VERSION ""

NS_ :

BS_:

BU_: WRCS SRS LECM3 LECM1 ECUspare6 CMS CIOM CCM AlcoLock2

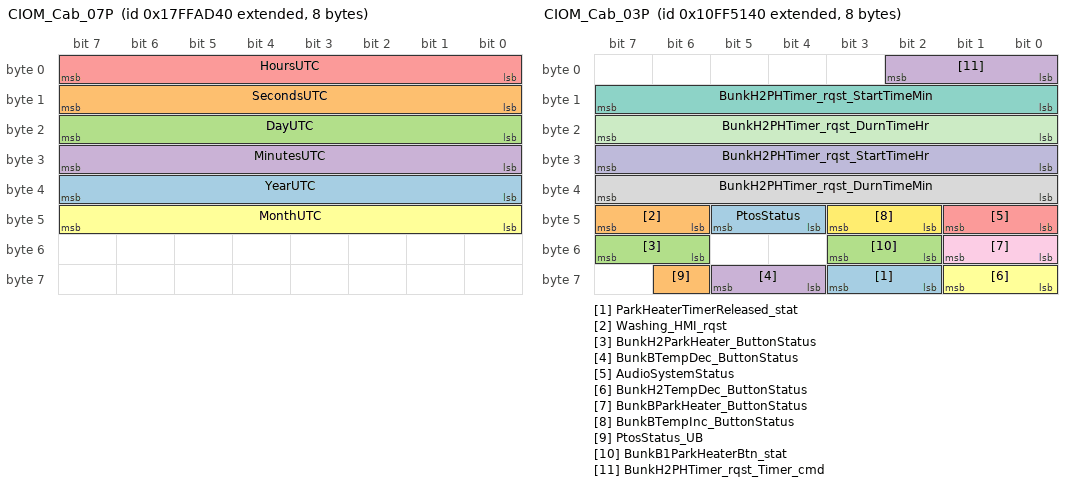
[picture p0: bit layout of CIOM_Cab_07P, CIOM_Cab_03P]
BO_ 2550115648 CIOM_Cab_07P: 8 CIOM
 SG_ YearUTC : 32|8@1+ (1,1985) [1985|2240] "Years"  LECM1,LECM3,WRCS,CMS,SRS,CCM,AlcoLock2
 SG_ SecondsUTC : 8|8@1+ (0.25,0) [0|63.75] "s"  LECM1,WRCS,CCM,LECM3,CMS,AlcoLock2,SRS
 SG_ DayUTC : 16|8@1+ (0.25,0) [0|63.75] "Days"  WRCS,CMS,LECM3,AlcoLock2,SRS,LECM1,CCM
 SG_ MinutesUTC : 24|8@1+ (1,0) [0|255] "min"  LECM1,LECM3,CCM,WRCS,SRS,CMS,AlcoLock2
 SG_ HoursUTC : 0|8@1+ (1,0) [0|255] "h"  CMS,LECM1,WRCS,LECM3,SRS,CCM,AlcoLock2
 SG_ MonthUTC : 40|8@1+ (1,0) [0|255] "Months"  WRCS,SRS,CCM,AlcoLock2,CMS,LECM3,LECM1

BO_ 2432669248 CIOM_Cab_06P: 8 CIOM
 SG_ AuxSwitchBbLoad2_Status : 22|2@1+ (1,0) [0|0] ""  WRCS
 SG_ DoorLock_stat : 24|4@1+ (1,0) [0|0] ""  LECM1,WRCS,CMS
 SG_ PSWindowPosition : 8|3@1+ (1,0) [0|0] ""  CCM
 SG_ AuxSwitchBbLoad1_Status : 14|2@1+ (1,0) [0|0] ""  WRCS
 SG_ ReducedLoadMode_stat : 0|2@1+ (1,0) [0|0] ""  CCM
 SG_ TrailersConnected : 58|3@1+ (1,0) [0|7] "Count"  WRCS,CMS
 SG_ DriverDoorAjar_stat : 4|3@1+ (1,0) [0|0] ""  CCM
 SG_ AuxSwitchBbLoad6_Status : 56|2@1+ (1,0) [0|0] ""  WRCS
 SG_ BunkBacklightCmd : 32|5@1+ (1,0) [0|0] ""  LECM1
 SG_ AuxSwitchBbLoad4_Status : 46|2@1+ (1,0) [0|0] ""  WRCS
 SG_ DSWindowPosition : 11|3@1+ (1,0) [0|0] ""  CCM
 SG_ SelectedLanguage_stat : 40|6@1+ (1,0) [0|0] ""  LECM1,WRCS
 SG_ PassengerDoorAjar_stat : 19|3@1+ (1,0) [0|0] ""  CCM
 SG_ BunkB1ParkHeaterTempSw_stat : 16|3@1+ (1,0) [0|0] ""  CCM
 SG_ AuxSwitchBbLoad5_Status : 54|2@1+ (1,0) [0|0] ""  WRCS
 SG_ AuxSwitchBbLoad3_Status : 37|2@1+ (1,0) [0|0] ""  WRCS
 SG_ BunkH2TempInc_ButtonStatus : 2|2@1+ (1,0) [0|0] ""  CCM
 SG_ AudioVolumeIndicationCmd : 48|6@1+ (1,0) [0|63] "Step"  LECM3,LECM1
 SG_ DayOfWeek_stat : 28|4@1+ (1,0) [0|0] ""  CCM,LECM1

BO_ 2432651584 CIOM_Cab_03P: 8 CIOM
 SG_ ParkHeaterTimerReleased_stat : 58|2@1+ (1,0) [0|0] ""  CCM
 SG_ Washing_HMI_rqst : 46|2@1+ (1,0) [0|0] ""  CCM
 SG_ BunkH2ParkHeater_ButtonStatus : 54|2@1+ (1,0) [0|0] ""  CCM
 SG_ BunkBTempDec_ButtonStatus : 60|2@1+ (1,0) [0|0] ""  CCM
 SG_ AudioSystemStatus : 40|2@1+ (1,0) [0|0] ""  LECM3,LECM1
 SG_ BunkH2TempDec_ButtonStatus : 56|2@1+ (1,0) [0|0] ""  CCM
 SG_ BunkH2PHTimer_rqst_StartTimeMin : 8|8@1+ (1,0) [0|255] "min"  CCM
 SG_ BunkH2PHTimer_rqst_DurnTimeMin : 32|8@1+ (1,0) [0|255] "min"  CCM
 SG_ BunkBParkHeater_ButtonStatus : 48|2@1+ (1,0) [0|0] ""  CCM
 SG_ BunkH2PHTimer_rqst_StartTimeHr : 24|8@1+ (1,0) [0|255] "h"  CCM
 SG_ BunkH2PHTimer_rqst_DurnTimeHr : 16|8@1+ (1,0) [0|255] "h"  CCM
 SG_ BunkBTempInc_ButtonStatus : 42|2@1+ (1,0) [0|0] ""  CCM
 SG_ PtosStatus : 44|2@1+ (1,0) [0|0] ""  CCM
 SG_ PtosStatus_UB : 62|1@1+ (1,0) [0|0] ""  CCM
 SG_ BunkB1ParkHeaterBtn_stat : 50|2@1+ (1,0) [0|0] ""  CCM
 SG_ BunkH2PHTimer_rqst_Timer_cmd : 0|3@1+ (1,0) [0|0] ""  CCM

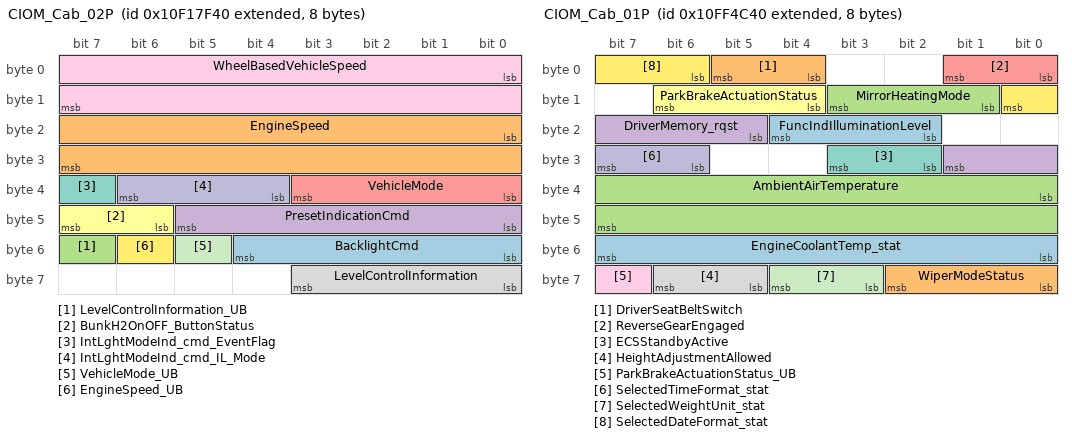
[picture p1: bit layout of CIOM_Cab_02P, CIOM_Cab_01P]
BO_ 2431745856 CIOM_Cab_02P: 8 CIOM
 SG_ BacklightCmd : 48|5@1+ (1,0) [0|0] ""  CMS,CCM
 SG_ EngineSpeed : 16|16@1+ (0.125,0) [0|8191.875] "rpm"  WRCS,CCM,SRS
 SG_ LevelControlInformation_UB : 55|1@1+ (1,0) [0|0] ""  WRCS
 SG_ PresetIndicationCmd : 40|6@1+ (1,0) [0|63] "Enumeration"  LECM1
 SG_ VehicleMode : 32|4@1+ (1,0) [0|0] ""  LECM3,WRCS,LECM1,CMS,CCM,SRS
 SG_ BunkH2OnOFF_ButtonStatus : 46|2@1+ (1,0) [0|0] ""  CCM
 SG_ IntLghtModeInd_cmd_EventFlag : 39|1@1+ (1,0) [0|0] ""  LECM1
 SG_ LevelControlInformation : 56|4@1+ (1,0) [0|0] ""  WRCS
 SG_ WheelBasedVehicleSpeed : 0|16@1+ (0.00390625,0) [0|255.99609375] "Km_per_h"  CMS,CCM,SRS,WRCS
 SG_ IntLghtModeInd_cmd_IL_Mode : 36|3@1+ (1,0) [0|0] ""  LECM1
 SG_ VehicleMode_UB : 53|1@1+ (1,0) [0|0] ""  CCM,LECM3,WRCS,SRS,LECM1,CMS
 SG_ EngineSpeed_UB : 54|1@1+ (1,0) [0|0] ""  CCM,SRS,WRCS

BO_ 2432650304 CIOM_Cab_01P: 8 CIOM
 SG_ EngineCoolantTemp_stat : 48|8@1+ (1,-40) [-40|215] "DegreeC"  CCM
 SG_ DriverSeatBeltSwitch : 4|2@1+ (1,0) [0|0] ""  SRS
 SG_ AmbientAirTemperature : 32|16@1+ (0.03125,-273) [-273|1774.96875] "DegreeC"  CMS,LECM1,LECM3,CCM,WRCS,SRS
 SG_ DriverMemory_rqst : 21|5@1+ (1,0) [0|0] ""  CMS,CCM
 SG_ ReverseGearEngaged : 0|2@1+ (1,0) [0|0] ""  CCM
 SG_ ParkBrakeActuationStatus : 12|3@1+ (1,0) [0|0] ""  CCM,CMS
 SG_ ECSStandbyActive : 26|2@1+ (1,0) [0|0] ""  WRCS
 SG_ HeightAdjustmentAllowed : 61|2@1+ (1,0) [0|0] ""  WRCS
 SG_ ParkBrakeActuationStatus_UB : 63|1@1+ (1,0) [0|0] ""  CMS,CCM
 SG_ SelectedTimeFormat_stat : 30|2@1+ (1,0) [0|0] ""  LECM1,LECM3
 SG_ SelectedWeightUnit_stat : 59|2@1+ (1,0) [0|0] ""  LECM3,WRCS
 SG_ SelectedDateFormat_stat : 6|3@1+ (1,0) [0|0] ""  LECM3
 SG_ FuncIndIlluminationLevel : 18|3@1+ (1,0) [0|0] ""  CCM
 SG_ WiperModeStatus : 56|3@1+ (1,0) [0|0] ""  CCM
 SG_ MirrorHeatingMode : 9|3@1+ (1,0) [0|0] ""  CCM

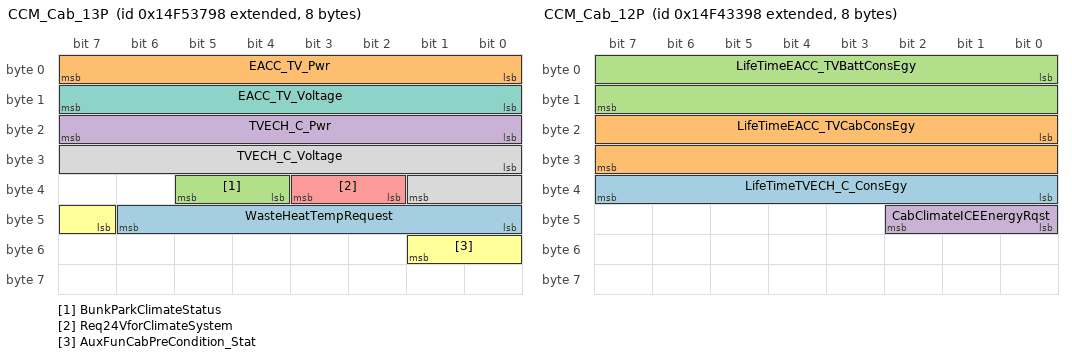
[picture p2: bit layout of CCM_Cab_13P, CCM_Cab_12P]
BO_ 2499098520 CCM_Cab_13P: 8 CCM
 SG_ WasteHeatTempRequest : 40|7@1+ (1,0) [0|127] "DegreeC"  CIOM
 SG_ EACC_TV_Pwr : 0|8@1+ (100,0) [0|25500] "W"  CIOM
 SG_ BunkParkClimateStatus : 36|2@1+ (1,0) [0|0] ""  CIOM
 SG_ TVECH_C_Pwr : 16|8@1+ (100,0) [0|25500] "W"  CIOM
 SG_ Req24VforClimateSystem : 34|2@1+ (1,0) [0|0] ""  CIOM
 SG_ AuxFunCabPreCondition_Stat : 47|3@1+ (1,0) [0|0] ""  CIOM
 SG_ EACC_TV_Voltage : 8|8@1+ (5,0) [0|1275] "V"  CIOM
 SG_ TVECH_C_Voltage : 24|10@1+ (1,0) [0|1023] "V"  CIOM

BO_ 2499031960 CCM_Cab_12P: 8 CCM
 SG_ LifeTimeTVECH_C_ConsEgy : 32|8@1+ (50,0) [0|12750] "Wh"  CIOM
 SG_ LifeTimeEACC_TVCabConsEgy : 16|16@1+ (2.5,0) [0|163837.5] "Wh"  CIOM
 SG_ LifeTimeEACC_TVBattConsEgy : 0|16@1+ (2.5,0) [0|163837.5] "Wh"  CIOM
 SG_ CabClimateICEEnergyRqst : 40|3@1+ (1,0) [0|0] ""  CIOM

BO_ 2566356888 CCM_Cab_11P: 8 CCM
 SG_ ACStatus : 36|2@1+ (1,0) [0|0] ""  CIOM
 SG_ ClimateAirDistStatus_Defrost : 11|4@1+ (1,0) [0|15] "NotApplicable"  CIOM
 SG_ HVACBlowerLevelStat_AutoStatus : 26|2@1+ (1,0) [0|0] ""  CIOM
 SG_ MaxDefrostStatus : 34|2@1+ (1,0) [0|0] ""  CIOM
 SG_ ClimateAirDistStatus_Floor : 7|4@1+ (1,0) [0|15] "NotApplicable"  CIOM
 SG_ BunkHVACBlwrLvlStat_AutoStatus : 5|2@1+ (1,0) [0|0] ""  CIOM
 SG_ ClimateAirDistStatus_AutoStatus : 19|2@1+ (1,0) [0|0] ""  CIOM
 SG_ ClimateAirDistStatus_Vent : 15|4@1+ (1,0) [0|15] "NotApplicable"  CIOM
 SG_ CabTempStatus : 56|7@1+ (0.5,0) [0|63.5] "DegreeC"  CIOM
 SG_ ParkingClimateAvailability : 43|3@1+ (1,0) [0|0] ""  CIOM
 SG_ HVACBlowerLevelStat_BlowerLevel : 21|5@1+ (1,0) [0|31] "NotApplicable"  CIOM
 SG_ BunkClimatePowerStatus : 38|2@1+ (1,0) [0|0] ""  CIOM
 SG_ BunkTempStatus : 49|7@1+ (0.5,0) [0|63.5] "DegreeC"  CIOM
 SG_ ClimateAutoStatus : 40|3@1+ (1,0) [0|0] ""  CIOM
 SG_ BunkClimateAutoStatus : 46|3@1+ (1,0) [0|0] ""  CIOM
 SG_ BunkHVACBlwrLvlStat_BlowerLevel : 0|5@1+ (1,0) [0|31] "NotApplicable"  CIOM
 SG_ ClimatePowerStatus : 32|2@1+ (1,0) [0|0] ""  CIOM
 SG_ AirRecirculationStatus : 28|2@1+ (1,0) [0|0] ""  CIOM
 SG_ BunkACStatus : 30|2@1+ (1,0) [0|0] ""  CIOM

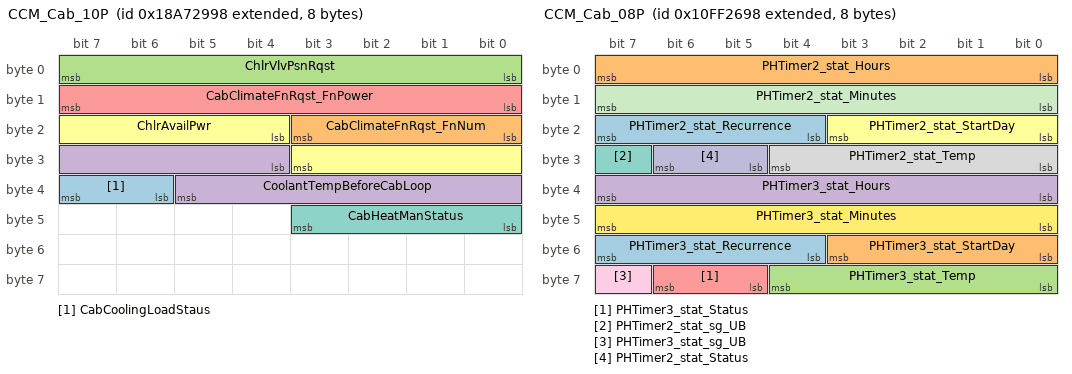
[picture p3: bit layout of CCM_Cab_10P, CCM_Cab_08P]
BO_ 2561091992 CCM_Cab_10P: 8 CCM
 SG_ CabCoolingLoadStaus : 38|2@1+ (1,0) [0|0] ""  CIOM
 SG_ CabClimateFnRqst_FnNum : 16|4@1+ (1,0) [0|15] "NotApplicable"  CIOM
 SG_ ChlrVlvPsnRqst : 0|8@1+ (1,0) [0|255] "Percent"  CIOM
 SG_ CoolantTempBeforeCabLoop : 28|10@1+ (0.1,-10) [-10|92.3] "DegreeC"  CIOM
 SG_ CabClimateFnRqst_FnPower : 8|8@1+ (1,0) [0|255] "Percent"  CIOM
 SG_ ChlrAvailPwr : 20|8@1+ (1,0) [0|255] "Percent"  CIOM
 SG_ CabHeatManStatus : 40|4@1+ (1,0) [0|15] "NotApplicable"  CIOM

BO_ 2432641688 CCM_Cab_09S: 8 CCM
 SG_ ParkClimTimerStat_Type : 10|3@1+ (1,0) [0|0] ""  CIOM
 SG_ ParkClimTimerStat_Rec : 19|1@1+ (1,0) [0|0] ""  CIOM
 SG_ ParkClimTimerStat_Tue : 15|1@1+ (1,0) [0|0] ""  CIOM
 SG_ ParkClimTimerStat_Thu : 16|1@1+ (1,0) [0|0] ""  CIOM
 SG_ ParkClimTimerStat_TimerNr : 39|8@1+ (1,0) [0|0] ""  CIOM
 SG_ ParkClimTimerStat_TotalNoTimers : 23|8@1+ (1,0) [0|0] ""  CIOM
 SG_ ParkClimTimerStat_Sat : 21|1@1+ (1,0) [0|0] ""  CIOM
 SG_ ParkClimTimerStat_Min : 55|8@1+ (1,0) [0|255] "min"  CIOM
 SG_ ParkClimTimerStat_Status : 13|2@1+ (1,0) [0|0] ""  CIOM
 SG_ ParkClimTimerStat_Wed : 22|1@1+ (1,0) [0|0] ""  CIOM
 SG_ ParkClimTimerStat_Sun : 20|1@1+ (1,0) [0|0] ""  CIOM
 SG_ ParkClimTimerStat_Hrs : 31|8@1+ (1,0) [0|255] "h"  CIOM
 SG_ ParkClimTimerStat_Temp : 47|8@1+ (0.5,0) [0|127.5] "DegreeC"  CIOM
 SG_ ParkClimTimerStat_Fri : 18|1@1+ (1,0) [0|0] ""  CIOM
 SG_ ParkClimTimerStat_Dur : 0|7@1+ (1,0) [0|127] "min"  CIOM
 SG_ ParkClimTimerStat_MinRes : 7|3@1+ (1,0) [0|0] ""  CIOM
 SG_ ParkClimTimerStat_Mon : 17|1@1+ (1,0) [0|0] ""  CIOM
 SG_ ParkClimTimerStat_sg_UB : 63|1@1+ (1,0) [0|0] ""  CIOM

BO_ 2432640664 CCM_Cab_08P: 8 CCM
 SG_ PHTimer2_stat_Recurrence : 20|4@1+ (1,0) [0|0] ""  LECM1
 SG_ PHTimer2_stat_Hours : 0|8@1+ (1,0) [0|255] "h"  LECM1
 SG_ PHTimer3_stat_Temp : 56|5@1+ (1,0) [0|0] ""  LECM1
 SG_ PHTimer3_stat_Hours : 32|8@1+ (1,0) [0|255] "h"  LECM1
 SG_ PHTimer3_stat_Status : 61|2@1+ (1,0) [0|0] ""  LECM1
 SG_ PHTimer2_stat_StartDay : 16|4@1+ (1,0) [0|0] ""  LECM1
 SG_ PHTimer2_stat_sg_UB : 31|1@1+ (1,0) [0|0] ""  LECM1
 SG_ PHTimer2_stat_Temp : 24|5@1+ (1,0) [0|0] ""  LECM1
 SG_ PHTimer3_stat_sg_UB : 63|1@1+ (1,0) [0|0] ""  LECM1
 SG_ PHTimer2_stat_Status : 29|2@1+ (1,0) [0|0] ""  LECM1
 SG_ PHTimer2_stat_Minutes : 8|8@1+ (1,0) [0|255] "min"  LECM1
 SG_ PHTimer3_stat_Minutes : 40|8@1+ (1,0) [0|255] "min"  LECM1
 SG_ PHTimer3_stat_Recurrence : 52|4@1+ (1,0) [0|0] ""  LECM1
 SG_ PHTimer3_stat_StartDay : 48|4@1+ (1,0) [0|0] ""  LECM1

BO_ 2432644760 CCM_Cab_07P: 8 CCM
 SG_ PHTimer1_stat_Minutes : 8|8@1+ (1,0) [0|255] "min"  LECM1,CIOM
 SG_ ExtraHeating_status : 42|2@1+ (1,0) [0|0] ""  CIOM
 SG_ AQSmode_Status : 56|2@1+ (1,0) [0|0] ""  CIOM
 SG_ ParkingClimate_IndicationCmd : 39|3@1+ (1,0) [0|0] ""  CIOM
 SG_ ACmode_Status : 53|3@1+ (1,0) [0|0] ""  CIOM
 SG_ PHTimer1_stat_sg_UB : 38|1@1+ (1,0) [0|0] ""  LECM1,CIOM
 SG_ ShortStopHeater_cmd : 44|2@1+ (1,0) [0|0] ""  CIOM
 SG_ PHTimer1_stat_Status : 31|2@1+ (1,0) [0|0] ""  LECM1,CIOM
 SG_ PHTimer1_stat_StartDay : 16|4@1+ (1,0) [0|0] ""  LECM1,CIOM
 SG_ PHTimer1_stat_Duration : 24|7@1+ (1,0) [0|127] "min"  LECM1,CIOM
 SG_ ReqVehTVSforClimateSystem : 48|2@1+ (1,0) [0|0] ""  CIOM
 SG_ AutoBlowerLevel_Status : 58|3@1+ (1,0) [0|0] ""  CIOM
 SG_ PHTimer1_stat_Temp : 33|5@1+ (1,0) [0|0] ""  LECM1,CIOM
 SG_ PHCleanStatFeedback : 46|2@1+ (1,0) [0|0] ""  CIOM
 SG_ PHTimer1_stat_Recurrence : 20|4@1+ (1,0) [0|0] ""  CIOM,LECM1
 SG_ PHTimer1_stat_Hours : 0|8@1+ (1,0) [0|255] "h"  LECM1,CIOM
 SG_ AutoDefogmode_Status : 61|3@1+ (1,0) [0|0] ""  CIOM

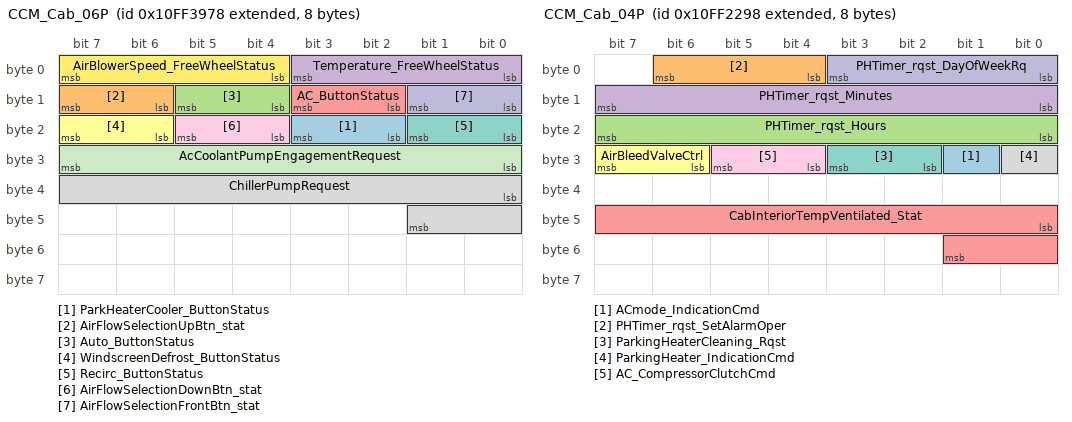
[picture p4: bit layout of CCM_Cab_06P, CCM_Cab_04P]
BO_ 2432645496 CCM_Cab_06P: 8 CCM
 SG_ ParkHeaterCooler_ButtonStatus : 18|2@1+ (1,0) [0|0] ""  CIOM
 SG_ AirFlowSelectionUpBtn_stat : 14|2@1+ (1,0) [0|0] ""  CIOM
 SG_ Auto_ButtonStatus : 12|2@1+ (1,0) [0|0] ""  CIOM
 SG_ Temperature_FreeWheelStatus : 0|4@1+ (1,0) [0|0] ""  CIOM
 SG_ AC_ButtonStatus : 10|2@1+ (1,0) [0|0] ""  CIOM
 SG_ WindscreenDefrost_ButtonStatus : 22|2@1+ (1,0) [0|0] ""  CIOM
 SG_ Recirc_ButtonStatus : 16|2@1+ (1,0) [0|0] ""  CIOM
 SG_ ChillerPumpRequest : 32|10@1+ (0.1,0) [0|102.3] "Percent"  CIOM
 SG_ AirFlowSelectionDownBtn_stat : 20|2@1+ (1,0) [0|0] ""  CIOM
 SG_ AirFlowSelectionFrontBtn_stat : 8|2@1+ (1,0) [0|0] ""  CIOM
 SG_ AcCoolantPumpEngagementRequest : 24|8@1+ (0.4,0) [0|102] "Percent"  CIOM
 SG_ AirBlowerSpeed_FreeWheelStatus : 4|4@1+ (1,0) [0|0] ""  CIOM

BO_ 2432639640 CCM_Cab_04P: 8 CCM
 SG_ ACmode_IndicationCmd : 25|1@1+ (1,0) [0|0] ""  CIOM
 SG_ PHTimer_rqst_SetAlarmOper : 4|3@1+ (1,0) [0|0] ""  CIOM
 SG_ PHTimer_rqst_Hours : 16|8@1+ (1,0) [0|255] "h"  CIOM
 SG_ PHTimer_rqst_Minutes : 8|8@1+ (1,0) [0|255] "min"  CIOM
 SG_ CabInteriorTempVentilated_Stat : 40|10@1+ (0.125,-40) [-40|87.875] "DegreeC"  CIOM
 SG_ AirBleedValveCtrl : 30|2@1+ (1,0) [0|0] ""  CIOM
 SG_ ParkingHeaterCleaning_Rqst : 26|2@1+ (1,0) [0|0] ""  CIOM
 SG_ ParkingHeater_IndicationCmd : 24|1@1+ (1,0) [0|0] ""  LECM1,CIOM
 SG_ AC_CompressorClutchCmd : 28|2@1+ (1,0) [0|0] ""  CIOM
 SG_ PHTimer_rqst_DayOfWeekRq : 0|4@1+ (1,0) [0|0] ""  CIOM

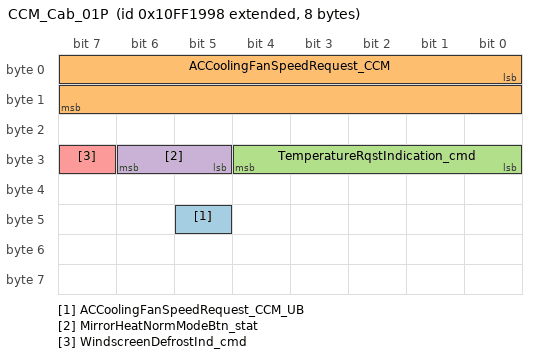
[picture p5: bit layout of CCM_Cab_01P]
BO_ 2432637336 CCM_Cab_01P: 8 CCM
 SG_ ACCoolingFanSpeedRequest_CCM_UB : 45|1@1+ (1,0) [0|0] ""  CIOM
 SG_ ACCoolingFanSpeedRequest_CCM : 0|16@1+ (1,0) [0|65535] "rpm"  CIOM
 SG_ TemperatureRqstIndication_cmd : 24|5@1+ (1,0) [0|0] ""  LECM1,CIOM
 SG_ MirrorHeatNormModeBtn_stat : 29|2@1+ (1,0) [0|0] ""  CIOM
 SG_ WindscreenDefrostInd_cmd : 31|1@1+ (1,0) [0|0] ""  CIOM

BO_ 2633994283 AnmMsg_WRCS_CabSubnet: 4 WRCS
 SG_ AnmSig_WRCS_CabSubnet : 0|32@1+ (1,0) [0|4294967295] ""  ECUspare6,LECM1,CMS,CCM,LECM3,SRS,CIOM

BO_ 2633994282 AnmMsg_SRS_CabSubnet: 4 SRS
 SG_ AnmSig_SRS_CabSubnet : 0|32@1+ (1,0) [0|4294967295] ""  CMS,CIOM,LECM1,WRCS,CCM,ECUspare6,LECM3

BO_ 2633994280 AnmMsg_LECM1_CabSubnet: 4 LECM3
 SG_ AnmSig_LECM1_CabSubnet : 0|32@1+ (1,0) [0|4294967295] ""  SRS,WRCS,CCM,CMS,ECUspare6,CIOM

BO_ 2633994320 AnmMsg_ECUspare6_CabSubnet: 4 ECUspare6
 SG_ AnmSig_ECUspare6_CabSubnet : 0|32@1+ (1,0) [0|4294967295] ""  SRS,LECM3,LECM1,CCM,WRCS,CIOM,CMS

BO_ 2633994326 AnmMsg_CMS_CabSubnet: 4 CMS
 SG_ AnmSig_CMS_CabSubnet : 0|32@1+ (1,0) [0|4294967295] ""  WRCS,LECM1,SRS,CCM,LECM3,ECUspare6,CIOM

BO_ 2633994278 AnmMsg_CIOM_CabSubnet: 4 CIOM
 SG_ AnmSig_CIOM_CabSubnet : 0|32@1+ (1,0) [0|4294967295] ""  CMS,ECUspare6,WRCS,LECM1,CCM,LECM3,SRS

BO_ 2633994277 AnmMsg_CCM_CabSubnet: 4 CCM
 SG_ AnmSig_CCM_CabSubnet : 0|32@1+ (1,0) [0|4294967295] ""  LECM1,CIOM,SRS,LECM3,ECUspare6,CMS,WRCS

BO_TX_BU_ 2633994280 : LECM1,LECM3;
CM_ SG_ 2550115648 YearUTC "254 Error ; 255 Not available";
CM_ SG_ 2550115648 SecondsUTC "254 Error ; 255 Not available";
CM_ SG_ 2550115648 DayUTC "254 Error ; 255 Not available";
CM_ SG_ 2550115648 MinutesUTC "254 Error ; 255 Not available";
CM_ SG_ 2550115648 HoursUTC "254 Error ; 255 Not available";
CM_ SG_ 2550115648 MonthUTC "254 Error ; 255 Not available";
CM_ SG_ 2432669248 TrailersConnected "6 Error ; 7 Not available";
CM_ SG_ 2432651584 BunkH2PHTimer_rqst_StartTimeMin "254 Error ; 255 Not available";
CM_ SG_ 2432651584 BunkH2PHTimer_rqst_DurnTimeMin "254 Error ; 255 Not available";
CM_ SG_ 2432651584 BunkH2PHTimer_rqst_StartTimeHr "254 Error ; 255 Not available";
CM_ SG_ 2432651584 BunkH2PHTimer_rqst_DurnTimeHr "254 Error ; 255 Not available";
CM_ SG_ 2431745856 EngineSpeed "65024 - 65279 Error ; 65280 - 65535 Not available";
CM_ SG_ 2431745856 PresetIndicationCmd "62 Error ; 63 Not Available";
CM_ SG_ 2431745856 WheelBasedVehicleSpeed "65024 - 65279 Error ; 65280 - 65535 Not available";
CM_ SG_ 2432650304 EngineCoolantTemp_stat "254 Error ; 255 Not available";
CM_ SG_ 2432650304 AmbientAirTemperature "65024 - 65279 Error ; 65280 - 65535 Not available";
CM_ SG_ 2432639640 PHTimer_rqst_Hours "254 Error ; 255 Not available";
CM_ SG_ 2432639640 PHTimer_rqst_Minutes "254 Error ; 255 Not available";
CM_ SG_ 2432639640 CabInteriorTempVentilated_Stat "1022 Error; 1023 Not Available";
BA_DEF_ BO_  "GenMsgStartDelayTime" INT 0 0;
BA_DEF_ BO_  "GenMsgDelayTime" INT 0 0;
BA_DEF_ BO_  "GenMsgCycleTime" INT 0 0;
BA_DEF_ BO_  "GenMsgSendType" ENUM  "Cyclic","NotUsed","NotUsed","NotUsed","NotUsed","NotUsed","NotUsed","IfActive","NoMsgSendType","NotUsed";
BA_DEF_ SG_  "GenSigStartValue" INT 0 0;
BA_DEF_ SG_  "GenSigCycleTimeActive" INT 0 0;
BA_DEF_ SG_  "GenSigCycleTime" INT 0 0;
BA_DEF_ SG_  "GenSigSendType" ENUM  "Cyclic","OnWrite","OnWriteWithRepetition","OnChange","OnChangeWithRepetition","IfActive","IfActiveWithRepetition","NoSigSendType","NotUsed","NotUsed","NotUsed","NotUsed","NotUsed";
BA_DEF_ BO_  "VFrameFormat" ENUM  "StandardCAN","ExtendedCAN","reserved","J1939PG","reserved","reserved","reserved","reserved","reserved","reserved","reserved","reserved","reserved","reserved","StandardCAN_FD","ExtendedCAN_FD";
BA_DEF_ SG_  "SigType" ENUM  "Default","Range","RangeSigned","ASCII","Discrete","Control","ReferencePGN","DTC","StringDelimiter","StringLength","StringLengthControl";
BA_DEF_ SG_  "SeToolVersion_SIGNAL" STRING ;
BA_DEF_ SG_  "SeToolUniqueID_SIGNAL" STRING ;
BA_DEF_ SG_  "SeToolOwnerSigGroup_SIGNAL" STRING ;
BA_DEF_ SG_  "SeToolOwnerSigGroupID_SIGNAL" STRING ;
BA_DEF_ SG_  "SeToolName_SIGNAL" STRING ;
BA_DEF_ SG_  "SeToolItemID_SIGNAL" STRING ;
BA_DEF_ SG_  "SeToolAncestorID_SIGNAL" STRING ;
BA_DEF_ SG_  "Platform_VMCU1_Sig" ENUM  "No","Yes";
BA_DEF_ BO_  "NmAsrMessage" ENUM  "No","Yes";
BA_DEF_ SG_  "NeedsUpdateBit" ENUM  "No","Yes";
BA_DEF_ SG_  "MmAnSignal" ENUM  "No","Yes";
BA_DEF_ SG_  "GenSigMaxLatency" INT 0 65535;
BA_DEF_ SG_  "GenSigILSupport" ENUM  "Yes","No";
BA_DEF_ BO_  "GenMsgILSupport" ENUM  "No","Yes";
BA_DEF_ SG_  "E2EProfile" STRING ;
BA_DEF_ SG_  "E2EDataLength" INT 0 65535;
BA_DEF_ SG_  "E2EDataId" INT 0 65535;
BA_DEF_ BO_  "DiagUUDTResponse" ENUM  "No","Yes";
BA_DEF_ BO_  "DiagState" ENUM  "No","Yes";
BA_DEF_ BO_  "DiagResponse" ENUM  "No","Yes";
BA_DEF_ BO_  "DiagRequest" ENUM  "No","Yes";
BA_DEF_ BO_  "DiagConnection" HEX 0 65535;
BA_DEF_ BO_  "CanTpSTmin" INT 0 255;
BA_DEF_ BO_  "CanTpFcFrameId" HEX 0 2147483647;
BA_DEF_ BO_  "CanTpBs" INT 0 255;
BA_DEF_REL_ BU_SG_REL_  "GenSigTimeoutTime" INT 0 65535;
BA_DEF_REL_ BU_SG_REL_  "GenSigFirstTimeoutTime" INT 0 65535;
BA_DEF_DEF_  "GenMsgStartDelayTime" 0;
BA_DEF_DEF_  "GenMsgDelayTime" 0;
BA_DEF_DEF_  "GenMsgCycleTime" 0;
BA_DEF_DEF_  "GenMsgSendType" "Cyclic";
BA_DEF_DEF_  "GenSigStartValue" 0;
BA_DEF_DEF_  "GenSigCycleTimeActive" 0;
BA_DEF_DEF_  "GenSigCycleTime" 0;
BA_DEF_DEF_  "GenSigSendType" "Cyclic";
BA_DEF_DEF_  "VFrameFormat" "ExtendedCAN";
BA_DEF_DEF_  "SigType" "Default";
BA_DEF_DEF_  "SeToolVersion_SIGNAL" "";
BA_DEF_DEF_  "SeToolUniqueID_SIGNAL" "";
BA_DEF_DEF_  "SeToolOwnerSigGroup_SIGNAL" "";
BA_DEF_DEF_  "SeToolOwnerSigGroupID_SIGNAL" "";
BA_DEF_DEF_  "SeToolName_SIGNAL" "";
BA_DEF_DEF_  "SeToolItemID_SIGNAL" "";
BA_DEF_DEF_  "SeToolAncestorID_SIGNAL" "";
BA_DEF_DEF_  "Platform_VMCU1_Sig" "No";
BA_DEF_DEF_  "NmAsrMessage" "No";
BA_DEF_DEF_  "NeedsUpdateBit" "No";
BA_DEF_DEF_  "MmAnSignal" "No";
BA_DEF_DEF_  "GenSigMaxLatency" 0;
BA_DEF_DEF_  "GenSigILSupport" "Yes";
BA_DEF_DEF_  "GenMsgILSupport" "Yes";
BA_DEF_DEF_  "E2EProfile" "none";
BA_DEF_DEF_  "E2EDataLength" 0;
BA_DEF_DEF_  "E2EDataId" 0;
BA_DEF_DEF_  "DiagUUDTResponse" "No";
BA_DEF_DEF_  "DiagState" "No";
BA_DEF_DEF_  "DiagResponse" "No";
BA_DEF_DEF_  "DiagRequest" "No";
BA_DEF_DEF_  "DiagConnection" 0;
BA_DEF_DEF_  "CanTpSTmin" 0;
BA_DEF_DEF_  "CanTpFcFrameId" 2147483647;
BA_DEF_DEF_  "CanTpBs" 255;
BA_DEF_DEF_REL_ "GenSigTimeoutTime" 0;
BA_DEF_DEF_REL_ "GenSigFirstTimeoutTime" 0;
BA_ "GenMsgCycleTime" BO_ 2550115648 250;
BA_ "GenMsgStartDelayTime" BO_ 2550115648 150;
BA_ "GenMsgCycleTime" BO_ 2432669248 20;
BA_ "GenMsgStartDelayTime" BO_ 2432669248 10;
BA_ "GenMsgCycleTime" BO_ 2432651584 20;
BA_ "GenMsgStartDelayTime" BO_ 2432651584 15;
BA_ "GenMsgCycleTime" BO_ 2431745856 10;
BA_ "GenMsgCycleTime" BO_ 2432650304 20;
BA_ "GenMsgCycleTime" BO_ 2499098520 100;
BA_ "GenMsgStartDelayTime" BO_ 2499098520 40;
BA_ "GenMsgCycleTime" BO_ 2499031960 100;
BA_ "GenMsgStartDelayTime" BO_ 2499031960 25;
BA_ "GenMsgCycleTime" BO_ 2566356888 500;
BA_ "GenMsgDelayTime" BO_ 2566356888 50;
BA_ "GenMsgStartDelayTime" BO_ 2566356888 15;
BA_ "GenMsgCycleTime" BO_ 2561091992 1000;
BA_ "GenMsgStartDelayTime" BO_ 2561091992 30;
BA_ "GenMsgSendType" BO_ 2432641688 8;
BA_ "GenMsgDelayTime" BO_ 2432641688 20;
BA_ "GenMsgCycleTime" BO_ 2432640664 50;
BA_ "GenMsgStartDelayTime" BO_ 2432640664 25;
BA_ "GenMsgCycleTime" BO_ 2432644760 50;
BA_ "GenMsgCycleTime" BO_ 2432645496 20;
BA_ "GenMsgStartDelayTime" BO_ 2432645496 10;
BA_ "GenMsgCycleTime" BO_ 2432639640 20;
BA_ "GenMsgCycleTime" BO_ 2432637336 20;
BA_ "GenMsgStartDelayTime" BO_ 2432637336 5;
BA_ "GenMsgCycleTime" BO_ 2633994283 100;
BA_ "GenMsgCycleTime" BO_ 2633994282 100;
BA_ "GenMsgCycleTime" BO_ 2633994280 100;
BA_ "GenMsgCycleTime" BO_ 2633994320 100;
BA_ "GenMsgCycleTime" BO_ 2633994326 100;
BA_ "GenMsgCycleTime" BO_ 2633994278 100;
BA_ "GenMsgStartDelayTime" BO_ 2633994278 10;
BA_ "GenMsgCycleTime" BO_ 2633994277 100;
BA_ "GenMsgStartDelayTime" BO_ 2633994277 10;
BA_ "GenSigCycleTime" SG_ 2550115648 YearUTC 100;
BA_ "GenSigCycleTimeActive" SG_ 2550115648 YearUTC 100;
BA_ "GenSigStartValue" SG_ 2550115648 YearUTC 255;
BA_ "SeToolAncestorID_SIGNAL" SG_ 2550115648 YearUTC "x0000001D0412FACB";
BA_ "SeToolItemID_SIGNAL" SG_ 2550115648 YearUTC "x0000001D041EBCEF";
BA_ "SeToolName_SIGNAL" SG_ 2550115648 YearUTC "YearUTC";
BA_ "SeToolVersion_SIGNAL" SG_ 2550115648 YearUTC "2";
BA_ "GenSigCycleTime" SG_ 2550115648 SecondsUTC 100;
BA_ "GenSigCycleTimeActive" SG_ 2550115648 SecondsUTC 100;
BA_ "GenSigStartValue" SG_ 2550115648 SecondsUTC 255;
BA_ "SeToolAncestorID_SIGNAL" SG_ 2550115648 SecondsUTC "x0000001D0412FABE";
BA_ "SeToolItemID_SIGNAL" SG_ 2550115648 SecondsUTC "x0000001D041EBD32";
BA_ "SeToolName_SIGNAL" SG_ 2550115648 SecondsUTC "SecondsUTC";
BA_ "SeToolVersion_SIGNAL" SG_ 2550115648 SecondsUTC "2";
BA_ "GenSigCycleTime" SG_ 2550115648 DayUTC 100;
BA_ "GenSigCycleTimeActive" SG_ 2550115648 DayUTC 100;
BA_ "GenSigStartValue" SG_ 2550115648 DayUTC 255;
BA_ "SeToolAncestorID_SIGNAL" SG_ 2550115648 DayUTC "x0000001D0412FAC4";
BA_ "SeToolItemID_SIGNAL" SG_ 2550115648 DayUTC "x0000001D041EBD81";
BA_ "SeToolName_SIGNAL" SG_ 2550115648 DayUTC "DayUTC";
BA_ "SeToolVersion_SIGNAL" SG_ 2550115648 DayUTC "2";
BA_ "GenSigCycleTime" SG_ 2550115648 MinutesUTC 100;
BA_ "GenSigCycleTimeActive" SG_ 2550115648 MinutesUTC 100;
BA_ "GenSigStartValue" SG_ 2550115648 MinutesUTC 255;
BA_ "SeToolAncestorID_SIGNAL" SG_ 2550115648 MinutesUTC "x0000001D0412FAC0";
BA_ "SeToolItemID_SIGNAL" SG_ 2550115648 MinutesUTC "x0000001D041EBD29";
BA_ "SeToolName_SIGNAL" SG_ 2550115648 MinutesUTC "MinutesUTC";
BA_ "SeToolVersion_SIGNAL" SG_ 2550115648 MinutesUTC "2";
BA_ "GenSigCycleTime" SG_ 2550115648 HoursUTC 100;
BA_ "GenSigCycleTimeActive" SG_ 2550115648 HoursUTC 100;
BA_ "GenSigStartValue" SG_ 2550115648 HoursUTC 255;
BA_ "SeToolAncestorID_SIGNAL" SG_ 2550115648 HoursUTC "x0000001D0412FAC2";
BA_ "SeToolItemID_SIGNAL" SG_ 2550115648 HoursUTC "x0000001D041EBD20";
BA_ "SeToolName_SIGNAL" SG_ 2550115648 HoursUTC "HoursUTC";
BA_ "SeToolVersion_SIGNAL" SG_ 2550115648 HoursUTC "2";
BA_ "GenSigCycleTime" SG_ 2550115648 MonthUTC 100;
BA_ "GenSigCycleTimeActive" SG_ 2550115648 MonthUTC 100;
BA_ "GenSigStartValue" SG_ 2550115648 MonthUTC 255;
BA_ "SeToolAncestorID_SIGNAL" SG_ 2550115648 MonthUTC "x0000001D0412FAC9";
BA_ "SeToolItemID_SIGNAL" SG_ 2550115648 MonthUTC "x0000001D041EBD16";
BA_ "SeToolName_SIGNAL" SG_ 2550115648 MonthUTC "MonthUTC";
BA_ "SeToolVersion_SIGNAL" SG_ 2550115648 MonthUTC "2";
BA_ "GenSigCycleTime" SG_ 2432669248 AuxSwitchBbLoad2_Status 100;
BA_ "GenSigCycleTimeActive" SG_ 2432669248 AuxSwitchBbLoad2_Status 100;
BA_ "GenSigStartValue" SG_ 2432669248 AuxSwitchBbLoad2_Status 3;
BA_ "GenSigCycleTime" SG_ 2432669248 DoorLock_stat 100;
BA_ "GenSigCycleTimeActive" SG_ 2432669248 DoorLock_stat 100;
BA_ "GenSigStartValue" SG_ 2432669248 DoorLock_stat 15;
BA_ "GenSigMaxLatency" SG_ 2432669248 DoorLock_stat 26;
BA_ "GenSigCycleTime" SG_ 2432669248 PSWindowPosition 100;
BA_ "GenSigCycleTimeActive" SG_ 2432669248 PSWindowPosition 100;
BA_ "GenSigStartValue" SG_ 2432669248 PSWindowPosition 7;
BA_ "GenSigMaxLatency" SG_ 2432669248 PSWindowPosition 26;
BA_ "GenSigCycleTime" SG_ 2432669248 AuxSwitchBbLoad1_Status 100;
BA_ "GenSigCycleTimeActive" SG_ 2432669248 AuxSwitchBbLoad1_Status 100;
BA_ "GenSigStartValue" SG_ 2432669248 AuxSwitchBbLoad1_Status 3;
BA_ "GenSigCycleTime" SG_ 2432669248 ReducedLoadMode_stat 100;
BA_ "GenSigCycleTimeActive" SG_ 2432669248 ReducedLoadMode_stat 100;
BA_ "GenSigStartValue" SG_ 2432669248 ReducedLoadMode_stat 3;
BA_ "GenSigCycleTime" SG_ 2432669248 TrailersConnected 100;
BA_ "GenSigCycleTimeActive" SG_ 2432669248 TrailersConnected 100;
BA_ "GenSigStartValue" SG_ 2432669248 TrailersConnected 7;
BA_ "GenSigCycleTime" SG_ 2432669248 DriverDoorAjar_stat 100;
BA_ "GenSigCycleTimeActive" SG_ 2432669248 DriverDoorAjar_stat 100;
BA_ "GenSigStartValue" SG_ 2432669248 DriverDoorAjar_stat 7;
BA_ "GenSigMaxLatency" SG_ 2432669248 DriverDoorAjar_stat 26;
BA_ "GenSigCycleTime" SG_ 2432669248 AuxSwitchBbLoad6_Status 100;
BA_ "GenSigCycleTimeActive" SG_ 2432669248 AuxSwitchBbLoad6_Status 100;
BA_ "GenSigStartValue" SG_ 2432669248 AuxSwitchBbLoad6_Status 3;
BA_ "GenSigCycleTime" SG_ 2432669248 BunkBacklightCmd 100;
BA_ "GenSigCycleTimeActive" SG_ 2432669248 BunkBacklightCmd 100;
BA_ "GenSigMaxLatency" SG_ 2432669248 BunkBacklightCmd 26;
BA_ "GenSigCycleTime" SG_ 2432669248 AuxSwitchBbLoad4_Status 100;
BA_ "GenSigCycleTimeActive" SG_ 2432669248 AuxSwitchBbLoad4_Status 100;
BA_ "GenSigStartValue" SG_ 2432669248 AuxSwitchBbLoad4_Status 3;
BA_ "GenSigCycleTime" SG_ 2432669248 DSWindowPosition 100;
BA_ "GenSigCycleTimeActive" SG_ 2432669248 DSWindowPosition 100;
BA_ "GenSigStartValue" SG_ 2432669248 DSWindowPosition 7;
BA_ "GenSigMaxLatency" SG_ 2432669248 DSWindowPosition 26;
BA_ "GenSigCycleTime" SG_ 2432669248 SelectedLanguage_stat 100;
BA_ "GenSigCycleTimeActive" SG_ 2432669248 SelectedLanguage_stat 100;
BA_ "GenSigStartValue" SG_ 2432669248 SelectedLanguage_stat 63;
BA_ "GenSigMaxLatency" SG_ 2432669248 SelectedLanguage_stat 26;
BA_ "GenSigCycleTime" SG_ 2432669248 PassengerDoorAjar_stat 100;
BA_ "GenSigCycleTimeActive" SG_ 2432669248 PassengerDoorAjar_stat 100;
BA_ "GenSigStartValue" SG_ 2432669248 PassengerDoorAjar_stat 7;
BA_ "GenSigMaxLatency" SG_ 2432669248 PassengerDoorAjar_stat 26;
BA_ "GenSigCycleTime" SG_ 2432669248 BunkB1ParkHeaterTempSw_stat 100;
BA_ "GenSigCycleTimeActive" SG_ 2432669248 BunkB1ParkHeaterTempSw_stat 100;
BA_ "GenSigStartValue" SG_ 2432669248 BunkB1ParkHeaterTempSw_stat 7;
BA_ "GenSigMaxLatency" SG_ 2432669248 BunkB1ParkHeaterTempSw_stat 26;
BA_ "GenSigCycleTime" SG_ 2432669248 AuxSwitchBbLoad5_Status 100;
BA_ "GenSigCycleTimeActive" SG_ 2432669248 AuxSwitchBbLoad5_Status 100;
BA_ "GenSigStartValue" SG_ 2432669248 AuxSwitchBbLoad5_Status 3;
BA_ "GenSigCycleTime" SG_ 2432669248 AuxSwitchBbLoad3_Status 100;
BA_ "GenSigCycleTimeActive" SG_ 2432669248 AuxSwitchBbLoad3_Status 100;
BA_ "GenSigStartValue" SG_ 2432669248 AuxSwitchBbLoad3_Status 3;
BA_ "GenSigCycleTime" SG_ 2432669248 BunkH2TempInc_ButtonStatus 100;
BA_ "GenSigCycleTimeActive" SG_ 2432669248 BunkH2TempInc_ButtonStatus 100;
BA_ "GenSigStartValue" SG_ 2432669248 BunkH2TempInc_ButtonStatus 3;
BA_ "GenSigMaxLatency" SG_ 2432669248 BunkH2TempInc_ButtonStatus 26;
BA_ "GenSigCycleTime" SG_ 2432669248 AudioVolumeIndicationCmd 100;
BA_ "GenSigCycleTimeActive" SG_ 2432669248 AudioVolumeIndicationCmd 100;
BA_ "GenSigCycleTime" SG_ 2432669248 DayOfWeek_stat 100;
BA_ "GenSigCycleTimeActive" SG_ 2432669248 DayOfWeek_stat 100;
BA_ "GenSigStartValue" SG_ 2432669248 DayOfWeek_stat 15;
BA_ "GenSigMaxLatency" SG_ 2432669248 DayOfWeek_stat 26;
BA_ "GenSigCycleTime" SG_ 2432651584 ParkHeaterTimerReleased_stat 100;
BA_ "GenSigCycleTimeActive" SG_ 2432651584 ParkHeaterTimerReleased_stat 100;
BA_ "GenSigStartValue" SG_ 2432651584 ParkHeaterTimerReleased_stat 3;
BA_ "GenSigMaxLatency" SG_ 2432651584 ParkHeaterTimerReleased_stat 26;
BA_ "GenSigCycleTime" SG_ 2432651584 Washing_HMI_rqst 100;
BA_ "GenSigCycleTimeActive" SG_ 2432651584 Washing_HMI_rqst 100;
BA_ "GenSigStartValue" SG_ 2432651584 Washing_HMI_rqst 3;
BA_ "GenSigCycleTime" SG_ 2432651584 BunkH2ParkHeater_ButtonStatus 100;
BA_ "GenSigCycleTimeActive" SG_ 2432651584 BunkH2ParkHeater_ButtonStatus 100;
BA_ "GenSigStartValue" SG_ 2432651584 BunkH2ParkHeater_ButtonStatus 3;
BA_ "GenSigMaxLatency" SG_ 2432651584 BunkH2ParkHeater_ButtonStatus 26;
BA_ "GenSigCycleTime" SG_ 2432651584 BunkBTempDec_ButtonStatus 100;
BA_ "GenSigCycleTimeActive" SG_ 2432651584 BunkBTempDec_ButtonStatus 100;
BA_ "GenSigStartValue" SG_ 2432651584 BunkBTempDec_ButtonStatus 3;
BA_ "GenSigMaxLatency" SG_ 2432651584 BunkBTempDec_ButtonStatus 26;
BA_ "GenSigCycleTime" SG_ 2432651584 AudioSystemStatus 100;
BA_ "GenSigCycleTimeActive" SG_ 2432651584 AudioSystemStatus 100;
BA_ "GenSigStartValue" SG_ 2432651584 AudioSystemStatus 3;
BA_ "GenSigCycleTime" SG_ 2432651584 BunkH2TempDec_ButtonStatus 100;
BA_ "GenSigCycleTimeActive" SG_ 2432651584 BunkH2TempDec_ButtonStatus 100;
BA_ "GenSigStartValue" SG_ 2432651584 BunkH2TempDec_ButtonStatus 3;
BA_ "GenSigMaxLatency" SG_ 2432651584 BunkH2TempDec_ButtonStatus 26;
BA_ "GenSigCycleTime" SG_ 2432651584 BunkH2PHTimer_rqst_StartTimeMin 100;
BA_ "GenSigCycleTimeActive" SG_ 2432651584 BunkH2PHTimer_rqst_StartTimeMin 100;
BA_ "GenSigStartValue" SG_ 2432651584 BunkH2PHTimer_rqst_StartTimeMin 255;
BA_ "GenSigMaxLatency" SG_ 2432651584 BunkH2PHTimer_rqst_StartTimeMin 26;
BA_ "GenSigCycleTime" SG_ 2432651584 BunkH2PHTimer_rqst_DurnTimeMin 100;
BA_ "GenSigCycleTimeActive" SG_ 2432651584 BunkH2PHTimer_rqst_DurnTimeMin 100;
BA_ "GenSigStartValue" SG_ 2432651584 BunkH2PHTimer_rqst_DurnTimeMin 255;
BA_ "GenSigMaxLatency" SG_ 2432651584 BunkH2PHTimer_rqst_DurnTimeMin 26;
BA_ "GenSigCycleTime" SG_ 2432651584 BunkBParkHeater_ButtonStatus 100;
BA_ "GenSigCycleTimeActive" SG_ 2432651584 BunkBParkHeater_ButtonStatus 100;
BA_ "GenSigStartValue" SG_ 2432651584 BunkBParkHeater_ButtonStatus 3;
BA_ "GenSigMaxLatency" SG_ 2432651584 BunkBParkHeater_ButtonStatus 26;
BA_ "GenSigCycleTime" SG_ 2432651584 BunkH2PHTimer_rqst_StartTimeHr 100;
BA_ "GenSigCycleTimeActive" SG_ 2432651584 BunkH2PHTimer_rqst_StartTimeHr 100;
BA_ "GenSigStartValue" SG_ 2432651584 BunkH2PHTimer_rqst_StartTimeHr 255;
BA_ "GenSigMaxLatency" SG_ 2432651584 BunkH2PHTimer_rqst_StartTimeHr 26;
BA_ "GenSigCycleTime" SG_ 2432651584 BunkH2PHTimer_rqst_DurnTimeHr 100;
BA_ "GenSigCycleTimeActive" SG_ 2432651584 BunkH2PHTimer_rqst_DurnTimeHr 100;
BA_ "GenSigStartValue" SG_ 2432651584 BunkH2PHTimer_rqst_DurnTimeHr 255;
BA_ "GenSigMaxLatency" SG_ 2432651584 BunkH2PHTimer_rqst_DurnTimeHr 26;
BA_ "GenSigCycleTime" SG_ 2432651584 BunkBTempInc_ButtonStatus 100;
BA_ "GenSigCycleTimeActive" SG_ 2432651584 BunkBTempInc_ButtonStatus 100;
BA_ "GenSigStartValue" SG_ 2432651584 BunkBTempInc_ButtonStatus 3;
BA_ "GenSigMaxLatency" SG_ 2432651584 BunkBTempInc_ButtonStatus 26;
BA_ "GenSigCycleTime" SG_ 2432651584 PtosStatus 100;
BA_ "GenSigCycleTimeActive" SG_ 2432651584 PtosStatus 100;
BA_ "GenSigStartValue" SG_ 2432651584 PtosStatus 3;
BA_ "GenSigMaxLatency" SG_ 2432651584 PtosStatus 26;
BA_ "NeedsUpdateBit" SG_ 2432651584 PtosStatus 1;
BA_ "SeToolAncestorID_SIGNAL" SG_ 2432651584 PtosStatus "x0000001D042CA490";
BA_ "SeToolItemID_SIGNAL" SG_ 2432651584 PtosStatus "x0000001D042CA490";
BA_ "SeToolName_SIGNAL" SG_ 2432651584 PtosStatus "PtosStatus";
BA_ "SeToolVersion_SIGNAL" SG_ 2432651584 PtosStatus "1";
BA_ "GenSigSendType" SG_ 2432651584 PtosStatus_UB 7;
BA_ "GenSigCycleTime" SG_ 2432651584 BunkB1ParkHeaterBtn_stat 100;
BA_ "GenSigCycleTimeActive" SG_ 2432651584 BunkB1ParkHeaterBtn_stat 100;
BA_ "GenSigStartValue" SG_ 2432651584 BunkB1ParkHeaterBtn_stat 3;
BA_ "GenSigMaxLatency" SG_ 2432651584 BunkB1ParkHeaterBtn_stat 26;
BA_ "GenSigCycleTime" SG_ 2432651584 BunkH2PHTimer_rqst_Timer_cmd 100;
BA_ "GenSigCycleTimeActive" SG_ 2432651584 BunkH2PHTimer_rqst_Timer_cmd 100;
BA_ "GenSigStartValue" SG_ 2432651584 BunkH2PHTimer_rqst_Timer_cmd 7;
BA_ "GenSigMaxLatency" SG_ 2432651584 BunkH2PHTimer_rqst_Timer_cmd 26;
BA_ "GenSigCycleTime" SG_ 2431745856 BacklightCmd 100;
BA_ "GenSigCycleTimeActive" SG_ 2431745856 BacklightCmd 100;
BA_ "GenSigMaxLatency" SG_ 2431745856 BacklightCmd 26;
BA_ "SeToolAncestorID_SIGNAL" SG_ 2431745856 BacklightCmd "x0000001D0439DDD1";
BA_ "SeToolItemID_SIGNAL" SG_ 2431745856 BacklightCmd "x0000001D043A84D3";
BA_ "SeToolName_SIGNAL" SG_ 2431745856 BacklightCmd "BacklightCmd";
BA_ "SeToolVersion_SIGNAL" SG_ 2431745856 BacklightCmd "2";
BA_ "GenSigCycleTime" SG_ 2431745856 EngineSpeed 100;
BA_ "GenSigCycleTimeActive" SG_ 2431745856 EngineSpeed 100;
BA_ "GenSigStartValue" SG_ 2431745856 EngineSpeed 65535;
BA_ "GenSigMaxLatency" SG_ 2431745856 EngineSpeed 26;
BA_ "NeedsUpdateBit" SG_ 2431745856 EngineSpeed 1;
BA_ "SeToolAncestorID_SIGNAL" SG_ 2431745856 EngineSpeed "x0000001D0410BACF";
BA_ "SeToolItemID_SIGNAL" SG_ 2431745856 EngineSpeed "x0000001D0410BACF";
BA_ "SeToolName_SIGNAL" SG_ 2431745856 EngineSpeed "EngineSpeed_status";
BA_ "SeToolVersion_SIGNAL" SG_ 2431745856 EngineSpeed "1";
BA_ "GenSigSendType" SG_ 2431745856 LevelControlInformation_UB 7;
BA_ "GenSigCycleTime" SG_ 2431745856 PresetIndicationCmd 100;
BA_ "GenSigCycleTimeActive" SG_ 2431745856 PresetIndicationCmd 100;
BA_ "GenSigStartValue" SG_ 2431745856 PresetIndicationCmd 63;
BA_ "GenSigCycleTime" SG_ 2431745856 VehicleMode 100;
BA_ "GenSigCycleTimeActive" SG_ 2431745856 VehicleMode 100;
BA_ "GenSigStartValue" SG_ 2431745856 VehicleMode 15;
BA_ "NeedsUpdateBit" SG_ 2431745856 VehicleMode 1;
BA_ "GenSigCycleTime" SG_ 2431745856 BunkH2OnOFF_ButtonStatus 100;
BA_ "GenSigCycleTimeActive" SG_ 2431745856 BunkH2OnOFF_ButtonStatus 100;
BA_ "GenSigStartValue" SG_ 2431745856 BunkH2OnOFF_ButtonStatus 3;
BA_ "GenSigCycleTime" SG_ 2431745856 IntLghtModeInd_cmd_EventFlag 100;
BA_ "GenSigCycleTimeActive" SG_ 2431745856 IntLghtModeInd_cmd_EventFlag 100;
BA_ "GenSigCycleTime" SG_ 2431745856 LevelControlInformation 100;
BA_ "GenSigCycleTimeActive" SG_ 2431745856 LevelControlInformation 100;
BA_ "GenSigStartValue" SG_ 2431745856 LevelControlInformation 15;
BA_ "NeedsUpdateBit" SG_ 2431745856 LevelControlInformation 1;
BA_ "SeToolAncestorID_SIGNAL" SG_ 2431745856 LevelControlInformation "x0000001D04290369";
BA_ "SeToolItemID_SIGNAL" SG_ 2431745856 LevelControlInformation "x0000001D04290369";
BA_ "SeToolName_SIGNAL" SG_ 2431745856 LevelControlInformation "LevelControlInformation";
BA_ "SeToolVersion_SIGNAL" SG_ 2431745856 LevelControlInformation "1";
BA_ "GenSigCycleTime" SG_ 2431745856 WheelBasedVehicleSpeed 100;
BA_ "GenSigCycleTimeActive" SG_ 2431745856 WheelBasedVehicleSpeed 100;
BA_ "GenSigStartValue" SG_ 2431745856 WheelBasedVehicleSpeed 65535;
BA_ "GenSigMaxLatency" SG_ 2431745856 WheelBasedVehicleSpeed 26;
BA_ "SeToolAncestorID_SIGNAL" SG_ 2431745856 WheelBasedVehicleSpeed "x0000001D040FEBD2";
BA_ "SeToolItemID_SIGNAL" SG_ 2431745856 WheelBasedVehicleSpeed "x0000001D040FEBD2";
BA_ "SeToolName_SIGNAL" SG_ 2431745856 WheelBasedVehicleSpeed "Wheel-BasedVehicleSpeed";
BA_ "SeToolVersion_SIGNAL" SG_ 2431745856 WheelBasedVehicleSpeed "1";
BA_ "GenSigCycleTime" SG_ 2431745856 IntLghtModeInd_cmd_IL_Mode 100;
BA_ "GenSigCycleTimeActive" SG_ 2431745856 IntLghtModeInd_cmd_IL_Mode 100;
BA_ "GenSigStartValue" SG_ 2431745856 IntLghtModeInd_cmd_IL_Mode 7;
BA_ "GenSigSendType" SG_ 2431745856 VehicleMode_UB 7;
BA_ "GenSigSendType" SG_ 2431745856 EngineSpeed_UB 7;
BA_ "GenSigCycleTime" SG_ 2432650304 EngineCoolantTemp_stat 100;
BA_ "GenSigCycleTimeActive" SG_ 2432650304 EngineCoolantTemp_stat 100;
BA_ "GenSigStartValue" SG_ 2432650304 EngineCoolantTemp_stat 255;
BA_ "GenSigMaxLatency" SG_ 2432650304 EngineCoolantTemp_stat 26;
BA_ "SeToolAncestorID_SIGNAL" SG_ 2432650304 EngineCoolantTemp_stat "x0000001D0410E5B1";
BA_ "SeToolItemID_SIGNAL" SG_ 2432650304 EngineCoolantTemp_stat "x0000001D0410E5B1";
BA_ "SeToolName_SIGNAL" SG_ 2432650304 EngineCoolantTemp_stat "EngineCoolantTemperature_status";
BA_ "SeToolVersion_SIGNAL" SG_ 2432650304 EngineCoolantTemp_stat "1";
BA_ "GenSigCycleTime" SG_ 2432650304 DriverSeatBeltSwitch 100;
BA_ "GenSigCycleTimeActive" SG_ 2432650304 DriverSeatBeltSwitch 100;
BA_ "GenSigStartValue" SG_ 2432650304 DriverSeatBeltSwitch 3;
BA_ "GenSigMaxLatency" SG_ 2432650304 DriverSeatBeltSwitch 26;
BA_ "SeToolAncestorID_SIGNAL" SG_ 2432650304 DriverSeatBeltSwitch "x0000001D0412FE94";
BA_ "SeToolItemID_SIGNAL" SG_ 2432650304 DriverSeatBeltSwitch "x0000001D0412FE94";
BA_ "SeToolName_SIGNAL" SG_ 2432650304 DriverSeatBeltSwitch "DriverSeatBeltSwitch";
BA_ "SeToolVersion_SIGNAL" SG_ 2432650304 DriverSeatBeltSwitch "1";
BA_ "GenSigCycleTime" SG_ 2432650304 AmbientAirTemperature 100;
BA_ "GenSigCycleTimeActive" SG_ 2432650304 AmbientAirTemperature 100;
BA_ "GenSigStartValue" SG_ 2432650304 AmbientAirTemperature 65535;
BA_ "GenSigMaxLatency" SG_ 2432650304 AmbientAirTemperature 26;
BA_ "SeToolAncestorID_SIGNAL" SG_ 2432650304 AmbientAirTemperature "x0000001D040FEBC8";
BA_ "SeToolItemID_SIGNAL" SG_ 2432650304 AmbientAirTemperature "x0000001D040FEBC8";
BA_ "SeToolName_SIGNAL" SG_ 2432650304 AmbientAirTemperature "AmbientAirTemperature";
BA_ "SeToolVersion_SIGNAL" SG_ 2432650304 AmbientAirTemperature "1";
BA_ "GenSigCycleTime" SG_ 2432650304 DriverMemory_rqst 100;
BA_ "GenSigCycleTimeActive" SG_ 2432650304 DriverMemory_rqst 100;
BA_ "GenSigStartValue" SG_ 2432650304 DriverMemory_rqst 31;
BA_ "GenSigCycleTime" SG_ 2432650304 ReverseGearEngaged 100;
BA_ "GenSigCycleTimeActive" SG_ 2432650304 ReverseGearEngaged 100;
BA_ "GenSigStartValue" SG_ 2432650304 ReverseGearEngaged 3;
BA_ "GenSigMaxLatency" SG_ 2432650304 ReverseGearEngaged 26;
BA_ "SeToolAncestorID_SIGNAL" SG_ 2432650304 ReverseGearEngaged "x0000001D0413A2F1";
BA_ "SeToolItemID_SIGNAL" SG_ 2432650304 ReverseGearEngaged "x0000001D0413A2F1";
BA_ "SeToolName_SIGNAL" SG_ 2432650304 ReverseGearEngaged "ReverseGearEngaged";
BA_ "SeToolVersion_SIGNAL" SG_ 2432650304 ReverseGearEngaged "1";
BA_ "GenSigCycleTime" SG_ 2432650304 ParkBrakeActuationStatus 100;
BA_ "GenSigCycleTimeActive" SG_ 2432650304 ParkBrakeActuationStatus 100;
BA_ "GenSigStartValue" SG_ 2432650304 ParkBrakeActuationStatus 7;
BA_ "NeedsUpdateBit" SG_ 2432650304 ParkBrakeActuationStatus 1;
BA_ "SeToolAncestorID_SIGNAL" SG_ 2432650304 ParkBrakeActuationStatus "x0000001D041497B7";
BA_ "SeToolItemID_SIGNAL" SG_ 2432650304 ParkBrakeActuationStatus "x0000001D0433084A";
BA_ "SeToolName_SIGNAL" SG_ 2432650304 ParkBrakeActuationStatus "ParkBrakeActuationStatus";
BA_ "SeToolVersion_SIGNAL" SG_ 2432650304 ParkBrakeActuationStatus "2";
BA_ "GenSigCycleTime" SG_ 2432650304 ECSStandbyActive 100;
BA_ "GenSigCycleTimeActive" SG_ 2432650304 ECSStandbyActive 100;
BA_ "GenSigStartValue" SG_ 2432650304 ECSStandbyActive 3;
BA_ "GenSigMaxLatency" SG_ 2432650304 ECSStandbyActive 15;
BA_ "GenSigCycleTime" SG_ 2432650304 HeightAdjustmentAllowed 100;
BA_ "GenSigCycleTimeActive" SG_ 2432650304 HeightAdjustmentAllowed 100;
BA_ "GenSigStartValue" SG_ 2432650304 HeightAdjustmentAllowed 3;
BA_ "GenSigSendType" SG_ 2432650304 ParkBrakeActuationStatus_UB 7;
BA_ "GenSigCycleTime" SG_ 2432650304 SelectedTimeFormat_stat 100;
BA_ "GenSigCycleTimeActive" SG_ 2432650304 SelectedTimeFormat_stat 100;
BA_ "GenSigStartValue" SG_ 2432650304 SelectedTimeFormat_stat 3;
BA_ "GenSigCycleTime" SG_ 2432650304 SelectedWeightUnit_stat 100;
BA_ "GenSigCycleTimeActive" SG_ 2432650304 SelectedWeightUnit_stat 100;
BA_ "GenSigStartValue" SG_ 2432650304 SelectedWeightUnit_stat 3;
BA_ "GenSigCycleTime" SG_ 2432650304 SelectedDateFormat_stat 100;
BA_ "GenSigCycleTimeActive" SG_ 2432650304 SelectedDateFormat_stat 100;
BA_ "GenSigStartValue" SG_ 2432650304 SelectedDateFormat_stat 7;
BA_ "GenSigCycleTime" SG_ 2432650304 FuncIndIlluminationLevel 100;
BA_ "GenSigCycleTimeActive" SG_ 2432650304 FuncIndIlluminationLevel 100;
BA_ "GenSigStartValue" SG_ 2432650304 FuncIndIlluminationLevel 1;
BA_ "GenSigMaxLatency" SG_ 2432650304 FuncIndIlluminationLevel 26;
BA_ "SeToolAncestorID_SIGNAL" SG_ 2432650304 FuncIndIlluminationLevel "x0000001D043A8396";
BA_ "SeToolItemID_SIGNAL" SG_ 2432650304 FuncIndIlluminationLevel "x0000001D043A8396";
BA_ "SeToolName_SIGNAL" SG_ 2432650304 FuncIndIlluminationLevel "FuncIndIlluminationLevel";
BA_ "SeToolVersion_SIGNAL" SG_ 2432650304 FuncIndIlluminationLevel "1";
BA_ "GenSigCycleTime" SG_ 2432650304 WiperModeStatus 100;
BA_ "GenSigCycleTimeActive" SG_ 2432650304 WiperModeStatus 100;
BA_ "GenSigStartValue" SG_ 2432650304 WiperModeStatus 7;
BA_ "GenSigMaxLatency" SG_ 2432650304 WiperModeStatus 26;
BA_ "SeToolAncestorID_SIGNAL" SG_ 2432650304 WiperModeStatus "x0000001D0410D271";
BA_ "SeToolItemID_SIGNAL" SG_ 2432650304 WiperModeStatus "x0000001D0410D271";
BA_ "SeToolName_SIGNAL" SG_ 2432650304 WiperModeStatus "WiperModeStatus";
BA_ "SeToolVersion_SIGNAL" SG_ 2432650304 WiperModeStatus "1";
BA_ "GenSigCycleTime" SG_ 2432650304 MirrorHeatingMode 100;
BA_ "GenSigCycleTimeActive" SG_ 2432650304 MirrorHeatingMode 100;
BA_ "GenSigStartValue" SG_ 2432650304 MirrorHeatingMode 7;
BA_ "GenSigMaxLatency" SG_ 2432650304 MirrorHeatingMode 26;
BA_ "SeToolAncestorID_SIGNAL" SG_ 2432650304 MirrorHeatingMode "x0000001D0412C1DB";
BA_ "SeToolItemID_SIGNAL" SG_ 2432650304 MirrorHeatingMode "x0000001D0412C1DB";
BA_ "SeToolName_SIGNAL" SG_ 2432650304 MirrorHeatingMode "MirrorHeatingMode";
BA_ "SeToolVersion_SIGNAL" SG_ 2432650304 MirrorHeatingMode "1";
BA_ "GenSigCycleTime" SG_ 2499098520 WasteHeatTempRequest 100;
BA_ "GenSigCycleTimeActive" SG_ 2499098520 WasteHeatTempRequest 100;
BA_ "GenSigStartValue" SG_ 2499098520 WasteHeatTempRequest 127;
BA_ "GenSigCycleTime" SG_ 2499098520 EACC_TV_Pwr 100;
BA_ "GenSigCycleTimeActive" SG_ 2499098520 EACC_TV_Pwr 100;
BA_ "GenSigStartValue" SG_ 2499098520 EACC_TV_Pwr 255;
BA_ "GenSigCycleTime" SG_ 2499098520 BunkParkClimateStatus 100;
BA_ "GenSigCycleTimeActive" SG_ 2499098520 BunkParkClimateStatus 100;
BA_ "GenSigStartValue" SG_ 2499098520 BunkParkClimateStatus 3;
BA_ "GenSigCycleTime" SG_ 2499098520 TVECH_C_Pwr 100;
BA_ "GenSigCycleTimeActive" SG_ 2499098520 TVECH_C_Pwr 100;
BA_ "GenSigStartValue" SG_ 2499098520 TVECH_C_Pwr 255;
BA_ "GenSigCycleTime" SG_ 2499098520 Req24VforClimateSystem 100;
BA_ "GenSigCycleTimeActive" SG_ 2499098520 Req24VforClimateSystem 100;
BA_ "GenSigStartValue" SG_ 2499098520 Req24VforClimateSystem 3;
BA_ "GenSigCycleTime" SG_ 2499098520 AuxFunCabPreCondition_Stat 100;
BA_ "GenSigCycleTimeActive" SG_ 2499098520 AuxFunCabPreCondition_Stat 100;
BA_ "GenSigStartValue" SG_ 2499098520 AuxFunCabPreCondition_Stat 7;
BA_ "GenSigCycleTime" SG_ 2499098520 EACC_TV_Voltage 100;
BA_ "GenSigCycleTimeActive" SG_ 2499098520 EACC_TV_Voltage 100;
BA_ "GenSigStartValue" SG_ 2499098520 EACC_TV_Voltage 255;
BA_ "GenSigCycleTime" SG_ 2499098520 TVECH_C_Voltage 100;
BA_ "GenSigCycleTimeActive" SG_ 2499098520 TVECH_C_Voltage 100;
BA_ "GenSigStartValue" SG_ 2499098520 TVECH_C_Voltage 1023;
BA_ "GenSigCycleTime" SG_ 2499031960 LifeTimeTVECH_C_ConsEgy 100;
BA_ "GenSigCycleTimeActive" SG_ 2499031960 LifeTimeTVECH_C_ConsEgy 100;
BA_ "GenSigStartValue" SG_ 2499031960 LifeTimeTVECH_C_ConsEgy 255;
BA_ "GenSigCycleTime" SG_ 2499031960 LifeTimeEACC_TVCabConsEgy 100;
BA_ "GenSigCycleTimeActive" SG_ 2499031960 LifeTimeEACC_TVCabConsEgy 100;
BA_ "GenSigStartValue" SG_ 2499031960 LifeTimeEACC_TVCabConsEgy 65535;
BA_ "GenSigCycleTime" SG_ 2499031960 LifeTimeEACC_TVBattConsEgy 100;
BA_ "GenSigCycleTimeActive" SG_ 2499031960 LifeTimeEACC_TVBattConsEgy 100;
BA_ "GenSigStartValue" SG_ 2499031960 LifeTimeEACC_TVBattConsEgy 65535;
BA_ "GenSigCycleTime" SG_ 2499031960 CabClimateICEEnergyRqst 100;
BA_ "GenSigCycleTimeActive" SG_ 2499031960 CabClimateICEEnergyRqst 100;
BA_ "GenSigStartValue" SG_ 2499031960 CabClimateICEEnergyRqst 7;
BA_ "GenSigSendType" SG_ 2566356888 ACStatus 3;
BA_ "GenSigStartValue" SG_ 2566356888 ACStatus 3;
BA_ "GenSigMaxLatency" SG_ 2566356888 ACStatus 500;
BA_ "GenSigSendType" SG_ 2566356888 ClimateAirDistStatus_Defrost 3;
BA_ "GenSigStartValue" SG_ 2566356888 ClimateAirDistStatus_Defrost 15;
BA_ "GenSigMaxLatency" SG_ 2566356888 ClimateAirDistStatus_Defrost 500;
BA_ "GenSigSendType" SG_ 2566356888 HVACBlowerLevelStat_AutoStatus 3;
BA_ "GenSigStartValue" SG_ 2566356888 HVACBlowerLevelStat_AutoStatus 3;
BA_ "GenSigMaxLatency" SG_ 2566356888 HVACBlowerLevelStat_AutoStatus 500;
BA_ "GenSigSendType" SG_ 2566356888 MaxDefrostStatus 3;
BA_ "GenSigStartValue" SG_ 2566356888 MaxDefrostStatus 3;
BA_ "GenSigMaxLatency" SG_ 2566356888 MaxDefrostStatus 500;
BA_ "GenSigSendType" SG_ 2566356888 ClimateAirDistStatus_Floor 3;
BA_ "GenSigStartValue" SG_ 2566356888 ClimateAirDistStatus_Floor 15;
BA_ "GenSigMaxLatency" SG_ 2566356888 ClimateAirDistStatus_Floor 500;
BA_ "GenSigSendType" SG_ 2566356888 BunkHVACBlwrLvlStat_AutoStatus 3;
BA_ "GenSigStartValue" SG_ 2566356888 BunkHVACBlwrLvlStat_AutoStatus 3;
BA_ "GenSigMaxLatency" SG_ 2566356888 BunkHVACBlwrLvlStat_AutoStatus 500;
BA_ "GenSigSendType" SG_ 2566356888 ClimateAirDistStatus_AutoStatus 3;
BA_ "GenSigStartValue" SG_ 2566356888 ClimateAirDistStatus_AutoStatus 3;
BA_ "GenSigMaxLatency" SG_ 2566356888 ClimateAirDistStatus_AutoStatus 500;
BA_ "GenSigSendType" SG_ 2566356888 ClimateAirDistStatus_Vent 3;
BA_ "GenSigStartValue" SG_ 2566356888 ClimateAirDistStatus_Vent 15;
BA_ "GenSigMaxLatency" SG_ 2566356888 ClimateAirDistStatus_Vent 500;
BA_ "GenSigSendType" SG_ 2566356888 CabTempStatus 3;
BA_ "GenSigStartValue" SG_ 2566356888 CabTempStatus 127;
BA_ "GenSigMaxLatency" SG_ 2566356888 CabTempStatus 500;
BA_ "GenSigSendType" SG_ 2566356888 ParkingClimateAvailability 3;
BA_ "GenSigStartValue" SG_ 2566356888 ParkingClimateAvailability 7;
BA_ "GenSigMaxLatency" SG_ 2566356888 ParkingClimateAvailability 500;
BA_ "GenSigSendType" SG_ 2566356888 HVACBlowerLevelStat_BlowerLevel 3;
BA_ "GenSigStartValue" SG_ 2566356888 HVACBlowerLevelStat_BlowerLevel 31;
BA_ "GenSigMaxLatency" SG_ 2566356888 HVACBlowerLevelStat_BlowerLevel 500;
BA_ "GenSigSendType" SG_ 2566356888 BunkClimatePowerStatus 3;
BA_ "GenSigStartValue" SG_ 2566356888 BunkClimatePowerStatus 3;
BA_ "GenSigMaxLatency" SG_ 2566356888 BunkClimatePowerStatus 500;
BA_ "GenSigSendType" SG_ 2566356888 BunkTempStatus 3;
BA_ "GenSigStartValue" SG_ 2566356888 BunkTempStatus 127;
BA_ "GenSigMaxLatency" SG_ 2566356888 BunkTempStatus 500;
BA_ "GenSigSendType" SG_ 2566356888 ClimateAutoStatus 3;
BA_ "GenSigStartValue" SG_ 2566356888 ClimateAutoStatus 7;
BA_ "GenSigMaxLatency" SG_ 2566356888 ClimateAutoStatus 500;
BA_ "GenSigSendType" SG_ 2566356888 BunkClimateAutoStatus 3;
BA_ "GenSigStartValue" SG_ 2566356888 BunkClimateAutoStatus 7;
BA_ "GenSigMaxLatency" SG_ 2566356888 BunkClimateAutoStatus 500;
BA_ "GenSigSendType" SG_ 2566356888 BunkHVACBlwrLvlStat_BlowerLevel 3;
BA_ "GenSigStartValue" SG_ 2566356888 BunkHVACBlwrLvlStat_BlowerLevel 31;
BA_ "GenSigMaxLatency" SG_ 2566356888 BunkHVACBlwrLvlStat_BlowerLevel 500;
BA_ "GenSigSendType" SG_ 2566356888 ClimatePowerStatus 3;
BA_ "GenSigStartValue" SG_ 2566356888 ClimatePowerStatus 3;
BA_ "GenSigMaxLatency" SG_ 2566356888 ClimatePowerStatus 500;
BA_ "GenSigSendType" SG_ 2566356888 AirRecirculationStatus 3;
BA_ "GenSigStartValue" SG_ 2566356888 AirRecirculationStatus 3;
BA_ "GenSigMaxLatency" SG_ 2566356888 AirRecirculationStatus 500;
BA_ "GenSigSendType" SG_ 2566356888 BunkACStatus 3;
BA_ "GenSigStartValue" SG_ 2566356888 BunkACStatus 3;
BA_ "GenSigMaxLatency" SG_ 2566356888 BunkACStatus 500;
BA_ "GenSigCycleTime" SG_ 2561091992 CabCoolingLoadStaus 100;
BA_ "GenSigCycleTimeActive" SG_ 2561091992 CabCoolingLoadStaus 100;
BA_ "GenSigStartValue" SG_ 2561091992 CabCoolingLoadStaus 3;
BA_ "GenSigCycleTime" SG_ 2561091992 CabClimateFnRqst_FnNum 100;
BA_ "GenSigCycleTimeActive" SG_ 2561091992 CabClimateFnRqst_FnNum 100;
BA_ "GenSigStartValue" SG_ 2561091992 CabClimateFnRqst_FnNum 15;
BA_ "GenSigCycleTime" SG_ 2561091992 ChlrVlvPsnRqst 100;
BA_ "GenSigCycleTimeActive" SG_ 2561091992 ChlrVlvPsnRqst 100;
BA_ "GenSigStartValue" SG_ 2561091992 ChlrVlvPsnRqst 255;
BA_ "GenSigCycleTime" SG_ 2561091992 CoolantTempBeforeCabLoop 100;
BA_ "GenSigCycleTimeActive" SG_ 2561091992 CoolantTempBeforeCabLoop 100;
BA_ "GenSigStartValue" SG_ 2561091992 CoolantTempBeforeCabLoop 1023;
BA_ "GenSigCycleTime" SG_ 2561091992 CabClimateFnRqst_FnPower 100;
BA_ "GenSigCycleTimeActive" SG_ 2561091992 CabClimateFnRqst_FnPower 100;
BA_ "GenSigStartValue" SG_ 2561091992 CabClimateFnRqst_FnPower 255;
BA_ "GenSigCycleTime" SG_ 2561091992 ChlrAvailPwr 100;
BA_ "GenSigCycleTimeActive" SG_ 2561091992 ChlrAvailPwr 100;
BA_ "GenSigStartValue" SG_ 2561091992 ChlrAvailPwr 255;
BA_ "GenSigSendType" SG_ 2561091992 CabHeatManStatus 3;
BA_ "GenSigStartValue" SG_ 2561091992 CabHeatManStatus 15;
BA_ "GenSigSendType" SG_ 2432641688 ParkClimTimerStat_Type 1;
BA_ "GenSigCycleTime" SG_ 2432641688 ParkClimTimerStat_Type 100;
BA_ "GenSigCycleTimeActive" SG_ 2432641688 ParkClimTimerStat_Type 100;
BA_ "GenSigStartValue" SG_ 2432641688 ParkClimTimerStat_Type 7;
BA_ "GenSigMaxLatency" SG_ 2432641688 ParkClimTimerStat_Type 20;
BA_ "NeedsUpdateBit" SG_ 2432641688 ParkClimTimerStat_Type 1;
BA_ "GenSigSendType" SG_ 2432641688 ParkClimTimerStat_Rec 1;
BA_ "GenSigCycleTime" SG_ 2432641688 ParkClimTimerStat_Rec 100;
BA_ "GenSigCycleTimeActive" SG_ 2432641688 ParkClimTimerStat_Rec 100;
BA_ "GenSigMaxLatency" SG_ 2432641688 ParkClimTimerStat_Rec 20;
BA_ "NeedsUpdateBit" SG_ 2432641688 ParkClimTimerStat_Rec 1;
BA_ "GenSigSendType" SG_ 2432641688 ParkClimTimerStat_Tue 1;
BA_ "GenSigCycleTime" SG_ 2432641688 ParkClimTimerStat_Tue 100;
BA_ "GenSigCycleTimeActive" SG_ 2432641688 ParkClimTimerStat_Tue 100;
BA_ "GenSigMaxLatency" SG_ 2432641688 ParkClimTimerStat_Tue 20;
BA_ "NeedsUpdateBit" SG_ 2432641688 ParkClimTimerStat_Tue 1;
BA_ "GenSigSendType" SG_ 2432641688 ParkClimTimerStat_Thu 1;
BA_ "GenSigCycleTime" SG_ 2432641688 ParkClimTimerStat_Thu 100;
BA_ "GenSigCycleTimeActive" SG_ 2432641688 ParkClimTimerStat_Thu 100;
BA_ "GenSigMaxLatency" SG_ 2432641688 ParkClimTimerStat_Thu 20;
BA_ "NeedsUpdateBit" SG_ 2432641688 ParkClimTimerStat_Thu 1;
BA_ "GenSigSendType" SG_ 2432641688 ParkClimTimerStat_TimerNr 1;
BA_ "GenSigCycleTime" SG_ 2432641688 ParkClimTimerStat_TimerNr 100;
BA_ "GenSigCycleTimeActive" SG_ 2432641688 ParkClimTimerStat_TimerNr 100;
BA_ "GenSigStartValue" SG_ 2432641688 ParkClimTimerStat_TimerNr 255;
BA_ "GenSigMaxLatency" SG_ 2432641688 ParkClimTimerStat_TimerNr 20;
BA_ "NeedsUpdateBit" SG_ 2432641688 ParkClimTimerStat_TimerNr 1;
BA_ "GenSigSendType" SG_ 2432641688 ParkClimTimerStat_TotalNoTimers 1;
BA_ "GenSigCycleTime" SG_ 2432641688 ParkClimTimerStat_TotalNoTimers 100;
BA_ "GenSigCycleTimeActive" SG_ 2432641688 ParkClimTimerStat_TotalNoTimers 100;
BA_ "GenSigStartValue" SG_ 2432641688 ParkClimTimerStat_TotalNoTimers 255;
BA_ "GenSigMaxLatency" SG_ 2432641688 ParkClimTimerStat_TotalNoTimers 20;
BA_ "NeedsUpdateBit" SG_ 2432641688 ParkClimTimerStat_TotalNoTimers 1;
BA_ "GenSigSendType" SG_ 2432641688 ParkClimTimerStat_Sat 1;
BA_ "GenSigCycleTime" SG_ 2432641688 ParkClimTimerStat_Sat 100;
BA_ "GenSigCycleTimeActive" SG_ 2432641688 ParkClimTimerStat_Sat 100;
BA_ "GenSigMaxLatency" SG_ 2432641688 ParkClimTimerStat_Sat 20;
BA_ "NeedsUpdateBit" SG_ 2432641688 ParkClimTimerStat_Sat 1;
BA_ "GenSigSendType" SG_ 2432641688 ParkClimTimerStat_Min 1;
BA_ "GenSigCycleTime" SG_ 2432641688 ParkClimTimerStat_Min 100;
BA_ "GenSigCycleTimeActive" SG_ 2432641688 ParkClimTimerStat_Min 100;
BA_ "GenSigStartValue" SG_ 2432641688 ParkClimTimerStat_Min 255;
BA_ "GenSigMaxLatency" SG_ 2432641688 ParkClimTimerStat_Min 20;
BA_ "NeedsUpdateBit" SG_ 2432641688 ParkClimTimerStat_Min 1;
BA_ "GenSigSendType" SG_ 2432641688 ParkClimTimerStat_Status 1;
BA_ "GenSigCycleTime" SG_ 2432641688 ParkClimTimerStat_Status 100;
BA_ "GenSigCycleTimeActive" SG_ 2432641688 ParkClimTimerStat_Status 100;
BA_ "GenSigStartValue" SG_ 2432641688 ParkClimTimerStat_Status 3;
BA_ "GenSigMaxLatency" SG_ 2432641688 ParkClimTimerStat_Status 20;
BA_ "NeedsUpdateBit" SG_ 2432641688 ParkClimTimerStat_Status 1;
BA_ "GenSigSendType" SG_ 2432641688 ParkClimTimerStat_Wed 1;
BA_ "GenSigCycleTime" SG_ 2432641688 ParkClimTimerStat_Wed 100;
BA_ "GenSigCycleTimeActive" SG_ 2432641688 ParkClimTimerStat_Wed 100;
BA_ "GenSigMaxLatency" SG_ 2432641688 ParkClimTimerStat_Wed 20;
BA_ "NeedsUpdateBit" SG_ 2432641688 ParkClimTimerStat_Wed 1;
BA_ "GenSigSendType" SG_ 2432641688 ParkClimTimerStat_Sun 1;
BA_ "GenSigCycleTime" SG_ 2432641688 ParkClimTimerStat_Sun 100;
BA_ "GenSigCycleTimeActive" SG_ 2432641688 ParkClimTimerStat_Sun 100;
BA_ "GenSigMaxLatency" SG_ 2432641688 ParkClimTimerStat_Sun 20;
BA_ "NeedsUpdateBit" SG_ 2432641688 ParkClimTimerStat_Sun 1;
BA_ "GenSigSendType" SG_ 2432641688 ParkClimTimerStat_Hrs 1;
BA_ "GenSigCycleTime" SG_ 2432641688 ParkClimTimerStat_Hrs 100;
BA_ "GenSigCycleTimeActive" SG_ 2432641688 ParkClimTimerStat_Hrs 100;
BA_ "GenSigStartValue" SG_ 2432641688 ParkClimTimerStat_Hrs 255;
BA_ "GenSigMaxLatency" SG_ 2432641688 ParkClimTimerStat_Hrs 20;
BA_ "NeedsUpdateBit" SG_ 2432641688 ParkClimTimerStat_Hrs 1;
BA_ "GenSigSendType" SG_ 2432641688 ParkClimTimerStat_Temp 1;
BA_ "GenSigCycleTime" SG_ 2432641688 ParkClimTimerStat_Temp 100;
BA_ "GenSigCycleTimeActive" SG_ 2432641688 ParkClimTimerStat_Temp 100;
BA_ "GenSigStartValue" SG_ 2432641688 ParkClimTimerStat_Temp 255;
BA_ "GenSigMaxLatency" SG_ 2432641688 ParkClimTimerStat_Temp 20;
BA_ "NeedsUpdateBit" SG_ 2432641688 ParkClimTimerStat_Temp 1;
BA_ "GenSigSendType" SG_ 2432641688 ParkClimTimerStat_Fri 1;
BA_ "GenSigCycleTime" SG_ 2432641688 ParkClimTimerStat_Fri 100;
BA_ "GenSigCycleTimeActive" SG_ 2432641688 ParkClimTimerStat_Fri 100;
BA_ "GenSigMaxLatency" SG_ 2432641688 ParkClimTimerStat_Fri 20;
BA_ "NeedsUpdateBit" SG_ 2432641688 ParkClimTimerStat_Fri 1;
BA_ "GenSigSendType" SG_ 2432641688 ParkClimTimerStat_Dur 1;
BA_ "GenSigCycleTime" SG_ 2432641688 ParkClimTimerStat_Dur 100;
BA_ "GenSigCycleTimeActive" SG_ 2432641688 ParkClimTimerStat_Dur 100;
BA_ "GenSigStartValue" SG_ 2432641688 ParkClimTimerStat_Dur 127;
BA_ "GenSigMaxLatency" SG_ 2432641688 ParkClimTimerStat_Dur 20;
BA_ "NeedsUpdateBit" SG_ 2432641688 ParkClimTimerStat_Dur 1;
BA_ "GenSigSendType" SG_ 2432641688 ParkClimTimerStat_MinRes 1;
BA_ "GenSigCycleTime" SG_ 2432641688 ParkClimTimerStat_MinRes 100;
BA_ "GenSigCycleTimeActive" SG_ 2432641688 ParkClimTimerStat_MinRes 100;
BA_ "GenSigStartValue" SG_ 2432641688 ParkClimTimerStat_MinRes 7;
BA_ "GenSigMaxLatency" SG_ 2432641688 ParkClimTimerStat_MinRes 20;
BA_ "NeedsUpdateBit" SG_ 2432641688 ParkClimTimerStat_MinRes 1;
BA_ "GenSigSendType" SG_ 2432641688 ParkClimTimerStat_Mon 1;
BA_ "GenSigCycleTime" SG_ 2432641688 ParkClimTimerStat_Mon 100;
BA_ "GenSigCycleTimeActive" SG_ 2432641688 ParkClimTimerStat_Mon 100;
BA_ "GenSigMaxLatency" SG_ 2432641688 ParkClimTimerStat_Mon 20;
BA_ "NeedsUpdateBit" SG_ 2432641688 ParkClimTimerStat_Mon 1;
BA_ "GenSigSendType" SG_ 2432641688 ParkClimTimerStat_sg_UB 7;
BA_ "GenSigCycleTime" SG_ 2432640664 PHTimer2_stat_Recurrence 100;
BA_ "GenSigCycleTimeActive" SG_ 2432640664 PHTimer2_stat_Recurrence 100;
BA_ "GenSigStartValue" SG_ 2432640664 PHTimer2_stat_Recurrence 15;
BA_ "NeedsUpdateBit" SG_ 2432640664 PHTimer2_stat_Recurrence 1;
BA_ "GenSigCycleTime" SG_ 2432640664 PHTimer2_stat_Hours 100;
BA_ "GenSigCycleTimeActive" SG_ 2432640664 PHTimer2_stat_Hours 100;
BA_ "GenSigStartValue" SG_ 2432640664 PHTimer2_stat_Hours 255;
BA_ "NeedsUpdateBit" SG_ 2432640664 PHTimer2_stat_Hours 1;
BA_ "GenSigCycleTime" SG_ 2432640664 PHTimer3_stat_Temp 100;
BA_ "GenSigCycleTimeActive" SG_ 2432640664 PHTimer3_stat_Temp 100;
BA_ "GenSigStartValue" SG_ 2432640664 PHTimer3_stat_Temp 31;
BA_ "NeedsUpdateBit" SG_ 2432640664 PHTimer3_stat_Temp 1;
BA_ "GenSigCycleTime" SG_ 2432640664 PHTimer3_stat_Hours 100;
BA_ "GenSigCycleTimeActive" SG_ 2432640664 PHTimer3_stat_Hours 100;
BA_ "GenSigStartValue" SG_ 2432640664 PHTimer3_stat_Hours 255;
BA_ "NeedsUpdateBit" SG_ 2432640664 PHTimer3_stat_Hours 1;
BA_ "GenSigCycleTime" SG_ 2432640664 PHTimer3_stat_Status 100;
BA_ "GenSigCycleTimeActive" SG_ 2432640664 PHTimer3_stat_Status 100;
BA_ "GenSigStartValue" SG_ 2432640664 PHTimer3_stat_Status 3;
BA_ "NeedsUpdateBit" SG_ 2432640664 PHTimer3_stat_Status 1;
BA_ "GenSigCycleTime" SG_ 2432640664 PHTimer2_stat_StartDay 100;
BA_ "GenSigCycleTimeActive" SG_ 2432640664 PHTimer2_stat_StartDay 100;
BA_ "GenSigStartValue" SG_ 2432640664 PHTimer2_stat_StartDay 15;
BA_ "NeedsUpdateBit" SG_ 2432640664 PHTimer2_stat_StartDay 1;
BA_ "GenSigSendType" SG_ 2432640664 PHTimer2_stat_sg_UB 7;
BA_ "GenSigCycleTime" SG_ 2432640664 PHTimer2_stat_Temp 100;
BA_ "GenSigCycleTimeActive" SG_ 2432640664 PHTimer2_stat_Temp 100;
BA_ "GenSigStartValue" SG_ 2432640664 PHTimer2_stat_Temp 31;
BA_ "NeedsUpdateBit" SG_ 2432640664 PHTimer2_stat_Temp 1;
BA_ "GenSigSendType" SG_ 2432640664 PHTimer3_stat_sg_UB 7;
BA_ "GenSigCycleTime" SG_ 2432640664 PHTimer2_stat_Status 100;
BA_ "GenSigCycleTimeActive" SG_ 2432640664 PHTimer2_stat_Status 100;
BA_ "GenSigStartValue" SG_ 2432640664 PHTimer2_stat_Status 3;
BA_ "NeedsUpdateBit" SG_ 2432640664 PHTimer2_stat_Status 1;
BA_ "GenSigCycleTime" SG_ 2432640664 PHTimer2_stat_Minutes 100;
BA_ "GenSigCycleTimeActive" SG_ 2432640664 PHTimer2_stat_Minutes 100;
BA_ "GenSigStartValue" SG_ 2432640664 PHTimer2_stat_Minutes 255;
BA_ "NeedsUpdateBit" SG_ 2432640664 PHTimer2_stat_Minutes 1;
BA_ "GenSigCycleTime" SG_ 2432640664 PHTimer3_stat_Minutes 100;
BA_ "GenSigCycleTimeActive" SG_ 2432640664 PHTimer3_stat_Minutes 100;
BA_ "GenSigStartValue" SG_ 2432640664 PHTimer3_stat_Minutes 255;
BA_ "NeedsUpdateBit" SG_ 2432640664 PHTimer3_stat_Minutes 1;
BA_ "GenSigCycleTime" SG_ 2432640664 PHTimer3_stat_Recurrence 100;
BA_ "GenSigCycleTimeActive" SG_ 2432640664 PHTimer3_stat_Recurrence 100;
BA_ "GenSigStartValue" SG_ 2432640664 PHTimer3_stat_Recurrence 15;
BA_ "NeedsUpdateBit" SG_ 2432640664 PHTimer3_stat_Recurrence 1;
BA_ "GenSigCycleTime" SG_ 2432640664 PHTimer3_stat_StartDay 100;
BA_ "GenSigCycleTimeActive" SG_ 2432640664 PHTimer3_stat_StartDay 100;
BA_ "GenSigStartValue" SG_ 2432640664 PHTimer3_stat_StartDay 15;
BA_ "NeedsUpdateBit" SG_ 2432640664 PHTimer3_stat_StartDay 1;
BA_ "GenSigCycleTime" SG_ 2432644760 PHTimer1_stat_Minutes 100;
BA_ "GenSigCycleTimeActive" SG_ 2432644760 PHTimer1_stat_Minutes 100;
BA_ "GenSigStartValue" SG_ 2432644760 PHTimer1_stat_Minutes 255;
BA_ "NeedsUpdateBit" SG_ 2432644760 PHTimer1_stat_Minutes 1;
BA_ "GenSigCycleTime" SG_ 2432644760 ExtraHeating_status 100;
BA_ "GenSigCycleTimeActive" SG_ 2432644760 ExtraHeating_status 100;
BA_ "GenSigStartValue" SG_ 2432644760 ExtraHeating_status 3;
BA_ "GenSigCycleTime" SG_ 2432644760 AQSmode_Status 100;
BA_ "GenSigCycleTimeActive" SG_ 2432644760 AQSmode_Status 100;
BA_ "GenSigStartValue" SG_ 2432644760 AQSmode_Status 3;
BA_ "GenSigCycleTime" SG_ 2432644760 ParkingClimate_IndicationCmd 100;
BA_ "GenSigCycleTimeActive" SG_ 2432644760 ParkingClimate_IndicationCmd 100;
BA_ "GenSigStartValue" SG_ 2432644760 ParkingClimate_IndicationCmd 7;
BA_ "GenSigCycleTime" SG_ 2432644760 ACmode_Status 100;
BA_ "GenSigCycleTimeActive" SG_ 2432644760 ACmode_Status 100;
BA_ "GenSigStartValue" SG_ 2432644760 ACmode_Status 7;
BA_ "GenSigSendType" SG_ 2432644760 PHTimer1_stat_sg_UB 7;
BA_ "GenSigCycleTime" SG_ 2432644760 ShortStopHeater_cmd 100;
BA_ "GenSigCycleTimeActive" SG_ 2432644760 ShortStopHeater_cmd 100;
BA_ "GenSigStartValue" SG_ 2432644760 ShortStopHeater_cmd 3;
BA_ "GenSigCycleTime" SG_ 2432644760 PHTimer1_stat_Status 100;
BA_ "GenSigCycleTimeActive" SG_ 2432644760 PHTimer1_stat_Status 100;
BA_ "GenSigStartValue" SG_ 2432644760 PHTimer1_stat_Status 3;
BA_ "NeedsUpdateBit" SG_ 2432644760 PHTimer1_stat_Status 1;
BA_ "GenSigCycleTime" SG_ 2432644760 PHTimer1_stat_StartDay 100;
BA_ "GenSigCycleTimeActive" SG_ 2432644760 PHTimer1_stat_StartDay 100;
BA_ "GenSigStartValue" SG_ 2432644760 PHTimer1_stat_StartDay 15;
BA_ "NeedsUpdateBit" SG_ 2432644760 PHTimer1_stat_StartDay 1;
BA_ "GenSigCycleTime" SG_ 2432644760 PHTimer1_stat_Duration 100;
BA_ "GenSigCycleTimeActive" SG_ 2432644760 PHTimer1_stat_Duration 100;
BA_ "GenSigStartValue" SG_ 2432644760 PHTimer1_stat_Duration 127;
BA_ "NeedsUpdateBit" SG_ 2432644760 PHTimer1_stat_Duration 1;
BA_ "GenSigCycleTime" SG_ 2432644760 ReqVehTVSforClimateSystem 100;
BA_ "GenSigCycleTimeActive" SG_ 2432644760 ReqVehTVSforClimateSystem 100;
BA_ "GenSigStartValue" SG_ 2432644760 ReqVehTVSforClimateSystem 3;
BA_ "GenSigCycleTime" SG_ 2432644760 AutoBlowerLevel_Status 100;
BA_ "GenSigCycleTimeActive" SG_ 2432644760 AutoBlowerLevel_Status 100;
BA_ "GenSigStartValue" SG_ 2432644760 AutoBlowerLevel_Status 7;
BA_ "GenSigCycleTime" SG_ 2432644760 PHTimer1_stat_Temp 100;
BA_ "GenSigCycleTimeActive" SG_ 2432644760 PHTimer1_stat_Temp 100;
BA_ "GenSigStartValue" SG_ 2432644760 PHTimer1_stat_Temp 31;
BA_ "NeedsUpdateBit" SG_ 2432644760 PHTimer1_stat_Temp 1;
BA_ "GenSigCycleTime" SG_ 2432644760 PHCleanStatFeedback 100;
BA_ "GenSigCycleTimeActive" SG_ 2432644760 PHCleanStatFeedback 100;
BA_ "GenSigStartValue" SG_ 2432644760 PHCleanStatFeedback 3;
BA_ "GenSigCycleTime" SG_ 2432644760 PHTimer1_stat_Recurrence 100;
BA_ "GenSigCycleTimeActive" SG_ 2432644760 PHTimer1_stat_Recurrence 100;
BA_ "GenSigStartValue" SG_ 2432644760 PHTimer1_stat_Recurrence 15;
BA_ "NeedsUpdateBit" SG_ 2432644760 PHTimer1_stat_Recurrence 1;
BA_ "GenSigCycleTime" SG_ 2432644760 PHTimer1_stat_Hours 100;
BA_ "GenSigCycleTimeActive" SG_ 2432644760 PHTimer1_stat_Hours 100;
BA_ "GenSigStartValue" SG_ 2432644760 PHTimer1_stat_Hours 255;
BA_ "NeedsUpdateBit" SG_ 2432644760 PHTimer1_stat_Hours 1;
BA_ "GenSigCycleTime" SG_ 2432644760 AutoDefogmode_Status 100;
BA_ "GenSigCycleTimeActive" SG_ 2432644760 AutoDefogmode_Status 100;
BA_ "GenSigStartValue" SG_ 2432644760 AutoDefogmode_Status 7;
BA_ "GenSigCycleTime" SG_ 2432645496 ParkHeaterCooler_ButtonStatus 100;
BA_ "GenSigCycleTimeActive" SG_ 2432645496 ParkHeaterCooler_ButtonStatus 100;
BA_ "GenSigStartValue" SG_ 2432645496 ParkHeaterCooler_ButtonStatus 3;
BA_ "GenSigCycleTime" SG_ 2432645496 AirFlowSelectionUpBtn_stat 100;
BA_ "GenSigCycleTimeActive" SG_ 2432645496 AirFlowSelectionUpBtn_stat 100;
BA_ "GenSigStartValue" SG_ 2432645496 AirFlowSelectionUpBtn_stat 3;
BA_ "SeToolAncestorID_SIGNAL" SG_ 2432645496 AirFlowSelectionUpBtn_stat "x0000001D0423D932";
BA_ "SeToolItemID_SIGNAL" SG_ 2432645496 AirFlowSelectionUpBtn_stat "x0000001D0429669B";
BA_ "SeToolName_SIGNAL" SG_ 2432645496 AirFlowSelectionUpBtn_stat "AirFlowSelectionUp_ButtonStatus";
BA_ "SeToolVersion_SIGNAL" SG_ 2432645496 AirFlowSelectionUpBtn_stat "4";
BA_ "GenSigCycleTime" SG_ 2432645496 Auto_ButtonStatus 100;
BA_ "GenSigCycleTimeActive" SG_ 2432645496 Auto_ButtonStatus 100;
BA_ "GenSigStartValue" SG_ 2432645496 Auto_ButtonStatus 3;
BA_ "SeToolAncestorID_SIGNAL" SG_ 2432645496 Auto_ButtonStatus "x0000001D0423D932";
BA_ "SeToolItemID_SIGNAL" SG_ 2432645496 Auto_ButtonStatus "x0000001D0429669B";
BA_ "SeToolName_SIGNAL" SG_ 2432645496 Auto_ButtonStatus "Auto_ButtonStatus";
BA_ "SeToolVersion_SIGNAL" SG_ 2432645496 Auto_ButtonStatus "4";
BA_ "GenSigCycleTime" SG_ 2432645496 Temperature_FreeWheelStatus 100;
BA_ "GenSigCycleTimeActive" SG_ 2432645496 Temperature_FreeWheelStatus 100;
BA_ "GenSigStartValue" SG_ 2432645496 Temperature_FreeWheelStatus 15;
BA_ "SeToolAncestorID_SIGNAL" SG_ 2432645496 Temperature_FreeWheelStatus "x0000001D0425F9AD";
BA_ "SeToolItemID_SIGNAL" SG_ 2432645496 Temperature_FreeWheelStatus "x0000001D043FC230";
BA_ "SeToolName_SIGNAL" SG_ 2432645496 Temperature_FreeWheelStatus "Temperature_FreeWheelStatus";
BA_ "SeToolVersion_SIGNAL" SG_ 2432645496 Temperature_FreeWheelStatus "3";
BA_ "GenSigCycleTime" SG_ 2432645496 AC_ButtonStatus 100;
BA_ "GenSigCycleTimeActive" SG_ 2432645496 AC_ButtonStatus 100;
BA_ "GenSigStartValue" SG_ 2432645496 AC_ButtonStatus 3;
BA_ "SeToolAncestorID_SIGNAL" SG_ 2432645496 AC_ButtonStatus "x0000001D0423D932";
BA_ "SeToolItemID_SIGNAL" SG_ 2432645496 AC_ButtonStatus "x0000001D0429669B";
BA_ "SeToolName_SIGNAL" SG_ 2432645496 AC_ButtonStatus "AC_ButtonStatus";
BA_ "SeToolVersion_SIGNAL" SG_ 2432645496 AC_ButtonStatus "4";
BA_ "GenSigCycleTime" SG_ 2432645496 WindscreenDefrost_ButtonStatus 100;
BA_ "GenSigCycleTimeActive" SG_ 2432645496 WindscreenDefrost_ButtonStatus 100;
BA_ "GenSigStartValue" SG_ 2432645496 WindscreenDefrost_ButtonStatus 3;
BA_ "SeToolAncestorID_SIGNAL" SG_ 2432645496 WindscreenDefrost_ButtonStatus "x0000001D0423D932";
BA_ "SeToolItemID_SIGNAL" SG_ 2432645496 WindscreenDefrost_ButtonStatus "x0000001D0429669B";
BA_ "SeToolName_SIGNAL" SG_ 2432645496 WindscreenDefrost_ButtonStatus "WindscreenDefroster_ButtonStatus";
BA_ "SeToolVersion_SIGNAL" SG_ 2432645496 WindscreenDefrost_ButtonStatus "4";
BA_ "GenSigCycleTime" SG_ 2432645496 Recirc_ButtonStatus 100;
BA_ "GenSigCycleTimeActive" SG_ 2432645496 Recirc_ButtonStatus 100;
BA_ "GenSigStartValue" SG_ 2432645496 Recirc_ButtonStatus 3;
BA_ "SeToolAncestorID_SIGNAL" SG_ 2432645496 Recirc_ButtonStatus "x0000001D0423D932";
BA_ "SeToolItemID_SIGNAL" SG_ 2432645496 Recirc_ButtonStatus "x0000001D0429669B";
BA_ "SeToolName_SIGNAL" SG_ 2432645496 Recirc_ButtonStatus "Recirc_ButtonStatus";
BA_ "SeToolVersion_SIGNAL" SG_ 2432645496 Recirc_ButtonStatus "4";
BA_ "GenSigCycleTime" SG_ 2432645496 ChillerPumpRequest 100;
BA_ "GenSigCycleTimeActive" SG_ 2432645496 ChillerPumpRequest 100;
BA_ "GenSigStartValue" SG_ 2432645496 ChillerPumpRequest 1023;
BA_ "GenSigCycleTime" SG_ 2432645496 AirFlowSelectionDownBtn_stat 100;
BA_ "GenSigCycleTimeActive" SG_ 2432645496 AirFlowSelectionDownBtn_stat 100;
BA_ "GenSigStartValue" SG_ 2432645496 AirFlowSelectionDownBtn_stat 3;
BA_ "SeToolAncestorID_SIGNAL" SG_ 2432645496 AirFlowSelectionDownBtn_stat "x0000001D0423D932";
BA_ "SeToolItemID_SIGNAL" SG_ 2432645496 AirFlowSelectionDownBtn_stat "x0000001D0429669B";
BA_ "SeToolName_SIGNAL" SG_ 2432645496 AirFlowSelectionDownBtn_stat "AirFlowSelectionDown_ButtonStatus";
BA_ "SeToolVersion_SIGNAL" SG_ 2432645496 AirFlowSelectionDownBtn_stat "4";
BA_ "GenSigCycleTime" SG_ 2432645496 AirFlowSelectionFrontBtn_stat 100;
BA_ "GenSigCycleTimeActive" SG_ 2432645496 AirFlowSelectionFrontBtn_stat 100;
BA_ "GenSigStartValue" SG_ 2432645496 AirFlowSelectionFrontBtn_stat 3;
BA_ "SeToolAncestorID_SIGNAL" SG_ 2432645496 AirFlowSelectionFrontBtn_stat "x0000001D0423D932";
BA_ "SeToolItemID_SIGNAL" SG_ 2432645496 AirFlowSelectionFrontBtn_stat "x0000001D0429669B";
BA_ "SeToolName_SIGNAL" SG_ 2432645496 AirFlowSelectionFrontBtn_stat "AirFlowSelectionFront_ButtonStatus";
BA_ "SeToolVersion_SIGNAL" SG_ 2432645496 AirFlowSelectionFrontBtn_stat "4";
BA_ "GenSigCycleTime" SG_ 2432645496 AcCoolantPumpEngagementRequest 100;
BA_ "GenSigCycleTimeActive" SG_ 2432645496 AcCoolantPumpEngagementRequest 100;
BA_ "GenSigStartValue" SG_ 2432645496 AcCoolantPumpEngagementRequest 255;
BA_ "GenSigCycleTime" SG_ 2432645496 AirBlowerSpeed_FreeWheelStatus 100;
BA_ "GenSigCycleTimeActive" SG_ 2432645496 AirBlowerSpeed_FreeWheelStatus 100;
BA_ "GenSigStartValue" SG_ 2432645496 AirBlowerSpeed_FreeWheelStatus 15;
BA_ "SeToolAncestorID_SIGNAL" SG_ 2432645496 AirBlowerSpeed_FreeWheelStatus "x0000001D0425F9AD";
BA_ "SeToolItemID_SIGNAL" SG_ 2432645496 AirBlowerSpeed_FreeWheelStatus "x0000001D043FC230";
BA_ "SeToolName_SIGNAL" SG_ 2432645496 AirBlowerSpeed_FreeWheelStatus "AirBlowerSpeed_FreeWheelStatus";
BA_ "SeToolVersion_SIGNAL" SG_ 2432645496 AirBlowerSpeed_FreeWheelStatus "3";
BA_ "GenSigCycleTime" SG_ 2432639640 ACmode_IndicationCmd 100;
BA_ "GenSigCycleTimeActive" SG_ 2432639640 ACmode_IndicationCmd 100;
BA_ "GenSigMaxLatency" SG_ 2432639640 ACmode_IndicationCmd 26;
BA_ "SeToolAncestorID_SIGNAL" SG_ 2432639640 ACmode_IndicationCmd "x0000001D04405ABB";
BA_ "SeToolItemID_SIGNAL" SG_ 2432639640 ACmode_IndicationCmd "x0000001D04405ABB";
BA_ "SeToolName_SIGNAL" SG_ 2432639640 ACmode_IndicationCmd "ACmode_IndicationCmd";
BA_ "SeToolVersion_SIGNAL" SG_ 2432639640 ACmode_IndicationCmd "1";
BA_ "GenSigCycleTime" SG_ 2432639640 PHTimer_rqst_SetAlarmOper 100;
BA_ "GenSigCycleTimeActive" SG_ 2432639640 PHTimer_rqst_SetAlarmOper 100;
BA_ "GenSigStartValue" SG_ 2432639640 PHTimer_rqst_SetAlarmOper 7;
BA_ "GenSigCycleTime" SG_ 2432639640 PHTimer_rqst_Hours 100;
BA_ "GenSigCycleTimeActive" SG_ 2432639640 PHTimer_rqst_Hours 100;
BA_ "GenSigStartValue" SG_ 2432639640 PHTimer_rqst_Hours 255;
BA_ "GenSigMaxLatency" SG_ 2432639640 PHTimer_rqst_Hours 26;
BA_ "GenSigCycleTime" SG_ 2432639640 PHTimer_rqst_Minutes 100;
BA_ "GenSigCycleTimeActive" SG_ 2432639640 PHTimer_rqst_Minutes 100;
BA_ "GenSigStartValue" SG_ 2432639640 PHTimer_rqst_Minutes 255;
BA_ "GenSigMaxLatency" SG_ 2432639640 PHTimer_rqst_Minutes 26;
BA_ "GenSigCycleTime" SG_ 2432639640 CabInteriorTempVentilated_Stat 100;
BA_ "GenSigCycleTimeActive" SG_ 2432639640 CabInteriorTempVentilated_Stat 100;
BA_ "GenSigStartValue" SG_ 2432639640 CabInteriorTempVentilated_Stat 1023;
BA_ "SeToolAncestorID_SIGNAL" SG_ 2432639640 CabInteriorTempVentilated_Stat "x0000001D043C9954";
BA_ "SeToolItemID_SIGNAL" SG_ 2432639640 CabInteriorTempVentilated_Stat "x0000001D043C9954";
BA_ "SeToolName_SIGNAL" SG_ 2432639640 CabInteriorTempVentilated_Stat "CabInteriorTempVentilated_Stat";
BA_ "SeToolVersion_SIGNAL" SG_ 2432639640 CabInteriorTempVentilated_Stat "1";
BA_ "GenSigCycleTime" SG_ 2432639640 AirBleedValveCtrl 100;
BA_ "GenSigCycleTimeActive" SG_ 2432639640 AirBleedValveCtrl 100;
BA_ "GenSigStartValue" SG_ 2432639640 AirBleedValveCtrl 3;
BA_ "GenSigCycleTime" SG_ 2432639640 ParkingHeaterCleaning_Rqst 100;
BA_ "GenSigCycleTimeActive" SG_ 2432639640 ParkingHeaterCleaning_Rqst 100;
BA_ "GenSigStartValue" SG_ 2432639640 ParkingHeaterCleaning_Rqst 3;
BA_ "GenSigMaxLatency" SG_ 2432639640 ParkingHeaterCleaning_Rqst 26;
BA_ "GenSigCycleTime" SG_ 2432639640 ParkingHeater_IndicationCmd 100;
BA_ "GenSigCycleTimeActive" SG_ 2432639640 ParkingHeater_IndicationCmd 100;
BA_ "GenSigMaxLatency" SG_ 2432639640 ParkingHeater_IndicationCmd 26;
BA_ "GenSigCycleTime" SG_ 2432639640 AC_CompressorClutchCmd 100;
BA_ "GenSigCycleTimeActive" SG_ 2432639640 AC_CompressorClutchCmd 100;
BA_ "GenSigStartValue" SG_ 2432639640 AC_CompressorClutchCmd 3;
BA_ "GenSigMaxLatency" SG_ 2432639640 AC_CompressorClutchCmd 26;
BA_ "GenSigCycleTime" SG_ 2432639640 PHTimer_rqst_DayOfWeekRq 100;
BA_ "GenSigCycleTimeActive" SG_ 2432639640 PHTimer_rqst_DayOfWeekRq 100;
BA_ "GenSigStartValue" SG_ 2432639640 PHTimer_rqst_DayOfWeekRq 15;
BA_ "GenSigMaxLatency" SG_ 2432639640 PHTimer_rqst_DayOfWeekRq 26;
BA_ "GenSigSendType" SG_ 2432637336 ACCoolingFanSpeedRequest_CCM_UB 7;
BA_ "GenSigCycleTime" SG_ 2432637336 ACCoolingFanSpeedRequest_CCM_UB 100;
BA_ "GenSigCycleTimeActive" SG_ 2432637336 ACCoolingFanSpeedRequest_CCM_UB 100;
BA_ "GenSigCycleTime" SG_ 2432637336 ACCoolingFanSpeedRequest_CCM 100;
BA_ "GenSigCycleTimeActive" SG_ 2432637336 ACCoolingFanSpeedRequest_CCM 100;
BA_ "GenSigStartValue" SG_ 2432637336 ACCoolingFanSpeedRequest_CCM 65535;
BA_ "NeedsUpdateBit" SG_ 2432637336 ACCoolingFanSpeedRequest_CCM 1;
BA_ "GenSigCycleTime" SG_ 2432637336 TemperatureRqstIndication_cmd 100;
BA_ "GenSigCycleTimeActive" SG_ 2432637336 TemperatureRqstIndication_cmd 100;
BA_ "GenSigStartValue" SG_ 2432637336 TemperatureRqstIndication_cmd 31;
BA_ "GenSigMaxLatency" SG_ 2432637336 TemperatureRqstIndication_cmd 26;
BA_ "SeToolAncestorID_SIGNAL" SG_ 2432637336 TemperatureRqstIndication_cmd "x0000001D04150607";
BA_ "SeToolItemID_SIGNAL" SG_ 2432637336 TemperatureRqstIndication_cmd "x0000001D043FAF4A";
BA_ "SeToolName_SIGNAL" SG_ 2432637336 TemperatureRqstIndication_cmd "TemperatureRqstIndication_cmd ";
BA_ "SeToolVersion_SIGNAL" SG_ 2432637336 TemperatureRqstIndication_cmd "4";
BA_ "GenSigCycleTime" SG_ 2432637336 MirrorHeatNormModeBtn_stat 100;
BA_ "GenSigCycleTimeActive" SG_ 2432637336 MirrorHeatNormModeBtn_stat 100;
BA_ "GenSigStartValue" SG_ 2432637336 MirrorHeatNormModeBtn_stat 3;
BA_ "SeToolAncestorID_SIGNAL" SG_ 2432637336 MirrorHeatNormModeBtn_stat "x0000001D0423D932";
BA_ "SeToolItemID_SIGNAL" SG_ 2432637336 MirrorHeatNormModeBtn_stat "x0000001D0429669B";
BA_ "SeToolName_SIGNAL" SG_ 2432637336 MirrorHeatNormModeBtn_stat "EM_MirrorHeatNormalMode_ButtonStatus";
BA_ "SeToolVersion_SIGNAL" SG_ 2432637336 MirrorHeatNormModeBtn_stat "4";
BA_ "GenSigCycleTime" SG_ 2432637336 WindscreenDefrostInd_cmd 100;
BA_ "GenSigCycleTimeActive" SG_ 2432637336 WindscreenDefrostInd_cmd 100;
BA_ "SeToolAncestorID_SIGNAL" SG_ 2432637336 WindscreenDefrostInd_cmd "x0000001D04405ABB";
BA_ "SeToolItemID_SIGNAL" SG_ 2432637336 WindscreenDefrostInd_cmd "x0000001D04405ABB";
BA_ "SeToolName_SIGNAL" SG_ 2432637336 WindscreenDefrostInd_cmd "WindscreenDefrost_IndicationCmd";
BA_ "SeToolVersion_SIGNAL" SG_ 2432637336 WindscreenDefrostInd_cmd "1";
BA_ "GenSigSendType" SG_ 2633994283 AnmSig_WRCS_CabSubnet 1;
BA_ "GenSigCycleTime" SG_ 2633994283 AnmSig_WRCS_CabSubnet 100;
BA_ "GenSigCycleTimeActive" SG_ 2633994283 AnmSig_WRCS_CabSubnet 100;
BA_ "MmAnSignal" SG_ 2633994283 AnmSig_WRCS_CabSubnet 1;
BA_ "GenSigSendType" SG_ 2633994282 AnmSig_SRS_CabSubnet 1;
BA_ "GenSigCycleTime" SG_ 2633994282 AnmSig_SRS_CabSubnet 100;
BA_ "GenSigCycleTimeActive" SG_ 2633994282 AnmSig_SRS_CabSubnet 100;
BA_ "MmAnSignal" SG_ 2633994282 AnmSig_SRS_CabSubnet 1;
BA_ "GenSigSendType" SG_ 2633994280 AnmSig_LECM1_CabSubnet 1;
BA_ "GenSigCycleTime" SG_ 2633994280 AnmSig_LECM1_CabSubnet 100;
BA_ "GenSigCycleTimeActive" SG_ 2633994280 AnmSig_LECM1_CabSubnet 100;
BA_ "MmAnSignal" SG_ 2633994280 AnmSig_LECM1_CabSubnet 1;
BA_ "GenSigSendType" SG_ 2633994320 AnmSig_ECUspare6_CabSubnet 1;
BA_ "GenSigCycleTime" SG_ 2633994320 AnmSig_ECUspare6_CabSubnet 100;
BA_ "GenSigCycleTimeActive" SG_ 2633994320 AnmSig_ECUspare6_CabSubnet 100;
BA_ "MmAnSignal" SG_ 2633994320 AnmSig_ECUspare6_CabSubnet 1;
BA_ "GenSigSendType" SG_ 2633994326 AnmSig_CMS_CabSubnet 1;
BA_ "GenSigCycleTime" SG_ 2633994326 AnmSig_CMS_CabSubnet 100;
BA_ "GenSigCycleTimeActive" SG_ 2633994326 AnmSig_CMS_CabSubnet 100;
BA_ "MmAnSignal" SG_ 2633994326 AnmSig_CMS_CabSubnet 1;
BA_ "GenSigSendType" SG_ 2633994278 AnmSig_CIOM_CabSubnet 1;
BA_ "GenSigCycleTime" SG_ 2633994278 AnmSig_CIOM_CabSubnet 100;
BA_ "GenSigCycleTimeActive" SG_ 2633994278 AnmSig_CIOM_CabSubnet 100;
BA_ "MmAnSignal" SG_ 2633994278 AnmSig_CIOM_CabSubnet 1;
BA_ "GenSigSendType" SG_ 2633994277 AnmSig_CCM_CabSubnet 1;
BA_ "GenSigCycleTime" SG_ 2633994277 AnmSig_CCM_CabSubnet 100;
BA_ "GenSigCycleTimeActive" SG_ 2633994277 AnmSig_CCM_CabSubnet 100;
BA_ "MmAnSignal" SG_ 2633994277 AnmSig_CCM_CabSubnet 1;
BA_REL_ "GenSigFirstTimeoutTime" BU_SG_REL_ LECM1 SG_ 2550115648 YearUTC 6000;
BA_REL_ "GenSigTimeoutTime" BU_SG_REL_ LECM1 SG_ 2550115648 YearUTC 1500;
BA_REL_ "GenSigFirstTimeoutTime" BU_SG_REL_ LECM3 SG_ 2550115648 YearUTC 6000;
BA_REL_ "GenSigTimeoutTime" BU_SG_REL_ LECM3 SG_ 2550115648 YearUTC 1500;
BA_REL_ "GenSigFirstTimeoutTime" BU_SG_REL_ WRCS SG_ 2550115648 YearUTC 6000;
BA_REL_ "GenSigTimeoutTime" BU_SG_REL_ WRCS SG_ 2550115648 YearUTC 1500;
BA_REL_ "GenSigFirstTimeoutTime" BU_SG_REL_ CMS SG_ 2550115648 YearUTC 6000;
BA_REL_ "GenSigTimeoutTime" BU_SG_REL_ CMS SG_ 2550115648 YearUTC 1500;
BA_REL_ "GenSigFirstTimeoutTime" BU_SG_REL_ SRS SG_ 2550115648 YearUTC 6000;
BA_REL_ "GenSigTimeoutTime" BU_SG_REL_ SRS SG_ 2550115648 YearUTC 1500;
BA_REL_ "GenSigFirstTimeoutTime" BU_SG_REL_ CCM SG_ 2550115648 YearUTC 6000;
BA_REL_ "GenSigTimeoutTime" BU_SG_REL_ CCM SG_ 2550115648 YearUTC 1500;
BA_REL_ "GenSigFirstTimeoutTime" BU_SG_REL_ AlcoLock2 SG_ 2550115648 YearUTC 6000;
BA_REL_ "GenSigTimeoutTime" BU_SG_REL_ AlcoLock2 SG_ 2550115648 YearUTC 1500;
BA_REL_ "GenSigFirstTimeoutTime" BU_SG_REL_ LECM1 SG_ 2550115648 SecondsUTC 6000;
BA_REL_ "GenSigTimeoutTime" BU_SG_REL_ LECM1 SG_ 2550115648 SecondsUTC 1500;
BA_REL_ "GenSigFirstTimeoutTime" BU_SG_REL_ WRCS SG_ 2550115648 SecondsUTC 6000;
BA_REL_ "GenSigTimeoutTime" BU_SG_REL_ WRCS SG_ 2550115648 SecondsUTC 1500;
BA_REL_ "GenSigFirstTimeoutTime" BU_SG_REL_ CCM SG_ 2550115648 SecondsUTC 6000;
BA_REL_ "GenSigTimeoutTime" BU_SG_REL_ CCM SG_ 2550115648 SecondsUTC 1500;
BA_REL_ "GenSigFirstTimeoutTime" BU_SG_REL_ LECM3 SG_ 2550115648 SecondsUTC 6000;
BA_REL_ "GenSigTimeoutTime" BU_SG_REL_ LECM3 SG_ 2550115648 SecondsUTC 1500;
BA_REL_ "GenSigFirstTimeoutTime" BU_SG_REL_ CMS SG_ 2550115648 SecondsUTC 6000;
BA_REL_ "GenSigTimeoutTime" BU_SG_REL_ CMS SG_ 2550115648 SecondsUTC 1500;
BA_REL_ "GenSigFirstTimeoutTime" BU_SG_REL_ AlcoLock2 SG_ 2550115648 SecondsUTC 6000;
BA_REL_ "GenSigTimeoutTime" BU_SG_REL_ AlcoLock2 SG_ 2550115648 SecondsUTC 1500;
BA_REL_ "GenSigFirstTimeoutTime" BU_SG_REL_ SRS SG_ 2550115648 SecondsUTC 6000;
BA_REL_ "GenSigTimeoutTime" BU_SG_REL_ SRS SG_ 2550115648 SecondsUTC 1500;
BA_REL_ "GenSigFirstTimeoutTime" BU_SG_REL_ WRCS SG_ 2550115648 DayUTC 6000;
BA_REL_ "GenSigTimeoutTime" BU_SG_REL_ WRCS SG_ 2550115648 DayUTC 1500;
BA_REL_ "GenSigFirstTimeoutTime" BU_SG_REL_ CMS SG_ 2550115648 DayUTC 6000;
BA_REL_ "GenSigTimeoutTime" BU_SG_REL_ CMS SG_ 2550115648 DayUTC 1500;
BA_REL_ "GenSigFirstTimeoutTime" BU_SG_REL_ LECM3 SG_ 2550115648 DayUTC 6000;
BA_REL_ "GenSigTimeoutTime" BU_SG_REL_ LECM3 SG_ 2550115648 DayUTC 1500;
BA_REL_ "GenSigFirstTimeoutTime" BU_SG_REL_ AlcoLock2 SG_ 2550115648 DayUTC 6000;
BA_REL_ "GenSigTimeoutTime" BU_SG_REL_ AlcoLock2 SG_ 2550115648 DayUTC 1500;
BA_REL_ "GenSigFirstTimeoutTime" BU_SG_REL_ SRS SG_ 2550115648 DayUTC 6000;
BA_REL_ "GenSigTimeoutTime" BU_SG_REL_ SRS SG_ 2550115648 DayUTC 1500;
BA_REL_ "GenSigFirstTimeoutTime" BU_SG_REL_ LECM1 SG_ 2550115648 DayUTC 6000;
BA_REL_ "GenSigTimeoutTime" BU_SG_REL_ LECM1 SG_ 2550115648 DayUTC 1500;
BA_REL_ "GenSigFirstTimeoutTime" BU_SG_REL_ CCM SG_ 2550115648 DayUTC 6000;
BA_REL_ "GenSigTimeoutTime" BU_SG_REL_ CCM SG_ 2550115648 DayUTC 1500;
BA_REL_ "GenSigFirstTimeoutTime" BU_SG_REL_ LECM1 SG_ 2550115648 MinutesUTC 6000;
BA_REL_ "GenSigTimeoutTime" BU_SG_REL_ LECM1 SG_ 2550115648 MinutesUTC 1500;
BA_REL_ "GenSigFirstTimeoutTime" BU_SG_REL_ LECM3 SG_ 2550115648 MinutesUTC 6000;
BA_REL_ "GenSigTimeoutTime" BU_SG_REL_ LECM3 SG_ 2550115648 MinutesUTC 1500;
BA_REL_ "GenSigFirstTimeoutTime" BU_SG_REL_ CCM SG_ 2550115648 MinutesUTC 6000;
BA_REL_ "GenSigTimeoutTime" BU_SG_REL_ CCM SG_ 2550115648 MinutesUTC 1500;
BA_REL_ "GenSigFirstTimeoutTime" BU_SG_REL_ WRCS SG_ 2550115648 MinutesUTC 6000;
BA_REL_ "GenSigTimeoutTime" BU_SG_REL_ WRCS SG_ 2550115648 MinutesUTC 1500;
BA_REL_ "GenSigFirstTimeoutTime" BU_SG_REL_ SRS SG_ 2550115648 MinutesUTC 6000;
BA_REL_ "GenSigTimeoutTime" BU_SG_REL_ SRS SG_ 2550115648 MinutesUTC 1500;
BA_REL_ "GenSigFirstTimeoutTime" BU_SG_REL_ CMS SG_ 2550115648 MinutesUTC 6000;
BA_REL_ "GenSigTimeoutTime" BU_SG_REL_ CMS SG_ 2550115648 MinutesUTC 1500;
BA_REL_ "GenSigFirstTimeoutTime" BU_SG_REL_ AlcoLock2 SG_ 2550115648 MinutesUTC 6000;
BA_REL_ "GenSigTimeoutTime" BU_SG_REL_ AlcoLock2 SG_ 2550115648 MinutesUTC 1500;
BA_REL_ "GenSigFirstTimeoutTime" BU_SG_REL_ CMS SG_ 2550115648 HoursUTC 6000;
BA_REL_ "GenSigTimeoutTime" BU_SG_REL_ CMS SG_ 2550115648 HoursUTC 1500;
BA_REL_ "GenSigFirstTimeoutTime" BU_SG_REL_ LECM1 SG_ 2550115648 HoursUTC 6000;
BA_REL_ "GenSigTimeoutTime" BU_SG_REL_ LECM1 SG_ 2550115648 HoursUTC 1500;
BA_REL_ "GenSigFirstTimeoutTime" BU_SG_REL_ WRCS SG_ 2550115648 HoursUTC 6000;
BA_REL_ "GenSigTimeoutTime" BU_SG_REL_ WRCS SG_ 2550115648 HoursUTC 1500;
BA_REL_ "GenSigFirstTimeoutTime" BU_SG_REL_ LECM3 SG_ 2550115648 HoursUTC 6000;
BA_REL_ "GenSigTimeoutTime" BU_SG_REL_ LECM3 SG_ 2550115648 HoursUTC 1500;
BA_REL_ "GenSigFirstTimeoutTime" BU_SG_REL_ SRS SG_ 2550115648 HoursUTC 6000;
BA_REL_ "GenSigTimeoutTime" BU_SG_REL_ SRS SG_ 2550115648 HoursUTC 1500;
BA_REL_ "GenSigFirstTimeoutTime" BU_SG_REL_ CCM SG_ 2550115648 HoursUTC 6000;
BA_REL_ "GenSigTimeoutTime" BU_SG_REL_ CCM SG_ 2550115648 HoursUTC 1500;
BA_REL_ "GenSigFirstTimeoutTime" BU_SG_REL_ AlcoLock2 SG_ 2550115648 HoursUTC 6000;
BA_REL_ "GenSigTimeoutTime" BU_SG_REL_ AlcoLock2 SG_ 2550115648 HoursUTC 1500;
BA_REL_ "GenSigFirstTimeoutTime" BU_SG_REL_ WRCS SG_ 2550115648 MonthUTC 6000;
BA_REL_ "GenSigTimeoutTime" BU_SG_REL_ WRCS SG_ 2550115648 MonthUTC 1500;
BA_REL_ "GenSigFirstTimeoutTime" BU_SG_REL_ SRS SG_ 2550115648 MonthUTC 6000;
BA_REL_ "GenSigTimeoutTime" BU_SG_REL_ SRS SG_ 2550115648 MonthUTC 1500;
BA_REL_ "GenSigFirstTimeoutTime" BU_SG_REL_ CCM SG_ 2550115648 MonthUTC 6000;
BA_REL_ "GenSigTimeoutTime" BU_SG_REL_ CCM SG_ 2550115648 MonthUTC 1500;
BA_REL_ "GenSigFirstTimeoutTime" BU_SG_REL_ AlcoLock2 SG_ 2550115648 MonthUTC 6000;
BA_REL_ "GenSigTimeoutTime" BU_SG_REL_ AlcoLock2 SG_ 2550115648 MonthUTC 1500;
BA_REL_ "GenSigFirstTimeoutTime" BU_SG_REL_ CMS SG_ 2550115648 MonthUTC 6000;
BA_REL_ "GenSigTimeoutTime" BU_SG_REL_ CMS SG_ 2550115648 MonthUTC 1500;
BA_REL_ "GenSigFirstTimeoutTime" BU_SG_REL_ LECM3 SG_ 2550115648 MonthUTC 6000;
BA_REL_ "GenSigTimeoutTime" BU_SG_REL_ LECM3 SG_ 2550115648 MonthUTC 1500;
BA_REL_ "GenSigFirstTimeoutTime" BU_SG_REL_ LECM1 SG_ 2550115648 MonthUTC 6000;
BA_REL_ "GenSigTimeoutTime" BU_SG_REL_ LECM1 SG_ 2550115648 MonthUTC 1500;
BA_REL_ "GenSigFirstTimeoutTime" BU_SG_REL_ WRCS SG_ 2432669248 AuxSwitchBbLoad2_Status 3000;
BA_REL_ "GenSigTimeoutTime" BU_SG_REL_ WRCS SG_ 2432669248 AuxSwitchBbLoad2_Status 120;
BA_REL_ "GenSigFirstTimeoutTime" BU_SG_REL_ LECM1 SG_ 2432669248 DoorLock_stat 3000;
BA_REL_ "GenSigTimeoutTime" BU_SG_REL_ LECM1 SG_ 2432669248 DoorLock_stat 120;
BA_REL_ "GenSigFirstTimeoutTime" BU_SG_REL_ WRCS SG_ 2432669248 DoorLock_stat 3000;
BA_REL_ "GenSigTimeoutTime" BU_SG_REL_ WRCS SG_ 2432669248 DoorLock_stat 120;
BA_REL_ "GenSigFirstTimeoutTime" BU_SG_REL_ CMS SG_ 2432669248 DoorLock_stat 3000;
BA_REL_ "GenSigTimeoutTime" BU_SG_REL_ CMS SG_ 2432669248 DoorLock_stat 120;
BA_REL_ "GenSigFirstTimeoutTime" BU_SG_REL_ CCM SG_ 2432669248 PSWindowPosition 3000;
BA_REL_ "GenSigTimeoutTime" BU_SG_REL_ CCM SG_ 2432669248 PSWindowPosition 120;
BA_REL_ "GenSigFirstTimeoutTime" BU_SG_REL_ WRCS SG_ 2432669248 AuxSwitchBbLoad1_Status 3000;
BA_REL_ "GenSigTimeoutTime" BU_SG_REL_ WRCS SG_ 2432669248 AuxSwitchBbLoad1_Status 120;
BA_REL_ "GenSigFirstTimeoutTime" BU_SG_REL_ CCM SG_ 2432669248 ReducedLoadMode_stat 3000;
BA_REL_ "GenSigTimeoutTime" BU_SG_REL_ CCM SG_ 2432669248 ReducedLoadMode_stat 120;
BA_REL_ "GenSigFirstTimeoutTime" BU_SG_REL_ WRCS SG_ 2432669248 TrailersConnected 3000;
BA_REL_ "GenSigTimeoutTime" BU_SG_REL_ WRCS SG_ 2432669248 TrailersConnected 120;
BA_REL_ "GenSigFirstTimeoutTime" BU_SG_REL_ CMS SG_ 2432669248 TrailersConnected 3000;
BA_REL_ "GenSigTimeoutTime" BU_SG_REL_ CMS SG_ 2432669248 TrailersConnected 120;
BA_REL_ "GenSigFirstTimeoutTime" BU_SG_REL_ CCM SG_ 2432669248 DriverDoorAjar_stat 3000;
BA_REL_ "GenSigTimeoutTime" BU_SG_REL_ CCM SG_ 2432669248 DriverDoorAjar_stat 120;
BA_REL_ "GenSigFirstTimeoutTime" BU_SG_REL_ WRCS SG_ 2432669248 AuxSwitchBbLoad6_Status 3000;
BA_REL_ "GenSigTimeoutTime" BU_SG_REL_ WRCS SG_ 2432669248 AuxSwitchBbLoad6_Status 120;
BA_REL_ "GenSigFirstTimeoutTime" BU_SG_REL_ LECM1 SG_ 2432669248 BunkBacklightCmd 3000;
BA_REL_ "GenSigTimeoutTime" BU_SG_REL_ LECM1 SG_ 2432669248 BunkBacklightCmd 120;
BA_REL_ "GenSigFirstTimeoutTime" BU_SG_REL_ WRCS SG_ 2432669248 AuxSwitchBbLoad4_Status 3000;
BA_REL_ "GenSigTimeoutTime" BU_SG_REL_ WRCS SG_ 2432669248 AuxSwitchBbLoad4_Status 120;
BA_REL_ "GenSigFirstTimeoutTime" BU_SG_REL_ CCM SG_ 2432669248 DSWindowPosition 3000;
BA_REL_ "GenSigTimeoutTime" BU_SG_REL_ CCM SG_ 2432669248 DSWindowPosition 120;
BA_REL_ "GenSigFirstTimeoutTime" BU_SG_REL_ LECM1 SG_ 2432669248 SelectedLanguage_stat 3000;
BA_REL_ "GenSigTimeoutTime" BU_SG_REL_ LECM1 SG_ 2432669248 SelectedLanguage_stat 120;
BA_REL_ "GenSigFirstTimeoutTime" BU_SG_REL_ WRCS SG_ 2432669248 SelectedLanguage_stat 3000;
BA_REL_ "GenSigTimeoutTime" BU_SG_REL_ WRCS SG_ 2432669248 SelectedLanguage_stat 120;
BA_REL_ "GenSigFirstTimeoutTime" BU_SG_REL_ CCM SG_ 2432669248 PassengerDoorAjar_stat 3000;
BA_REL_ "GenSigTimeoutTime" BU_SG_REL_ CCM SG_ 2432669248 PassengerDoorAjar_stat 120;
BA_REL_ "GenSigFirstTimeoutTime" BU_SG_REL_ CCM SG_ 2432669248 BunkB1ParkHeaterTempSw_stat 3000;
BA_REL_ "GenSigTimeoutTime" BU_SG_REL_ CCM SG_ 2432669248 BunkB1ParkHeaterTempSw_stat 120;
BA_REL_ "GenSigFirstTimeoutTime" BU_SG_REL_ WRCS SG_ 2432669248 AuxSwitchBbLoad5_Status 3000;
BA_REL_ "GenSigTimeoutTime" BU_SG_REL_ WRCS SG_ 2432669248 AuxSwitchBbLoad5_Status 120;
BA_REL_ "GenSigFirstTimeoutTime" BU_SG_REL_ WRCS SG_ 2432669248 AuxSwitchBbLoad3_Status 3000;
BA_REL_ "GenSigTimeoutTime" BU_SG_REL_ WRCS SG_ 2432669248 AuxSwitchBbLoad3_Status 120;
BA_REL_ "GenSigFirstTimeoutTime" BU_SG_REL_ CCM SG_ 2432669248 BunkH2TempInc_ButtonStatus 3000;
BA_REL_ "GenSigTimeoutTime" BU_SG_REL_ CCM SG_ 2432669248 BunkH2TempInc_ButtonStatus 120;
BA_REL_ "GenSigFirstTimeoutTime" BU_SG_REL_ LECM3 SG_ 2432669248 AudioVolumeIndicationCmd 3000;
BA_REL_ "GenSigTimeoutTime" BU_SG_REL_ LECM3 SG_ 2432669248 AudioVolumeIndicationCmd 120;
BA_REL_ "GenSigFirstTimeoutTime" BU_SG_REL_ LECM1 SG_ 2432669248 AudioVolumeIndicationCmd 3000;
BA_REL_ "GenSigTimeoutTime" BU_SG_REL_ LECM1 SG_ 2432669248 AudioVolumeIndicationCmd 120;
BA_REL_ "GenSigFirstTimeoutTime" BU_SG_REL_ CCM SG_ 2432669248 DayOfWeek_stat 3000;
BA_REL_ "GenSigTimeoutTime" BU_SG_REL_ CCM SG_ 2432669248 DayOfWeek_stat 120;
BA_REL_ "GenSigFirstTimeoutTime" BU_SG_REL_ LECM1 SG_ 2432669248 DayOfWeek_stat 3000;
BA_REL_ "GenSigTimeoutTime" BU_SG_REL_ LECM1 SG_ 2432669248 DayOfWeek_stat 120;
BA_REL_ "GenSigFirstTimeoutTime" BU_SG_REL_ CCM SG_ 2432651584 ParkHeaterTimerReleased_stat 3000;
BA_REL_ "GenSigTimeoutTime" BU_SG_REL_ CCM SG_ 2432651584 ParkHeaterTimerReleased_stat 120;
BA_REL_ "GenSigFirstTimeoutTime" BU_SG_REL_ CCM SG_ 2432651584 Washing_HMI_rqst 3000;
BA_REL_ "GenSigTimeoutTime" BU_SG_REL_ CCM SG_ 2432651584 Washing_HMI_rqst 120;
BA_REL_ "GenSigFirstTimeoutTime" BU_SG_REL_ CCM SG_ 2432651584 BunkH2ParkHeater_ButtonStatus 3000;
BA_REL_ "GenSigTimeoutTime" BU_SG_REL_ CCM SG_ 2432651584 BunkH2ParkHeater_ButtonStatus 120;
BA_REL_ "GenSigFirstTimeoutTime" BU_SG_REL_ CCM SG_ 2432651584 BunkBTempDec_ButtonStatus 3000;
BA_REL_ "GenSigTimeoutTime" BU_SG_REL_ CCM SG_ 2432651584 BunkBTempDec_ButtonStatus 120;
BA_REL_ "GenSigFirstTimeoutTime" BU_SG_REL_ LECM3 SG_ 2432651584 AudioSystemStatus 3000;
BA_REL_ "GenSigTimeoutTime" BU_SG_REL_ LECM3 SG_ 2432651584 AudioSystemStatus 120;
BA_REL_ "GenSigFirstTimeoutTime" BU_SG_REL_ LECM1 SG_ 2432651584 AudioSystemStatus 3000;
BA_REL_ "GenSigTimeoutTime" BU_SG_REL_ LECM1 SG_ 2432651584 AudioSystemStatus 120;
BA_REL_ "GenSigFirstTimeoutTime" BU_SG_REL_ CCM SG_ 2432651584 BunkH2TempDec_ButtonStatus 3000;
BA_REL_ "GenSigTimeoutTime" BU_SG_REL_ CCM SG_ 2432651584 BunkH2TempDec_ButtonStatus 120;
BA_REL_ "GenSigFirstTimeoutTime" BU_SG_REL_ CCM SG_ 2432651584 BunkH2PHTimer_rqst_StartTimeMin 3000;
BA_REL_ "GenSigTimeoutTime" BU_SG_REL_ CCM SG_ 2432651584 BunkH2PHTimer_rqst_StartTimeMin 120;
BA_REL_ "GenSigFirstTimeoutTime" BU_SG_REL_ CCM SG_ 2432651584 BunkH2PHTimer_rqst_DurnTimeMin 3000;
BA_REL_ "GenSigTimeoutTime" BU_SG_REL_ CCM SG_ 2432651584 BunkH2PHTimer_rqst_DurnTimeMin 120;
BA_REL_ "GenSigFirstTimeoutTime" BU_SG_REL_ CCM SG_ 2432651584 BunkBParkHeater_ButtonStatus 3000;
BA_REL_ "GenSigTimeoutTime" BU_SG_REL_ CCM SG_ 2432651584 BunkBParkHeater_ButtonStatus 120;
BA_REL_ "GenSigFirstTimeoutTime" BU_SG_REL_ CCM SG_ 2432651584 BunkH2PHTimer_rqst_StartTimeHr 3000;
BA_REL_ "GenSigTimeoutTime" BU_SG_REL_ CCM SG_ 2432651584 BunkH2PHTimer_rqst_StartTimeHr 120;
BA_REL_ "GenSigFirstTimeoutTime" BU_SG_REL_ CCM SG_ 2432651584 BunkH2PHTimer_rqst_DurnTimeHr 3000;
BA_REL_ "GenSigTimeoutTime" BU_SG_REL_ CCM SG_ 2432651584 BunkH2PHTimer_rqst_DurnTimeHr 120;
BA_REL_ "GenSigFirstTimeoutTime" BU_SG_REL_ CCM SG_ 2432651584 BunkBTempInc_ButtonStatus 3000;
BA_REL_ "GenSigTimeoutTime" BU_SG_REL_ CCM SG_ 2432651584 BunkBTempInc_ButtonStatus 120;
BA_REL_ "GenSigFirstTimeoutTime" BU_SG_REL_ CCM SG_ 2432651584 PtosStatus 3000;
BA_REL_ "GenSigTimeoutTime" BU_SG_REL_ CCM SG_ 2432651584 PtosStatus 500;
BA_REL_ "GenSigFirstTimeoutTime" BU_SG_REL_ CCM SG_ 2432651584 BunkB1ParkHeaterBtn_stat 3000;
BA_REL_ "GenSigTimeoutTime" BU_SG_REL_ CCM SG_ 2432651584 BunkB1ParkHeaterBtn_stat 120;
BA_REL_ "GenSigFirstTimeoutTime" BU_SG_REL_ CCM SG_ 2432651584 BunkH2PHTimer_rqst_Timer_cmd 3000;
BA_REL_ "GenSigTimeoutTime" BU_SG_REL_ CCM SG_ 2432651584 BunkH2PHTimer_rqst_Timer_cmd 120;
BA_REL_ "GenSigFirstTimeoutTime" BU_SG_REL_ CMS SG_ 2431745856 BacklightCmd 3000;
BA_REL_ "GenSigTimeoutTime" BU_SG_REL_ CMS SG_ 2431745856 BacklightCmd 100;
BA_REL_ "GenSigFirstTimeoutTime" BU_SG_REL_ CCM SG_ 2431745856 BacklightCmd 3000;
BA_REL_ "GenSigTimeoutTime" BU_SG_REL_ CCM SG_ 2431745856 BacklightCmd 60;
BA_REL_ "GenSigFirstTimeoutTime" BU_SG_REL_ WRCS SG_ 2431745856 EngineSpeed 3000;
BA_REL_ "GenSigTimeoutTime" BU_SG_REL_ WRCS SG_ 2431745856 EngineSpeed 500;
BA_REL_ "GenSigFirstTimeoutTime" BU_SG_REL_ CCM SG_ 2431745856 EngineSpeed 3000;
BA_REL_ "GenSigTimeoutTime" BU_SG_REL_ CCM SG_ 2431745856 EngineSpeed 500;
BA_REL_ "GenSigFirstTimeoutTime" BU_SG_REL_ SRS SG_ 2431745856 EngineSpeed 3000;
BA_REL_ "GenSigTimeoutTime" BU_SG_REL_ SRS SG_ 2431745856 EngineSpeed 500;
BA_REL_ "GenSigFirstTimeoutTime" BU_SG_REL_ LECM1 SG_ 2431745856 PresetIndicationCmd 3000;
BA_REL_ "GenSigTimeoutTime" BU_SG_REL_ LECM1 SG_ 2431745856 PresetIndicationCmd 60;
BA_REL_ "GenSigFirstTimeoutTime" BU_SG_REL_ LECM3 SG_ 2431745856 VehicleMode 3000;
BA_REL_ "GenSigTimeoutTime" BU_SG_REL_ LECM3 SG_ 2431745856 VehicleMode 500;
BA_REL_ "GenSigFirstTimeoutTime" BU_SG_REL_ WRCS SG_ 2431745856 VehicleMode 3000;
BA_REL_ "GenSigTimeoutTime" BU_SG_REL_ WRCS SG_ 2431745856 VehicleMode 500;
BA_REL_ "GenSigFirstTimeoutTime" BU_SG_REL_ LECM1 SG_ 2431745856 VehicleMode 3000;
BA_REL_ "GenSigTimeoutTime" BU_SG_REL_ LECM1 SG_ 2431745856 VehicleMode 500;
BA_REL_ "GenSigFirstTimeoutTime" BU_SG_REL_ CMS SG_ 2431745856 VehicleMode 3000;
BA_REL_ "GenSigTimeoutTime" BU_SG_REL_ CMS SG_ 2431745856 VehicleMode 500;
BA_REL_ "GenSigFirstTimeoutTime" BU_SG_REL_ CCM SG_ 2431745856 VehicleMode 3000;
BA_REL_ "GenSigTimeoutTime" BU_SG_REL_ CCM SG_ 2431745856 VehicleMode 500;
BA_REL_ "GenSigFirstTimeoutTime" BU_SG_REL_ SRS SG_ 2431745856 VehicleMode 3000;
BA_REL_ "GenSigTimeoutTime" BU_SG_REL_ SRS SG_ 2431745856 VehicleMode 500;
BA_REL_ "GenSigFirstTimeoutTime" BU_SG_REL_ CCM SG_ 2431745856 BunkH2OnOFF_ButtonStatus 3000;
BA_REL_ "GenSigTimeoutTime" BU_SG_REL_ CCM SG_ 2431745856 BunkH2OnOFF_ButtonStatus 60;
BA_REL_ "GenSigFirstTimeoutTime" BU_SG_REL_ LECM1 SG_ 2431745856 IntLghtModeInd_cmd_EventFlag 3000;
BA_REL_ "GenSigTimeoutTime" BU_SG_REL_ LECM1 SG_ 2431745856 IntLghtModeInd_cmd_EventFlag 60;
BA_REL_ "GenSigFirstTimeoutTime" BU_SG_REL_ WRCS SG_ 2431745856 LevelControlInformation 3000;
BA_REL_ "GenSigTimeoutTime" BU_SG_REL_ WRCS SG_ 2431745856 LevelControlInformation 500;
BA_REL_ "GenSigFirstTimeoutTime" BU_SG_REL_ CMS SG_ 2431745856 WheelBasedVehicleSpeed 3000;
BA_REL_ "GenSigTimeoutTime" BU_SG_REL_ CMS SG_ 2431745856 WheelBasedVehicleSpeed 100;
BA_REL_ "GenSigFirstTimeoutTime" BU_SG_REL_ CCM SG_ 2431745856 WheelBasedVehicleSpeed 3000;
BA_REL_ "GenSigTimeoutTime" BU_SG_REL_ CCM SG_ 2431745856 WheelBasedVehicleSpeed 60;
BA_REL_ "GenSigFirstTimeoutTime" BU_SG_REL_ SRS SG_ 2431745856 WheelBasedVehicleSpeed 3000;
BA_REL_ "GenSigTimeoutTime" BU_SG_REL_ SRS SG_ 2431745856 WheelBasedVehicleSpeed 60;
BA_REL_ "GenSigFirstTimeoutTime" BU_SG_REL_ WRCS SG_ 2431745856 WheelBasedVehicleSpeed 3000;
BA_REL_ "GenSigTimeoutTime" BU_SG_REL_ WRCS SG_ 2431745856 WheelBasedVehicleSpeed 60;
BA_REL_ "GenSigFirstTimeoutTime" BU_SG_REL_ LECM1 SG_ 2431745856 IntLghtModeInd_cmd_IL_Mode 3000;
BA_REL_ "GenSigTimeoutTime" BU_SG_REL_ LECM1 SG_ 2431745856 IntLghtModeInd_cmd_IL_Mode 60;
BA_REL_ "GenSigFirstTimeoutTime" BU_SG_REL_ CCM SG_ 2432650304 EngineCoolantTemp_stat 3000;
BA_REL_ "GenSigTimeoutTime" BU_SG_REL_ CCM SG_ 2432650304 EngineCoolantTemp_stat 120;
BA_REL_ "GenSigFirstTimeoutTime" BU_SG_REL_ SRS SG_ 2432650304 DriverSeatBeltSwitch 3000;
BA_REL_ "GenSigTimeoutTime" BU_SG_REL_ SRS SG_ 2432650304 DriverSeatBeltSwitch 120;
BA_REL_ "GenSigFirstTimeoutTime" BU_SG_REL_ CMS SG_ 2432650304 AmbientAirTemperature 3000;
BA_REL_ "GenSigTimeoutTime" BU_SG_REL_ CMS SG_ 2432650304 AmbientAirTemperature 120;
BA_REL_ "GenSigFirstTimeoutTime" BU_SG_REL_ LECM1 SG_ 2432650304 AmbientAirTemperature 3000;
BA_REL_ "GenSigTimeoutTime" BU_SG_REL_ LECM1 SG_ 2432650304 AmbientAirTemperature 120;
BA_REL_ "GenSigFirstTimeoutTime" BU_SG_REL_ LECM3 SG_ 2432650304 AmbientAirTemperature 3000;
BA_REL_ "GenSigTimeoutTime" BU_SG_REL_ LECM3 SG_ 2432650304 AmbientAirTemperature 120;
BA_REL_ "GenSigFirstTimeoutTime" BU_SG_REL_ CCM SG_ 2432650304 AmbientAirTemperature 3000;
BA_REL_ "GenSigTimeoutTime" BU_SG_REL_ CCM SG_ 2432650304 AmbientAirTemperature 120;
BA_REL_ "GenSigFirstTimeoutTime" BU_SG_REL_ WRCS SG_ 2432650304 AmbientAirTemperature 3000;
BA_REL_ "GenSigTimeoutTime" BU_SG_REL_ WRCS SG_ 2432650304 AmbientAirTemperature 120;
BA_REL_ "GenSigFirstTimeoutTime" BU_SG_REL_ SRS SG_ 2432650304 AmbientAirTemperature 3000;
BA_REL_ "GenSigTimeoutTime" BU_SG_REL_ SRS SG_ 2432650304 AmbientAirTemperature 120;
BA_REL_ "GenSigFirstTimeoutTime" BU_SG_REL_ CMS SG_ 2432650304 DriverMemory_rqst 3000;
BA_REL_ "GenSigTimeoutTime" BU_SG_REL_ CMS SG_ 2432650304 DriverMemory_rqst 120;
BA_REL_ "GenSigFirstTimeoutTime" BU_SG_REL_ CCM SG_ 2432650304 DriverMemory_rqst 3000;
BA_REL_ "GenSigTimeoutTime" BU_SG_REL_ CCM SG_ 2432650304 DriverMemory_rqst 120;
BA_REL_ "GenSigFirstTimeoutTime" BU_SG_REL_ CCM SG_ 2432650304 ReverseGearEngaged 3000;
BA_REL_ "GenSigTimeoutTime" BU_SG_REL_ CCM SG_ 2432650304 ReverseGearEngaged 120;
BA_REL_ "GenSigFirstTimeoutTime" BU_SG_REL_ CCM SG_ 2432650304 ParkBrakeActuationStatus 3000;
BA_REL_ "GenSigTimeoutTime" BU_SG_REL_ CCM SG_ 2432650304 ParkBrakeActuationStatus 500;
BA_REL_ "GenSigFirstTimeoutTime" BU_SG_REL_ CMS SG_ 2432650304 ParkBrakeActuationStatus 3000;
BA_REL_ "GenSigTimeoutTime" BU_SG_REL_ CMS SG_ 2432650304 ParkBrakeActuationStatus 500;
BA_REL_ "GenSigFirstTimeoutTime" BU_SG_REL_ WRCS SG_ 2432650304 ECSStandbyActive 3000;
BA_REL_ "GenSigTimeoutTime" BU_SG_REL_ WRCS SG_ 2432650304 ECSStandbyActive 120;
BA_REL_ "GenSigFirstTimeoutTime" BU_SG_REL_ WRCS SG_ 2432650304 HeightAdjustmentAllowed 3000;
BA_REL_ "GenSigTimeoutTime" BU_SG_REL_ WRCS SG_ 2432650304 HeightAdjustmentAllowed 120;
BA_REL_ "GenSigFirstTimeoutTime" BU_SG_REL_ LECM1 SG_ 2432650304 SelectedTimeFormat_stat 3000;
BA_REL_ "GenSigTimeoutTime" BU_SG_REL_ LECM1 SG_ 2432650304 SelectedTimeFormat_stat 120;
BA_REL_ "GenSigFirstTimeoutTime" BU_SG_REL_ LECM3 SG_ 2432650304 SelectedTimeFormat_stat 3000;
BA_REL_ "GenSigTimeoutTime" BU_SG_REL_ LECM3 SG_ 2432650304 SelectedTimeFormat_stat 120;
BA_REL_ "GenSigFirstTimeoutTime" BU_SG_REL_ LECM3 SG_ 2432650304 SelectedWeightUnit_stat 3000;
BA_REL_ "GenSigTimeoutTime" BU_SG_REL_ LECM3 SG_ 2432650304 SelectedWeightUnit_stat 120;
BA_REL_ "GenSigFirstTimeoutTime" BU_SG_REL_ WRCS SG_ 2432650304 SelectedWeightUnit_stat 3000;
BA_REL_ "GenSigTimeoutTime" BU_SG_REL_ WRCS SG_ 2432650304 SelectedWeightUnit_stat 120;
BA_REL_ "GenSigFirstTimeoutTime" BU_SG_REL_ LECM3 SG_ 2432650304 SelectedDateFormat_stat 3000;
BA_REL_ "GenSigTimeoutTime" BU_SG_REL_ LECM3 SG_ 2432650304 SelectedDateFormat_stat 120;
BA_REL_ "GenSigFirstTimeoutTime" BU_SG_REL_ CCM SG_ 2432650304 FuncIndIlluminationLevel 3000;
BA_REL_ "GenSigTimeoutTime" BU_SG_REL_ CCM SG_ 2432650304 FuncIndIlluminationLevel 120;
BA_REL_ "GenSigFirstTimeoutTime" BU_SG_REL_ CCM SG_ 2432650304 WiperModeStatus 3000;
BA_REL_ "GenSigTimeoutTime" BU_SG_REL_ CCM SG_ 2432650304 WiperModeStatus 120;
BA_REL_ "GenSigFirstTimeoutTime" BU_SG_REL_ CCM SG_ 2432650304 MirrorHeatingMode 3000;
BA_REL_ "GenSigTimeoutTime" BU_SG_REL_ CCM SG_ 2432650304 MirrorHeatingMode 120;
BA_REL_ "GenSigFirstTimeoutTime" BU_SG_REL_ CIOM SG_ 2499098520 WasteHeatTempRequest 3000;
BA_REL_ "GenSigTimeoutTime" BU_SG_REL_ CIOM SG_ 2499098520 WasteHeatTempRequest 600;
BA_REL_ "GenSigFirstTimeoutTime" BU_SG_REL_ CIOM SG_ 2499098520 EACC_TV_Pwr 3000;
BA_REL_ "GenSigTimeoutTime" BU_SG_REL_ CIOM SG_ 2499098520 EACC_TV_Pwr 600;
BA_REL_ "GenSigFirstTimeoutTime" BU_SG_REL_ CIOM SG_ 2499098520 BunkParkClimateStatus 3000;
BA_REL_ "GenSigTimeoutTime" BU_SG_REL_ CIOM SG_ 2499098520 BunkParkClimateStatus 600;
BA_REL_ "GenSigFirstTimeoutTime" BU_SG_REL_ CIOM SG_ 2499098520 TVECH_C_Pwr 3000;
BA_REL_ "GenSigTimeoutTime" BU_SG_REL_ CIOM SG_ 2499098520 TVECH_C_Pwr 600;
BA_REL_ "GenSigFirstTimeoutTime" BU_SG_REL_ CIOM SG_ 2499098520 Req24VforClimateSystem 3000;
BA_REL_ "GenSigTimeoutTime" BU_SG_REL_ CIOM SG_ 2499098520 Req24VforClimateSystem 600;
BA_REL_ "GenSigFirstTimeoutTime" BU_SG_REL_ CIOM SG_ 2499098520 AuxFunCabPreCondition_Stat 3000;
BA_REL_ "GenSigTimeoutTime" BU_SG_REL_ CIOM SG_ 2499098520 AuxFunCabPreCondition_Stat 600;
BA_REL_ "GenSigFirstTimeoutTime" BU_SG_REL_ CIOM SG_ 2499098520 EACC_TV_Voltage 3000;
BA_REL_ "GenSigTimeoutTime" BU_SG_REL_ CIOM SG_ 2499098520 EACC_TV_Voltage 600;
BA_REL_ "GenSigFirstTimeoutTime" BU_SG_REL_ CIOM SG_ 2499098520 TVECH_C_Voltage 3000;
BA_REL_ "GenSigTimeoutTime" BU_SG_REL_ CIOM SG_ 2499098520 TVECH_C_Voltage 600;
BA_REL_ "GenSigFirstTimeoutTime" BU_SG_REL_ CIOM SG_ 2499031960 LifeTimeTVECH_C_ConsEgy 3000;
BA_REL_ "GenSigTimeoutTime" BU_SG_REL_ CIOM SG_ 2499031960 LifeTimeTVECH_C_ConsEgy 600;
BA_REL_ "GenSigFirstTimeoutTime" BU_SG_REL_ CIOM SG_ 2499031960 LifeTimeEACC_TVCabConsEgy 3000;
BA_REL_ "GenSigTimeoutTime" BU_SG_REL_ CIOM SG_ 2499031960 LifeTimeEACC_TVCabConsEgy 600;
BA_REL_ "GenSigFirstTimeoutTime" BU_SG_REL_ CIOM SG_ 2499031960 LifeTimeEACC_TVBattConsEgy 3000;
BA_REL_ "GenSigTimeoutTime" BU_SG_REL_ CIOM SG_ 2499031960 LifeTimeEACC_TVBattConsEgy 600;
BA_REL_ "GenSigFirstTimeoutTime" BU_SG_REL_ CIOM SG_ 2499031960 CabClimateICEEnergyRqst 3000;
BA_REL_ "GenSigTimeoutTime" BU_SG_REL_ CIOM SG_ 2499031960 CabClimateICEEnergyRqst 600;
BA_REL_ "GenSigFirstTimeoutTime" BU_SG_REL_ CIOM SG_ 2566356888 ACStatus 12000;
BA_REL_ "GenSigTimeoutTime" BU_SG_REL_ CIOM SG_ 2566356888 ACStatus 3000;
BA_REL_ "GenSigFirstTimeoutTime" BU_SG_REL_ CIOM SG_ 2566356888 ClimateAirDistStatus_Defrost 12000;
BA_REL_ "GenSigTimeoutTime" BU_SG_REL_ CIOM SG_ 2566356888 ClimateAirDistStatus_Defrost 3000;
BA_REL_ "GenSigFirstTimeoutTime" BU_SG_REL_ CIOM SG_ 2566356888 HVACBlowerLevelStat_AutoStatus 12000;
BA_REL_ "GenSigTimeoutTime" BU_SG_REL_ CIOM SG_ 2566356888 HVACBlowerLevelStat_AutoStatus 3000;
BA_REL_ "GenSigFirstTimeoutTime" BU_SG_REL_ CIOM SG_ 2566356888 MaxDefrostStatus 12000;
BA_REL_ "GenSigTimeoutTime" BU_SG_REL_ CIOM SG_ 2566356888 MaxDefrostStatus 3000;
BA_REL_ "GenSigFirstTimeoutTime" BU_SG_REL_ CIOM SG_ 2566356888 ClimateAirDistStatus_Floor 12000;
BA_REL_ "GenSigTimeoutTime" BU_SG_REL_ CIOM SG_ 2566356888 ClimateAirDistStatus_Floor 3000;
BA_REL_ "GenSigFirstTimeoutTime" BU_SG_REL_ CIOM SG_ 2566356888 BunkHVACBlwrLvlStat_AutoStatus 12000;
BA_REL_ "GenSigTimeoutTime" BU_SG_REL_ CIOM SG_ 2566356888 BunkHVACBlwrLvlStat_AutoStatus 3000;
BA_REL_ "GenSigFirstTimeoutTime" BU_SG_REL_ CIOM SG_ 2566356888 ClimateAirDistStatus_AutoStatus 12000;
BA_REL_ "GenSigTimeoutTime" BU_SG_REL_ CIOM SG_ 2566356888 ClimateAirDistStatus_AutoStatus 3000;
BA_REL_ "GenSigFirstTimeoutTime" BU_SG_REL_ CIOM SG_ 2566356888 ClimateAirDistStatus_Vent 12000;
BA_REL_ "GenSigTimeoutTime" BU_SG_REL_ CIOM SG_ 2566356888 ClimateAirDistStatus_Vent 3000;
BA_REL_ "GenSigFirstTimeoutTime" BU_SG_REL_ CIOM SG_ 2566356888 CabTempStatus 12000;
BA_REL_ "GenSigTimeoutTime" BU_SG_REL_ CIOM SG_ 2566356888 CabTempStatus 3000;
BA_REL_ "GenSigFirstTimeoutTime" BU_SG_REL_ CIOM SG_ 2566356888 ParkingClimateAvailability 12000;
BA_REL_ "GenSigTimeoutTime" BU_SG_REL_ CIOM SG_ 2566356888 ParkingClimateAvailability 3000;
BA_REL_ "GenSigFirstTimeoutTime" BU_SG_REL_ CIOM SG_ 2566356888 HVACBlowerLevelStat_BlowerLevel 12000;
BA_REL_ "GenSigTimeoutTime" BU_SG_REL_ CIOM SG_ 2566356888 HVACBlowerLevelStat_BlowerLevel 3000;
BA_REL_ "GenSigFirstTimeoutTime" BU_SG_REL_ CIOM SG_ 2566356888 BunkClimatePowerStatus 12000;
BA_REL_ "GenSigTimeoutTime" BU_SG_REL_ CIOM SG_ 2566356888 BunkClimatePowerStatus 3000;
BA_REL_ "GenSigFirstTimeoutTime" BU_SG_REL_ CIOM SG_ 2566356888 BunkTempStatus 12000;
BA_REL_ "GenSigTimeoutTime" BU_SG_REL_ CIOM SG_ 2566356888 BunkTempStatus 3000;
BA_REL_ "GenSigFirstTimeoutTime" BU_SG_REL_ CIOM SG_ 2566356888 ClimateAutoStatus 12000;
BA_REL_ "GenSigTimeoutTime" BU_SG_REL_ CIOM SG_ 2566356888 ClimateAutoStatus 3000;
BA_REL_ "GenSigFirstTimeoutTime" BU_SG_REL_ CIOM SG_ 2566356888 BunkClimateAutoStatus 12000;
BA_REL_ "GenSigTimeoutTime" BU_SG_REL_ CIOM SG_ 2566356888 BunkClimateAutoStatus 3000;
BA_REL_ "GenSigFirstTimeoutTime" BU_SG_REL_ CIOM SG_ 2566356888 BunkHVACBlwrLvlStat_BlowerLevel 12000;
BA_REL_ "GenSigTimeoutTime" BU_SG_REL_ CIOM SG_ 2566356888 BunkHVACBlwrLvlStat_BlowerLevel 3000;
BA_REL_ "GenSigFirstTimeoutTime" BU_SG_REL_ CIOM SG_ 2566356888 ClimatePowerStatus 12000;
BA_REL_ "GenSigTimeoutTime" BU_SG_REL_ CIOM SG_ 2566356888 ClimatePowerStatus 3000;
BA_REL_ "GenSigFirstTimeoutTime" BU_SG_REL_ CIOM SG_ 2566356888 AirRecirculationStatus 12000;
BA_REL_ "GenSigTimeoutTime" BU_SG_REL_ CIOM SG_ 2566356888 AirRecirculationStatus 3000;
BA_REL_ "GenSigFirstTimeoutTime" BU_SG_REL_ CIOM SG_ 2566356888 BunkACStatus 12000;
BA_REL_ "GenSigTimeoutTime" BU_SG_REL_ CIOM SG_ 2566356888 BunkACStatus 3000;
BA_REL_ "GenSigFirstTimeoutTime" BU_SG_REL_ CIOM SG_ 2561091992 CabCoolingLoadStaus 24000;
BA_REL_ "GenSigTimeoutTime" BU_SG_REL_ CIOM SG_ 2561091992 CabCoolingLoadStaus 6000;
BA_REL_ "GenSigFirstTimeoutTime" BU_SG_REL_ CIOM SG_ 2561091992 CabClimateFnRqst_FnNum 24000;
BA_REL_ "GenSigTimeoutTime" BU_SG_REL_ CIOM SG_ 2561091992 CabClimateFnRqst_FnNum 6000;
BA_REL_ "GenSigFirstTimeoutTime" BU_SG_REL_ CIOM SG_ 2561091992 ChlrVlvPsnRqst 24000;
BA_REL_ "GenSigTimeoutTime" BU_SG_REL_ CIOM SG_ 2561091992 ChlrVlvPsnRqst 6000;
BA_REL_ "GenSigFirstTimeoutTime" BU_SG_REL_ CIOM SG_ 2561091992 CoolantTempBeforeCabLoop 24000;
BA_REL_ "GenSigTimeoutTime" BU_SG_REL_ CIOM SG_ 2561091992 CoolantTempBeforeCabLoop 6000;
BA_REL_ "GenSigFirstTimeoutTime" BU_SG_REL_ CIOM SG_ 2561091992 CabClimateFnRqst_FnPower 24000;
BA_REL_ "GenSigTimeoutTime" BU_SG_REL_ CIOM SG_ 2561091992 CabClimateFnRqst_FnPower 6000;
BA_REL_ "GenSigFirstTimeoutTime" BU_SG_REL_ CIOM SG_ 2561091992 ChlrAvailPwr 24000;
BA_REL_ "GenSigTimeoutTime" BU_SG_REL_ CIOM SG_ 2561091992 ChlrAvailPwr 6000;
BA_REL_ "GenSigFirstTimeoutTime" BU_SG_REL_ CIOM SG_ 2561091992 CabHeatManStatus 24000;
BA_REL_ "GenSigTimeoutTime" BU_SG_REL_ CIOM SG_ 2561091992 CabHeatManStatus 6000;
BA_REL_ "GenSigFirstTimeoutTime" BU_SG_REL_ LECM1 SG_ 2432640664 PHTimer2_stat_Recurrence 3000;
BA_REL_ "GenSigTimeoutTime" BU_SG_REL_ LECM1 SG_ 2432640664 PHTimer2_stat_Recurrence 500;
BA_REL_ "GenSigFirstTimeoutTime" BU_SG_REL_ LECM1 SG_ 2432640664 PHTimer2_stat_Hours 3000;
BA_REL_ "GenSigTimeoutTime" BU_SG_REL_ LECM1 SG_ 2432640664 PHTimer2_stat_Hours 500;
BA_REL_ "GenSigFirstTimeoutTime" BU_SG_REL_ LECM1 SG_ 2432640664 PHTimer3_stat_Temp 3000;
BA_REL_ "GenSigTimeoutTime" BU_SG_REL_ LECM1 SG_ 2432640664 PHTimer3_stat_Temp 500;
BA_REL_ "GenSigFirstTimeoutTime" BU_SG_REL_ LECM1 SG_ 2432640664 PHTimer3_stat_Hours 3000;
BA_REL_ "GenSigTimeoutTime" BU_SG_REL_ LECM1 SG_ 2432640664 PHTimer3_stat_Hours 500;
BA_REL_ "GenSigFirstTimeoutTime" BU_SG_REL_ LECM1 SG_ 2432640664 PHTimer3_stat_Status 3000;
BA_REL_ "GenSigTimeoutTime" BU_SG_REL_ LECM1 SG_ 2432640664 PHTimer3_stat_Status 500;
BA_REL_ "GenSigFirstTimeoutTime" BU_SG_REL_ LECM1 SG_ 2432640664 PHTimer2_stat_StartDay 3000;
BA_REL_ "GenSigTimeoutTime" BU_SG_REL_ LECM1 SG_ 2432640664 PHTimer2_stat_StartDay 500;
BA_REL_ "GenSigFirstTimeoutTime" BU_SG_REL_ LECM1 SG_ 2432640664 PHTimer2_stat_Temp 3000;
BA_REL_ "GenSigTimeoutTime" BU_SG_REL_ LECM1 SG_ 2432640664 PHTimer2_stat_Temp 500;
BA_REL_ "GenSigFirstTimeoutTime" BU_SG_REL_ LECM1 SG_ 2432640664 PHTimer2_stat_Status 3000;
BA_REL_ "GenSigTimeoutTime" BU_SG_REL_ LECM1 SG_ 2432640664 PHTimer2_stat_Status 500;
BA_REL_ "GenSigFirstTimeoutTime" BU_SG_REL_ LECM1 SG_ 2432640664 PHTimer2_stat_Minutes 3000;
BA_REL_ "GenSigTimeoutTime" BU_SG_REL_ LECM1 SG_ 2432640664 PHTimer2_stat_Minutes 500;
BA_REL_ "GenSigFirstTimeoutTime" BU_SG_REL_ LECM1 SG_ 2432640664 PHTimer3_stat_Minutes 3000;
BA_REL_ "GenSigTimeoutTime" BU_SG_REL_ LECM1 SG_ 2432640664 PHTimer3_stat_Minutes 500;
BA_REL_ "GenSigFirstTimeoutTime" BU_SG_REL_ LECM1 SG_ 2432640664 PHTimer3_stat_Recurrence 3000;
BA_REL_ "GenSigTimeoutTime" BU_SG_REL_ LECM1 SG_ 2432640664 PHTimer3_stat_Recurrence 500;
BA_REL_ "GenSigFirstTimeoutTime" BU_SG_REL_ LECM1 SG_ 2432640664 PHTimer3_stat_StartDay 3000;
BA_REL_ "GenSigTimeoutTime" BU_SG_REL_ LECM1 SG_ 2432640664 PHTimer3_stat_StartDay 500;
BA_REL_ "GenSigFirstTimeoutTime" BU_SG_REL_ LECM1 SG_ 2432644760 PHTimer1_stat_Minutes 3000;
BA_REL_ "GenSigTimeoutTime" BU_SG_REL_ LECM1 SG_ 2432644760 PHTimer1_stat_Minutes 500;
BA_REL_ "GenSigFirstTimeoutTime" BU_SG_REL_ CIOM SG_ 2432644760 PHTimer1_stat_Minutes 3000;
BA_REL_ "GenSigTimeoutTime" BU_SG_REL_ CIOM SG_ 2432644760 PHTimer1_stat_Minutes 500;
BA_REL_ "GenSigFirstTimeoutTime" BU_SG_REL_ CIOM SG_ 2432644760 ExtraHeating_status 3000;
BA_REL_ "GenSigTimeoutTime" BU_SG_REL_ CIOM SG_ 2432644760 ExtraHeating_status 300;
BA_REL_ "GenSigFirstTimeoutTime" BU_SG_REL_ CIOM SG_ 2432644760 AQSmode_Status 3000;
BA_REL_ "GenSigTimeoutTime" BU_SG_REL_ CIOM SG_ 2432644760 AQSmode_Status 300;
BA_REL_ "GenSigFirstTimeoutTime" BU_SG_REL_ CIOM SG_ 2432644760 ParkingClimate_IndicationCmd 3000;
BA_REL_ "GenSigTimeoutTime" BU_SG_REL_ CIOM SG_ 2432644760 ParkingClimate_IndicationCmd 300;
BA_REL_ "GenSigFirstTimeoutTime" BU_SG_REL_ CIOM SG_ 2432644760 ACmode_Status 3000;
BA_REL_ "GenSigTimeoutTime" BU_SG_REL_ CIOM SG_ 2432644760 ACmode_Status 300;
BA_REL_ "GenSigFirstTimeoutTime" BU_SG_REL_ CIOM SG_ 2432644760 ShortStopHeater_cmd 3000;
BA_REL_ "GenSigTimeoutTime" BU_SG_REL_ CIOM SG_ 2432644760 ShortStopHeater_cmd 300;
BA_REL_ "GenSigFirstTimeoutTime" BU_SG_REL_ LECM1 SG_ 2432644760 PHTimer1_stat_Status 3000;
BA_REL_ "GenSigTimeoutTime" BU_SG_REL_ LECM1 SG_ 2432644760 PHTimer1_stat_Status 500;
BA_REL_ "GenSigFirstTimeoutTime" BU_SG_REL_ CIOM SG_ 2432644760 PHTimer1_stat_Status 3000;
BA_REL_ "GenSigTimeoutTime" BU_SG_REL_ CIOM SG_ 2432644760 PHTimer1_stat_Status 500;
BA_REL_ "GenSigFirstTimeoutTime" BU_SG_REL_ LECM1 SG_ 2432644760 PHTimer1_stat_StartDay 3000;
BA_REL_ "GenSigTimeoutTime" BU_SG_REL_ LECM1 SG_ 2432644760 PHTimer1_stat_StartDay 500;
BA_REL_ "GenSigFirstTimeoutTime" BU_SG_REL_ CIOM SG_ 2432644760 PHTimer1_stat_StartDay 3000;
BA_REL_ "GenSigTimeoutTime" BU_SG_REL_ CIOM SG_ 2432644760 PHTimer1_stat_StartDay 500;
BA_REL_ "GenSigFirstTimeoutTime" BU_SG_REL_ LECM1 SG_ 2432644760 PHTimer1_stat_Duration 3000;
BA_REL_ "GenSigTimeoutTime" BU_SG_REL_ LECM1 SG_ 2432644760 PHTimer1_stat_Duration 500;
BA_REL_ "GenSigFirstTimeoutTime" BU_SG_REL_ CIOM SG_ 2432644760 PHTimer1_stat_Duration 3000;
BA_REL_ "GenSigTimeoutTime" BU_SG_REL_ CIOM SG_ 2432644760 PHTimer1_stat_Duration 500;
BA_REL_ "GenSigFirstTimeoutTime" BU_SG_REL_ CIOM SG_ 2432644760 ReqVehTVSforClimateSystem 3000;
BA_REL_ "GenSigTimeoutTime" BU_SG_REL_ CIOM SG_ 2432644760 ReqVehTVSforClimateSystem 300;
BA_REL_ "GenSigFirstTimeoutTime" BU_SG_REL_ CIOM SG_ 2432644760 AutoBlowerLevel_Status 3000;
BA_REL_ "GenSigTimeoutTime" BU_SG_REL_ CIOM SG_ 2432644760 AutoBlowerLevel_Status 300;
BA_REL_ "GenSigFirstTimeoutTime" BU_SG_REL_ LECM1 SG_ 2432644760 PHTimer1_stat_Temp 3000;
BA_REL_ "GenSigTimeoutTime" BU_SG_REL_ LECM1 SG_ 2432644760 PHTimer1_stat_Temp 500;
BA_REL_ "GenSigFirstTimeoutTime" BU_SG_REL_ CIOM SG_ 2432644760 PHTimer1_stat_Temp 3000;
BA_REL_ "GenSigTimeoutTime" BU_SG_REL_ CIOM SG_ 2432644760 PHTimer1_stat_Temp 500;
BA_REL_ "GenSigFirstTimeoutTime" BU_SG_REL_ CIOM SG_ 2432644760 PHCleanStatFeedback 3000;
BA_REL_ "GenSigTimeoutTime" BU_SG_REL_ CIOM SG_ 2432644760 PHCleanStatFeedback 300;
BA_REL_ "GenSigFirstTimeoutTime" BU_SG_REL_ CIOM SG_ 2432644760 PHTimer1_stat_Recurrence 3000;
BA_REL_ "GenSigTimeoutTime" BU_SG_REL_ CIOM SG_ 2432644760 PHTimer1_stat_Recurrence 500;
BA_REL_ "GenSigFirstTimeoutTime" BU_SG_REL_ LECM1 SG_ 2432644760 PHTimer1_stat_Recurrence 3000;
BA_REL_ "GenSigTimeoutTime" BU_SG_REL_ LECM1 SG_ 2432644760 PHTimer1_stat_Recurrence 500;
BA_REL_ "GenSigFirstTimeoutTime" BU_SG_REL_ LECM1 SG_ 2432644760 PHTimer1_stat_Hours 3000;
BA_REL_ "GenSigTimeoutTime" BU_SG_REL_ LECM1 SG_ 2432644760 PHTimer1_stat_Hours 500;
BA_REL_ "GenSigFirstTimeoutTime" BU_SG_REL_ CIOM SG_ 2432644760 PHTimer1_stat_Hours 3000;
BA_REL_ "GenSigTimeoutTime" BU_SG_REL_ CIOM SG_ 2432644760 PHTimer1_stat_Hours 500;
BA_REL_ "GenSigFirstTimeoutTime" BU_SG_REL_ CIOM SG_ 2432644760 AutoDefogmode_Status 3000;
BA_REL_ "GenSigTimeoutTime" BU_SG_REL_ CIOM SG_ 2432644760 AutoDefogmode_Status 300;
BA_REL_ "GenSigFirstTimeoutTime" BU_SG_REL_ CIOM SG_ 2432645496 ParkHeaterCooler_ButtonStatus 3000;
BA_REL_ "GenSigTimeoutTime" BU_SG_REL_ CIOM SG_ 2432645496 ParkHeaterCooler_ButtonStatus 120;
BA_REL_ "GenSigFirstTimeoutTime" BU_SG_REL_ CIOM SG_ 2432645496 AirFlowSelectionUpBtn_stat 3000;
BA_REL_ "GenSigTimeoutTime" BU_SG_REL_ CIOM SG_ 2432645496 AirFlowSelectionUpBtn_stat 120;
BA_REL_ "GenSigFirstTimeoutTime" BU_SG_REL_ CIOM SG_ 2432645496 Auto_ButtonStatus 3000;
BA_REL_ "GenSigTimeoutTime" BU_SG_REL_ CIOM SG_ 2432645496 Auto_ButtonStatus 120;
BA_REL_ "GenSigFirstTimeoutTime" BU_SG_REL_ CIOM SG_ 2432645496 Temperature_FreeWheelStatus 3000;
BA_REL_ "GenSigTimeoutTime" BU_SG_REL_ CIOM SG_ 2432645496 Temperature_FreeWheelStatus 120;
BA_REL_ "GenSigFirstTimeoutTime" BU_SG_REL_ CIOM SG_ 2432645496 AC_ButtonStatus 3000;
BA_REL_ "GenSigTimeoutTime" BU_SG_REL_ CIOM SG_ 2432645496 AC_ButtonStatus 120;
BA_REL_ "GenSigFirstTimeoutTime" BU_SG_REL_ CIOM SG_ 2432645496 WindscreenDefrost_ButtonStatus 3000;
BA_REL_ "GenSigTimeoutTime" BU_SG_REL_ CIOM SG_ 2432645496 WindscreenDefrost_ButtonStatus 120;
BA_REL_ "GenSigFirstTimeoutTime" BU_SG_REL_ CIOM SG_ 2432645496 Recirc_ButtonStatus 3000;
BA_REL_ "GenSigTimeoutTime" BU_SG_REL_ CIOM SG_ 2432645496 Recirc_ButtonStatus 120;
BA_REL_ "GenSigFirstTimeoutTime" BU_SG_REL_ CIOM SG_ 2432645496 ChillerPumpRequest 3000;
BA_REL_ "GenSigTimeoutTime" BU_SG_REL_ CIOM SG_ 2432645496 ChillerPumpRequest 120;
BA_REL_ "GenSigFirstTimeoutTime" BU_SG_REL_ CIOM SG_ 2432645496 AirFlowSelectionDownBtn_stat 3000;
BA_REL_ "GenSigTimeoutTime" BU_SG_REL_ CIOM SG_ 2432645496 AirFlowSelectionDownBtn_stat 120;
BA_REL_ "GenSigFirstTimeoutTime" BU_SG_REL_ CIOM SG_ 2432645496 AirFlowSelectionFrontBtn_stat 3000;
BA_REL_ "GenSigTimeoutTime" BU_SG_REL_ CIOM SG_ 2432645496 AirFlowSelectionFrontBtn_stat 120;
BA_REL_ "GenSigFirstTimeoutTime" BU_SG_REL_ CIOM SG_ 2432645496 AcCoolantPumpEngagementRequest 3000;
BA_REL_ "GenSigTimeoutTime" BU_SG_REL_ CIOM SG_ 2432645496 AcCoolantPumpEngagementRequest 120;
BA_REL_ "GenSigFirstTimeoutTime" BU_SG_REL_ CIOM SG_ 2432645496 AirBlowerSpeed_FreeWheelStatus 3000;
BA_REL_ "GenSigTimeoutTime" BU_SG_REL_ CIOM SG_ 2432645496 AirBlowerSpeed_FreeWheelStatus 120;
BA_REL_ "GenSigFirstTimeoutTime" BU_SG_REL_ CIOM SG_ 2432639640 ACmode_IndicationCmd 3000;
BA_REL_ "GenSigTimeoutTime" BU_SG_REL_ CIOM SG_ 2432639640 ACmode_IndicationCmd 120;
BA_REL_ "GenSigFirstTimeoutTime" BU_SG_REL_ CIOM SG_ 2432639640 PHTimer_rqst_SetAlarmOper 3000;
BA_REL_ "GenSigTimeoutTime" BU_SG_REL_ CIOM SG_ 2432639640 PHTimer_rqst_SetAlarmOper 120;
BA_REL_ "GenSigFirstTimeoutTime" BU_SG_REL_ CIOM SG_ 2432639640 PHTimer_rqst_Hours 3000;
BA_REL_ "GenSigTimeoutTime" BU_SG_REL_ CIOM SG_ 2432639640 PHTimer_rqst_Hours 120;
BA_REL_ "GenSigFirstTimeoutTime" BU_SG_REL_ CIOM SG_ 2432639640 PHTimer_rqst_Minutes 3000;
BA_REL_ "GenSigTimeoutTime" BU_SG_REL_ CIOM SG_ 2432639640 PHTimer_rqst_Minutes 120;
BA_REL_ "GenSigFirstTimeoutTime" BU_SG_REL_ CIOM SG_ 2432639640 CabInteriorTempVentilated_Stat 3000;
BA_REL_ "GenSigTimeoutTime" BU_SG_REL_ CIOM SG_ 2432639640 CabInteriorTempVentilated_Stat 120;
BA_REL_ "GenSigFirstTimeoutTime" BU_SG_REL_ CIOM SG_ 2432639640 AirBleedValveCtrl 3000;
BA_REL_ "GenSigTimeoutTime" BU_SG_REL_ CIOM SG_ 2432639640 AirBleedValveCtrl 120;
BA_REL_ "GenSigFirstTimeoutTime" BU_SG_REL_ CIOM SG_ 2432639640 ParkingHeaterCleaning_Rqst 3000;
BA_REL_ "GenSigTimeoutTime" BU_SG_REL_ CIOM SG_ 2432639640 ParkingHeaterCleaning_Rqst 120;
BA_REL_ "GenSigFirstTimeoutTime" BU_SG_REL_ LECM1 SG_ 2432639640 ParkingHeater_IndicationCmd 3000;
BA_REL_ "GenSigTimeoutTime" BU_SG_REL_ LECM1 SG_ 2432639640 ParkingHeater_IndicationCmd 120;
BA_REL_ "GenSigFirstTimeoutTime" BU_SG_REL_ CIOM SG_ 2432639640 ParkingHeater_IndicationCmd 3000;
BA_REL_ "GenSigTimeoutTime" BU_SG_REL_ CIOM SG_ 2432639640 ParkingHeater_IndicationCmd 120;
BA_REL_ "GenSigFirstTimeoutTime" BU_SG_REL_ CIOM SG_ 2432639640 AC_CompressorClutchCmd 3000;
BA_REL_ "GenSigTimeoutTime" BU_SG_REL_ CIOM SG_ 2432639640 AC_CompressorClutchCmd 120;
BA_REL_ "GenSigFirstTimeoutTime" BU_SG_REL_ CIOM SG_ 2432639640 PHTimer_rqst_DayOfWeekRq 3000;
BA_REL_ "GenSigTimeoutTime" BU_SG_REL_ CIOM SG_ 2432639640 PHTimer_rqst_DayOfWeekRq 120;
BA_REL_ "GenSigFirstTimeoutTime" BU_SG_REL_ CIOM SG_ 2432637336 ACCoolingFanSpeedRequest_CCM 3000;
BA_REL_ "GenSigTimeoutTime" BU_SG_REL_ CIOM SG_ 2432637336 ACCoolingFanSpeedRequest_CCM 500;
BA_REL_ "GenSigFirstTimeoutTime" BU_SG_REL_ LECM1 SG_ 2432637336 TemperatureRqstIndication_cmd 3000;
BA_REL_ "GenSigTimeoutTime" BU_SG_REL_ LECM1 SG_ 2432637336 TemperatureRqstIndication_cmd 120;
BA_REL_ "GenSigFirstTimeoutTime" BU_SG_REL_ CIOM SG_ 2432637336 TemperatureRqstIndication_cmd 3000;
BA_REL_ "GenSigTimeoutTime" BU_SG_REL_ CIOM SG_ 2432637336 TemperatureRqstIndication_cmd 120;
BA_REL_ "GenSigFirstTimeoutTime" BU_SG_REL_ CIOM SG_ 2432637336 MirrorHeatNormModeBtn_stat 3000;
BA_REL_ "GenSigTimeoutTime" BU_SG_REL_ CIOM SG_ 2432637336 MirrorHeatNormModeBtn_stat 120;
BA_REL_ "GenSigFirstTimeoutTime" BU_SG_REL_ CIOM SG_ 2432637336 WindscreenDefrostInd_cmd 3000;
BA_REL_ "GenSigTimeoutTime" BU_SG_REL_ CIOM SG_ 2432637336 WindscreenDefrostInd_cmd 120;
VAL_ 2432669248 AuxSwitchBbLoad2_Status 3 "InactiveActive_NotAvailable" 2 "InactiveActive_Error" 1 "InactiveActive_Active" 0 "InactiveActive_Inactive" ;
VAL_ 2432669248 DoorLock_stat 15 "DoorLock_stat_NotAvailable" 14 "DoorLock_stat_Error" 4 "DoorLock_stat_BothDoorsAreLocked" 3 "DoorLock_stat_PassengerDoorIsUnlocked" 2 "DoorLock_stat_DriverDoorIsUnlocked" 1 "DoorLock_stat_BothDoorsAreUnlocked" 0 "DoorLock_stat_Idle" ;
VAL_ 2432669248 PSWindowPosition 7 "WindowPosition_NotAvailable" 6 "WindowPosition_Error" 5 "WindowPosition_Spare" 4 "WindowPosition_UnknownPosition" 3 "WindowPosition_Open_70_100Percent" 2 "WindowPosition_Open_30_70Percent" 1 "WindowPosition_Open_0_30Percent" 0 "WindowPosition_Closed" ;
VAL_ 2432669248 AuxSwitchBbLoad1_Status 3 "InactiveActive_NotAvailable" 2 "InactiveActive_Error" 1 "InactiveActive_Active" 0 "InactiveActive_Inactive" ;
VAL_ 2432669248 ReducedLoadMode_stat 3 "ReducedLoadMode_stat_NotAvailable" 2 "ReducedLoadMode_stat_Error" 1 "ReducedLoadMode_stat_ReducedLoadMode" 0 "ReducedLoadMode_stat_NormalMode" ;
VAL_ 2432669248 DriverDoorAjar_stat 7 "DoorAjar_stat_NotAvailable" 6 "DoorAjar_stat_Error" 2 "DoorAjar_stat_DoorOpen" 1 "DoorAjar_stat_DoorClosed" 0 "DoorAjar_stat_Idle" ;
VAL_ 2432669248 AuxSwitchBbLoad6_Status 3 "InactiveActive_NotAvailable" 2 "InactiveActive_Error" 1 "InactiveActive_Active" 0 "InactiveActive_Inactive" ;
VAL_ 2432669248 BunkBacklightCmd 31 "BacklightCmd_NotAvailable" 30 "BacklightCmd_Error" 16 "BacklightCmd_BacklightLevel16" 15 "BacklightCmd_BacklightLevel15" 14 "BacklightCmd_BacklightLevel14" 13 "BacklightCmd_BacklightLevel13" 12 "BacklightCmd_BacklightLevel12" 11 "BacklightCmd_BacklightLevel11" 10 "BacklightCmd_BacklightLevel10" 9 "BacklightCmd_BacklightLevel9" 8 "BacklightCmd_BacklightLevel8" 7 "BacklightCmd_BacklightLevel7" 6 "BacklightCmd_BacklightLevel6" 5 "BacklightCmd_BacklightLevel5" 4 "BacklightCmd_BacklightLevel4" 3 "BacklightCmd_BacklightLevel3" 2 "BacklightCmd_BacklightLevel2" 1 "BacklightCmd_BacklightLevel1" 0 "BacklightCmd_BacklightOff" ;
VAL_ 2432669248 AuxSwitchBbLoad4_Status 3 "InactiveActive_NotAvailable" 2 "InactiveActive_Error" 1 "InactiveActive_Active" 0 "InactiveActive_Inactive" ;
VAL_ 2432669248 DSWindowPosition 7 "WindowPosition_NotAvailable" 6 "WindowPosition_Error" 5 "WindowPosition_Spare" 4 "WindowPosition_UnknownPosition" 3 "WindowPosition_Open_70_100Percent" 2 "WindowPosition_Open_30_70Percent" 1 "WindowPosition_Open_0_30Percent" 0 "WindowPosition_Closed" ;
VAL_ 2432669248 SelectedLanguage_stat 63 "Language_NotAvailable" 62 "Language_Error" 61 "Language_Spare_26" 60 "Language_Spare_25" 59 "Language_Spare_24" 58 "Language_Spare_23" 57 "Language_Spare_22" 56 "Language_Spare_21" 55 "Language_Spare_20" 54 "Language_Spare_19" 53 "Language_Spare_18" 52 "Language_Spare_17" 51 "Language_Spare_16" 50 "Language_Spare_15" 49 "Language_Spare_14" 48 "Language_Spare_13" 47 "Language_Spare_12" 46 "Language_Spare_11" 45 "Language_Spare_10" 44 "Language_Spare_09" 43 "Language_Spare_08" 42 "Language_US_English" 41 "Language_MexicanSpanish" 40 "Language_CandianFrench" 39 "Language_Punjabi" 38 "Language_Malay_Indonesian" 37 "Language_Ukrainian" 36 "Language_Bosnian" 35 "Language_Croatian" 34 "Language_Numeric" 33 "Language_Japanese" 32 "Language_Korean" 31 "Language_Chinese" 30 "Language_Thai" 29 "Language_Arabic" 28 "Language_Farsi" 27 "Language_Hebrew" 26 "Language_Turkish" 25 "Language_Hungarian" 24 "Language_Slovak" 23 "Language_Czech" 22 "Language_Slovenian" 21 "Language_Serbian" 20 "Language_Greek" 19 "Language_Bulgarian" 18 "Language_Italian" 17 "Language_Dutch" 16 "Language_Rumanian" 15 "Language_BrazilianPortugese" 14 "Language_Portugese" 13 "Language_Spanish" 12 "Language_French" 11 "Language_German" 10 "Language_Polish" 9 "Language_Lituanian" 8 "Language_Latvian" 7 "Language_Estonian" 6 "Language_Russian" 5 "Language_Finish" 4 "Language_Icelandic" 3 "Language_Norwegian" 2 "Language_Danish" 1 "Language_Swedish" 0 "Language_English" ;
VAL_ 2432669248 PassengerDoorAjar_stat 7 "DoorAjar_stat_NotAvailable" 6 "DoorAjar_stat_Error" 2 "DoorAjar_stat_DoorOpen" 1 "DoorAjar_stat_DoorClosed" 0 "DoorAjar_stat_Idle" ;
VAL_ 2432669248 BunkB1ParkHeaterTempSw_stat 7 "A3PosSwitchStatus_NotAvailable" 6 "A3PosSwitchStatus_Error" 5 "A3PosSwitchStatus_Spare_02" 4 "A3PosSwitchStatus_Spare_01" 3 "A3PosSwitchStatus_Spare" 2 "A3PosSwitchStatus_Upper" 1 "A3PosSwitchStatus_Lower" 0 "A3PosSwitchStatus_Middle" ;
VAL_ 2432669248 AuxSwitchBbLoad5_Status 3 "InactiveActive_NotAvailable" 2 "InactiveActive_Error" 1 "InactiveActive_Active" 0 "InactiveActive_Inactive" ;
VAL_ 2432669248 AuxSwitchBbLoad3_Status 3 "InactiveActive_NotAvailable" 2 "InactiveActive_Error" 1 "InactiveActive_Active" 0 "InactiveActive_Inactive" ;
VAL_ 2432669248 BunkH2TempInc_ButtonStatus 3 "PushButtonStatus_NotAvailable" 2 "PushButtonStatus_Error" 1 "PushButtonStatus_Pushed" 0 "PushButtonStatus_Neutral" ;
VAL_ 2432669248 DayOfWeek_stat 15 "DayOfWeek_NotAvailable" 14 "DayOfWeek_Error" 13 "DayOfWeek_Spare_7" 12 "DayOfWeek_Spare_6" 11 "DayOfWeek_Spare_5" 10 "DayOfWeek_Spare_4" 9 "DayOfWeek_Spare_3" 8 "DayOfWeek_Spare_2" 7 "DayOfWeek_Spare_1" 6 "DayOfWeek_Sunday" 5 "DayOfWeek_Saturday" 4 "DayOfWeek_Friday" 3 "DayOfWeek_Thursday" 2 "DayOfWeek_Wednesday" 1 "DayOfWeek_Tuesday" 0 "DayOfWeek_Monday" ;
VAL_ 2432651584 ParkHeaterTimerReleased_stat 3 "DisableEnable_NotAvailable" 2 "DisableEnable_Error" 1 "DisableEnable_Enable" 0 "DisableEnable_Disable" ;
VAL_ 2432651584 Washing_HMI_rqst 3 "InactiveActive_NotAvailable" 2 "InactiveActive_Error" 1 "InactiveActive_Active" 0 "InactiveActive_Inactive" ;
VAL_ 2432651584 BunkH2ParkHeater_ButtonStatus 3 "PushButtonStatus_NotAvailable" 2 "PushButtonStatus_Error" 1 "PushButtonStatus_Pushed" 0 "PushButtonStatus_Neutral" ;
VAL_ 2432651584 BunkBTempDec_ButtonStatus 3 "PushButtonStatus_NotAvailable" 2 "PushButtonStatus_Error" 1 "PushButtonStatus_Pushed" 0 "PushButtonStatus_Neutral" ;
VAL_ 2432651584 AudioSystemStatus 3 "OffOn_NotAvailable" 2 "OffOn_Error" 1 "OffOn_On" 0 "OffOn_Off" ;
VAL_ 2432651584 BunkH2TempDec_ButtonStatus 3 "PushButtonStatus_NotAvailable" 2 "PushButtonStatus_Error" 1 "PushButtonStatus_Pushed" 0 "PushButtonStatus_Neutral" ;
VAL_ 2432651584 BunkBParkHeater_ButtonStatus 3 "PushButtonStatus_NotAvailable" 2 "PushButtonStatus_Error" 1 "PushButtonStatus_Pushed" 0 "PushButtonStatus_Neutral" ;
VAL_ 2432651584 BunkBTempInc_ButtonStatus 3 "PushButtonStatus_NotAvailable" 2 "PushButtonStatus_Error" 1 "PushButtonStatus_Pushed" 0 "PushButtonStatus_Neutral" ;
VAL_ 2432651584 PtosStatus 3 "PtosStatus_NotAvailable" 2 "PtosStatus_Error" 1 "PtosStatus_OneOrMorePTOEngaged" 0 "PtosStatus_NoPTOEngaged" ;
VAL_ 2432651584 BunkB1ParkHeaterBtn_stat 3 "PushButtonStatus_NotAvailable" 2 "PushButtonStatus_Error" 1 "PushButtonStatus_Pushed" 0 "PushButtonStatus_Neutral" ;
VAL_ 2432651584 BunkH2PHTimer_rqst_Timer_cmd 7 "ParkHeaterTimer_cmd_NotAvailable" 6 "ParkHeaterTimer_cmd_Error" 5 "ParkHeaterTimer_cmd_Spare_02" 4 "ParkHeaterTimer_cmd_Spare_01" 3 "ParkHeaterTimer_cmd_Spare" 2 "ParkHeaterTimer_cmd_TimerDisable" 1 "ParkHeaterTimer_cmd_TimerEnable" 0 "ParkHeaterTimer_cmd_NoAction" ;
VAL_ 2431745856 BacklightCmd 31 "BacklightCmd_NotAvailable" 30 "BacklightCmd_Error" 16 "BacklightCmd_BacklightLevel16" 15 "BacklightCmd_BacklightLevel15" 14 "BacklightCmd_BacklightLevel14" 13 "BacklightCmd_BacklightLevel13" 12 "BacklightCmd_BacklightLevel12" 11 "BacklightCmd_BacklightLevel11" 10 "BacklightCmd_BacklightLevel10" 9 "BacklightCmd_BacklightLevel9" 8 "BacklightCmd_BacklightLevel8" 7 "BacklightCmd_BacklightLevel7" 6 "BacklightCmd_BacklightLevel6" 5 "BacklightCmd_BacklightLevel5" 4 "BacklightCmd_BacklightLevel4" 3 "BacklightCmd_BacklightLevel3" 2 "BacklightCmd_BacklightLevel2" 1 "BacklightCmd_BacklightLevel1" 0 "BacklightCmd_BacklightOff" ;
VAL_ 2431745856 VehicleMode 15 "VehicleMode_NotAvailable" 14 "VehicleMode_Error" 13 "VehicleMode_Spare_7" 12 "VehicleMode_Spare_6" 11 "VehicleMode_Spare_5" 10 "VehicleMode_Spare_4" 9 "VehicleMode_Spare_3" 8 "VehicleMode_Spare_2" 7 "VehicleMode_Spare_1" 6 "VehicleMode_Running" 5 "VehicleMode_Cranking" 4 "VehicleMode_PreRunning" 3 "VehicleMode_Accessory" 2 "VehicleMode_Living" 1 "VehicleMode_Parked" 0 "VehicleMode_Hibernate" ;
VAL_ 2431745856 BunkH2OnOFF_ButtonStatus 3 "PushButtonStatus_NotAvailable" 2 "PushButtonStatus_Error" 1 "PushButtonStatus_Pushed" 0 "PushButtonStatus_Neutral" ;
VAL_ 2431745856 IntLghtModeInd_cmd_EventFlag 1 "EventFlag_High" 0 "EventFlag_Low" ;
VAL_ 2431745856 LevelControlInformation 15 "LevelControlInformation_NotAvailable" 14 "LevelControlInformation_Error" 13 "LevelControlInformation_Reserved_06" 12 "LevelControlInformation_Reserved_05" 11 "LevelControlInformation_Reserved_04" 10 "LevelControlInformation_Reserved_03" 9 "LevelControlInformation_Reserved_02" 8 "LevelControlInformation_Reserved_01" 7 "LevelControlInformation_Reserved" 6 "LevelControlInformation_LimpHome" 5 "LevelControlInformation_FerryFunction" 4 "LevelControlInformation_KneelingHeight" 3 "LevelControlInformation_DriveHeight" 2 "LevelControlInformation_DockingHeight" 1 "LevelControlInformation_HeightAdjustment" 0 "LevelControlInformation_Prohibit" ;
VAL_ 2431745856 IntLghtModeInd_cmd_IL_Mode 7 "IL_Mode_NotAvailable" 6 "IL_Mode_ErrorIndicator" 5 "IL_Mode_spare_2" 4 "IL_Mode_spare_1" 3 "IL_Mode_Max" 2 "IL_Mode_Resting" 1 "IL_Mode_NightDriving" 0 "IL_Mode_OFF" ;
VAL_ 2432650304 DriverSeatBeltSwitch 3 "DriverSeatBeltSwitch_NotAvailable" 2 "DriverSeatBeltSwitch_Error" 1 "DriverSeatBeltSwitch_SeatBeltBuckledFastened" 0 "DriverSeatBeltSwitch_SeatBeltUnbuckledUnfastened" ;
VAL_ 2432650304 DriverMemory_rqst 31 "DriverMemory_rqst_Error" 30 "DriverMemory_rqst_NotAvailable" 29 "DriverMemory_rqst_Spare_07" 28 "DriverMemory_rqst_Spare_06" 27 "DriverMemory_rqst_Spare_05" 26 "DriverMemory_rqst_Spare_04" 25 "DriverMemory_rqst_Spare_03" 24 "DriverMemory_rqst_Spare_02" 23 "DriverMemory_rqst_Spare_01" 22 "DriverMemory_rqst_Spare" 21 "DriverMemory_rqst_ResetAllMemThenUseDefDriverMem" 20 "DriverMemory_rqst_ResetAndThenUseDriverMemory10" 19 "DriverMemory_rqst_ResetAndThenUseDriverMemory9" 18 "DriverMemory_rqst_ResetAndThenUseDriverMemory8" 17 "DriverMemory_rqst_ResetAndThenUseDriverMemory7" 16 "DriverMemory_rqst_ResetAndThenUseDriverMemory6" 15 "DriverMemory_rqst_ResetAndThenUseDriverMemory5" 14 "DriverMemory_rqst_ResetAndThenUseDriverMemory4" 13 "DriverMemory_rqst_ResetAndThenUseDriverMemory3" 12 "DriverMemory_rqst_ResetAndThenUseDriverMemory2" 11 "DriverMemory_rqst_ResetAndThenUseDriverMemory1" 10 "DriverMemory_rqst_UseDriverMemory10" 9 "DriverMemory_rqst_UseDriverMemory9" 8 "DriverMemory_rqst_UseDriverMemory8" 7 "DriverMemory_rqst_UseDriverMemory7" 6 "DriverMemory_rqst_UseDriverMemory6" 5 "DriverMemory_rqst_UseDriverMemory5" 4 "DriverMemory_rqst_UseDriverMemory4" 3 "DriverMemory_rqst_UseDriverMemory3" 2 "DriverMemory_rqst_UseDriverMemory2" 1 "DriverMemory_rqst_UseDriverMemory1" 0 "DriverMemory_rqst_UseDefaultDriverMemory" ;
VAL_ 2432650304 ReverseGearEngaged 3 "ReverseGearEngaged_NotAvailable" 2 "ReverseGearEngaged_Error" 1 "ReverseGearEngaged_ReverseGearEngaged" 0 "ReverseGearEngaged_ReverseGearNotEngaged" ;
VAL_ 2432650304 ParkBrakeActuationStatus 7 "ParkBrakeActuationStatus_NotAvailable" 6 "ParkBrakeActuationStatus_Error" 5 "ParkBrakeActuationStatus_SpareValue_01" 4 "ParkBrakeActuationStatus_SpareValue" 3 "ParkBrakeActuationStatus_AntiCompound" 2 "ParkBrakeActuationStatus_Parked" 1 "ParkBrakeActuationStatus_PartiallyParked" 0 "ParkBrakeActuationStatus_Released" ;
VAL_ 2432650304 ECSStandbyActive 3 "FalseTrue_NotAvaiable" 2 "FalseTrue_Error" 1 "FalseTrue_True" 0 "FalseTrue_False" ;
VAL_ 2432650304 HeightAdjustmentAllowed 3 "FalseTrue_NotAvaiable" 2 "FalseTrue_Error" 1 "FalseTrue_True" 0 "FalseTrue_False" ;
VAL_ 2432650304 SelectedTimeFormat_stat 3 "TimeFormatStat_NotAvailable" 2 "TimeFormatStat_Error" 1 "TimeFormatStat_24h" 0 "TimeFormatStat_AM_PM" ;
VAL_ 2432650304 SelectedWeightUnit_stat 3 "WeightUnit_NotAvailable" 2 "WeightUnit_Error" 1 "WeightUnit_Pound" 0 "WeightUnit_Kg" ;
VAL_ 2432650304 SelectedDateFormat_stat 7 "SelectedDateFormat_stat_NotAvailable" 6 "SelectedDateFormat_stat_Error" 5 "SelectedDateFormat_stat_Spare_02" 4 "SelectedDateFormat_stat_Spare_01" 3 "SelectedDateFormat_stat_Spare" 2 "SelectedDateFormat_stat_MonthDayYear" 1 "SelectedDateFormat_stat_DayMonthYear" 0 "SelectedDateFormat_stat_YearMonthDay" ;
VAL_ 2432650304 FuncIndIlluminationLevel 7 "FuncIndIlluminationLevel_NotAvailable" 6 "FuncIndIlluminationLevel_Error" 5 "FuncIndIlluminationLevel_Spare" 4 "FuncIndIlluminationLevel_IlluminationLevel4" 3 "FuncIndIlluminationLevel_IlluminationLevel3" 2 "FuncIndIlluminationLevel_IlluminationLevel2" 1 "FuncIndIlluminationLevel_IlluminationLevel1" 0 "FuncIndIlluminationLevel_IlluminationOff" ;
VAL_ 2432650304 WiperModeStatus 7 "WiperModeStatus_NotAvailable" 6 "WiperModeStatus_ErrorIndicator" 5 "WiperModeStatus_Spare02" 4 "WiperModeStatus_Spare01" 3 "WiperModeStatus_Spare" 2 "WiperModeStatus_HighSpeedWiping" 1 "WiperModeStatus_LowSpeedWiping" 0 "WiperModeStatus_WiperOff" ;
VAL_ 2432650304 MirrorHeatingMode 7 "MirrorHeat_NotAvailable" 6 "MirrorHeat_ErrorIndicator" 5 "MirrorHeat_SpareValue_02" 4 "MirrorHeat_SpareValue_01" 3 "MirrorHeat_SpareValue" 2 "MirrorHeat_ONExtendedMode" 1 "MirrorHeat_ONNormalMode" 0 "MirrorHeat_OFF" ;
VAL_ 2499098520 BunkParkClimateStatus 3 "OffOnSpare_NotAvailable" 2 "OffOnSpare_Spare" 1 "OffOnSpare_On" 0 "OffOnSpare_Off" ;
VAL_ 2499098520 Req24VforClimateSystem 3 "NotRequested_NotAvailable" 2 "NotRequested_Error" 1 "NotRequested_Requested" 0 "NotRequested_NotRequested" ;
VAL_ 2499098520 AuxFunCabPreCondition_Stat 7 "AuxFunCabPreCondition_Stat_NotAvailable" 6 "AuxFunCabPreCondition_Stat_Spare4" 5 "AuxFunCabPreCondition_Stat_Spare3" 4 "AuxFunCabPreCondition_Stat_Spare2" 3 "AuxFunCabPreCondition_Stat_Spare1" 2 "AuxFunCabPreCondition_Stat_Climatefeaturesdeactivated" 1 "AuxFunCabPreCondition_Stat_Climatefeaturesactivated" 0 "AuxFunCabPreCondition_Stat_Idle" ;
VAL_ 2499031960 CabClimateICEEnergyRqst 7 "CabClimateICEEnergyRqst_NotAvailable" 6 "CabClimateICEEnergyRqst_Error" 5 "CabClimateICEEnergyRqst_Spare4" 4 "CabClimateICEEnergyRqst_Spare3" 3 "CabClimateICEEnergyRqst_Spare2" 2 "CabClimateICEEnergyRqst_Spare1" 1 "CabClimateICEEnergyRqst_ICEenergyrequested" 0 "CabClimateICEEnergyRqst_ICEenergynotrequested" ;
VAL_ 2566356888 ACStatus 3 "OffOn_NotAvailable" 2 "OffOn_Error" 1 "OffOn_On" 0 "OffOn_Off" ;
VAL_ 2566356888 HVACBlowerLevelStat_AutoStatus 3 "OffOn_NotAvailable" 2 "OffOn_Error" 1 "OffOn_On" 0 "OffOn_Off" ;
VAL_ 2566356888 MaxDefrostStatus 3 "OffOn_NotAvailable" 2 "OffOn_Error" 1 "OffOn_On" 0 "OffOn_Off" ;
VAL_ 2566356888 BunkHVACBlwrLvlStat_AutoStatus 3 "OffOn_NotAvailable" 2 "OffOn_Error" 1 "OffOn_On" 0 "OffOn_Off" ;
VAL_ 2566356888 ClimateAirDistStatus_AutoStatus 3 "OffOn_NotAvailable" 2 "OffOn_Error" 1 "OffOn_On" 0 "OffOn_Off" ;
VAL_ 2566356888 ParkingClimateAvailability 7 "ParkingClimateAvail_NotAvailable" 6 "ParkingClimateAvail_Error" 5 "ParkingClimateAvail_Spare3" 4 "ParkingClimateAvail_Spare2" 3 "ParkingClimateAvail_SystemNotAvailDueTolowFuel" 2 "ParkingClimateAvail_SystemNotAvailDueToRolloversensor" 1 "ParkingClimateAvail_SystemNotAvailDueToParkingBrake" 0 "ParkingClimateAvail_SystemAvailable" ;
VAL_ 2566356888 BunkClimatePowerStatus 3 "OffOn_NotAvailable" 2 "OffOn_Error" 1 "OffOn_On" 0 "OffOn_Off" ;
VAL_ 2566356888 ClimateAutoStatus 7 "ClimateAutoStatus_NotAvailable" 6 "ClimateAutoStatus_Error" 5 "ClimateAutoStatus_Spare3" 4 "ClimateAutoStatus_Spare2" 3 "ClimateAutoStatus_Spare1" 2 "ClimateAutoStatus_FullAuto" 1 "ClimateAutoStatus_SemiAuto" 0 "ClimateAutoStatus_AutoOffIndication" ;
VAL_ 2566356888 BunkClimateAutoStatus 7 "ClimateAutoStatus_NotAvailable" 6 "ClimateAutoStatus_Error" 5 "ClimateAutoStatus_Spare3" 4 "ClimateAutoStatus_Spare2" 3 "ClimateAutoStatus_Spare1" 2 "ClimateAutoStatus_FullAuto" 1 "ClimateAutoStatus_SemiAuto" 0 "ClimateAutoStatus_AutoOffIndication" ;
VAL_ 2566356888 ClimatePowerStatus 3 "OffOn_NotAvailable" 2 "OffOn_Error" 1 "OffOn_On" 0 "OffOn_Off" ;
VAL_ 2566356888 AirRecirculationStatus 3 "OffOn_NotAvailable" 2 "OffOn_Error" 1 "OffOn_On" 0 "OffOn_Off" ;
VAL_ 2566356888 BunkACStatus 3 "OffOn_NotAvailable" 2 "OffOn_Error" 1 "OffOn_On" 0 "OffOn_Off" ;
VAL_ 2561091992 CabCoolingLoadStaus 3 "CabCoolingLoadStaus_NotAvailable" 2 "CabCoolingLoadStaus_Spare" 1 "CabCoolingLoadStaus_Overload" 0 "CabCoolingLoadStaus_Ok" ;
VAL_ 2432641688 ParkClimTimerStat_Type 7 "TimerType_NotAvailable" 6 "TimerType_Error" 5 "TimerType_Spare3" 4 "TimerType_Spare2" 3 "TimerType_Spare1" 2 "TimerType_CabClimateTimerWithStartTime" 1 "TimerType_EngineTimerWithReadyTime" 0 "TimerType_CabClimateTimerWithReadyTime" ;
VAL_ 2432641688 ParkClimTimerStat_Rec 1 "Rec_Recurrent" 0 "Rec_Once" ;
VAL_ 2432641688 ParkClimTimerStat_Tue 1 "NotSelectedSelected_Selected" 0 "NotSelectedSelected_NotSelected" ;
VAL_ 2432641688 ParkClimTimerStat_Thu 1 "NotSelectedSelected_Selected" 0 "NotSelectedSelected_NotSelected" ;
VAL_ 2432641688 ParkClimTimerStat_Sat 1 "NotSelectedSelected_Selected" 0 "NotSelectedSelected_NotSelected" ;
VAL_ 2432641688 ParkClimTimerStat_Status 3 "ParkHeaterTimer_Status_NotAvailable" 2 "ParkHeaterTimer_Status_TimerDeleted" 1 "ParkHeaterTimer_Status_TimerNotActivated" 0 "ParkHeaterTimer_Status_TimerActivated" ;
VAL_ 2432641688 ParkClimTimerStat_Wed 1 "NotSelectedSelected_Selected" 0 "NotSelectedSelected_NotSelected" ;
VAL_ 2432641688 ParkClimTimerStat_Sun 1 "NotSelectedSelected_Selected" 0 "NotSelectedSelected_NotSelected" ;
VAL_ 2432641688 ParkClimTimerStat_Fri 1 "NotSelectedSelected_Selected" 0 "NotSelectedSelected_NotSelected" ;
VAL_ 2432641688 ParkClimTimerStat_MinRes 7 "MinRes_NotAvailable" 6 "MinRes_Error" 5 "MinRes_NoMinutesResolution" 4 "MinRes_30Minutes" 3 "MinRes_15Minutes" 2 "MinRes_10Minutes" 1 "MinRes_5Minutes" 0 "MinRes_1Minutes" ;
VAL_ 2432641688 ParkClimTimerStat_Mon 1 "NotSelectedSelected_Selected" 0 "NotSelectedSelected_NotSelected" ;
VAL_ 2432640664 PHTimer2_stat_Recurrence 15 "HeaterTimerRecurrence_NotAvailable" 14 "HeaterTimerRecurrence_Error" 13 "HeaterTimerRecurrence_Spare_3" 12 "HeaterTimerRecurrence_Spare_2" 11 "HeaterTimerRecurrence_Spare_1" 10 "HeaterTimerRecurrence_Sundays" 9 "HeaterTimerRecurrence_Saturdays" 8 "HeaterTimerRecurrence_Fridays" 7 "HeaterTimerRecurrence_Thursdays" 6 "HeaterTimerRecurrence_Wednesdays" 5 "HeaterTimerRecurrence_Tuesdays" 4 "HeaterTimerRecurrence_Mondays" 3 "HeaterTimerRecurrence_Weekends" 2 "HeaterTimerRecurrence_AllWeekdays" 1 "HeaterTimerRecurrence_Daily" 0 "HeaterTimerRecurrence_None" ;
VAL_ 2432640664 PHTimer3_stat_Temp 31 "TemperatureRqstIndication_cmd_NotAvailable" 30 "TemperatureRqstIndication_cmd_Error" 29 "TemperatureRqstIndication_cmd_Spare_01" 28 "TemperatureRqstIndication_cmd_Spare" 27 "TemperatureRqstIndication_cmd_Max" 26 "TemperatureRqstIndication_cmd_29C" 25 "TemperatureRqstIndication_cmd_28C" 24 "TemperatureRqstIndication_cmd_27C" 23 "TemperatureRqstIndication_cmd_26C" 22 "TemperatureRqstIndication_cmd_25_5C" 21 "TemperatureRqstIndication_cmd_25C" 20 "TemperatureRqstIndication_cmd_24_5C" 19 "TemperatureRqstIndication_cmd_24C" 18 "TemperatureRqstIndication_cmd_23_5C" 17 "TemperatureRqstIndication_cmd_23C" 16 "TemperatureRqstIndication_cmd_22_5C" 15 "TemperatureRqstIndication_cmd_22C" 14 "TemperatureRqstIndication_cmd_21_5C" 13 "TemperatureRqstIndication_cmd_21C" 12 "TemperatureRqstIndication_cmd_20_5C" 11 "TemperatureRqstIndication_cmd_20C" 10 "TemperatureRqstIndication_cmd_19_5C" 9 "TemperatureRqstIndication_cmd_19C" 8 "TemperatureRqstIndication_cmd_18_5C" 7 "TemperatureRqstIndication_cmd_18C" 6 "TemperatureRqstIndication_cmd_17_5C" 5 "TemperatureRqstIndication_cmd_17C" 4 "TemperatureRqstIndication_cmd_16_5C" 3 "TemperatureRqstIndication_cmd_16C" 2 "TemperatureRqstIndication_cmd_15C" 1 "TemperatureRqstIndication_cmd_Min" 0 "TemperatureRqstIndication_cmd_NoTempDisplayed" ;
VAL_ 2432640664 PHTimer3_stat_Status 3 "ParkHeaterTimer_Status_NotAvailable" 2 "ParkHeaterTimer_Status_TimerDeleted" 1 "ParkHeaterTimer_Status_TimerNotActivated" 0 "ParkHeaterTimer_Status_TimerActivated" ;
VAL_ 2432640664 PHTimer2_stat_StartDay 15 "HeaterTimerStartDay_NotAvailable" 14 "HeaterTimerStartDay_Error" 13 "HeaterTimerStartDay_Spare_05" 12 "HeaterTimerStartDay_Spare_04" 11 "HeaterTimerStartDay_Spare_03" 10 "HeaterTimerStartDay_Spare_02" 9 "HeaterTimerStartDay_Spare_01" 8 "HeaterTimerStartDay_Spare" 7 "HeaterTimerStartDay_Sunday" 6 "HeaterTimerStartDay_Saturday" 5 "HeaterTimerStartDay_Friday" 4 "HeaterTimerStartDay_Thursday" 3 "HeaterTimerStartDay_Wednesday" 2 "HeaterTimerStartDay_Tuesday" 1 "HeaterTimerStartDay_Monday" 0 "HeaterTimerStartDay_NotUsed" ;
VAL_ 2432640664 PHTimer2_stat_Temp 31 "TemperatureRqstIndication_cmd_NotAvailable" 30 "TemperatureRqstIndication_cmd_Error" 29 "TemperatureRqstIndication_cmd_Spare_01" 28 "TemperatureRqstIndication_cmd_Spare" 27 "TemperatureRqstIndication_cmd_Max" 26 "TemperatureRqstIndication_cmd_29C" 25 "TemperatureRqstIndication_cmd_28C" 24 "TemperatureRqstIndication_cmd_27C" 23 "TemperatureRqstIndication_cmd_26C" 22 "TemperatureRqstIndication_cmd_25_5C" 21 "TemperatureRqstIndication_cmd_25C" 20 "TemperatureRqstIndication_cmd_24_5C" 19 "TemperatureRqstIndication_cmd_24C" 18 "TemperatureRqstIndication_cmd_23_5C" 17 "TemperatureRqstIndication_cmd_23C" 16 "TemperatureRqstIndication_cmd_22_5C" 15 "TemperatureRqstIndication_cmd_22C" 14 "TemperatureRqstIndication_cmd_21_5C" 13 "TemperatureRqstIndication_cmd_21C" 12 "TemperatureRqstIndication_cmd_20_5C" 11 "TemperatureRqstIndication_cmd_20C" 10 "TemperatureRqstIndication_cmd_19_5C" 9 "TemperatureRqstIndication_cmd_19C" 8 "TemperatureRqstIndication_cmd_18_5C" 7 "TemperatureRqstIndication_cmd_18C" 6 "TemperatureRqstIndication_cmd_17_5C" 5 "TemperatureRqstIndication_cmd_17C" 4 "TemperatureRqstIndication_cmd_16_5C" 3 "TemperatureRqstIndication_cmd_16C" 2 "TemperatureRqstIndication_cmd_15C" 1 "TemperatureRqstIndication_cmd_Min" 0 "TemperatureRqstIndication_cmd_NoTempDisplayed" ;
VAL_ 2432640664 PHTimer2_stat_Status 3 "ParkHeaterTimer_Status_NotAvailable" 2 "ParkHeaterTimer_Status_TimerDeleted" 1 "ParkHeaterTimer_Status_TimerNotActivated" 0 "ParkHeaterTimer_Status_TimerActivated" ;
VAL_ 2432640664 PHTimer3_stat_Recurrence 15 "HeaterTimerRecurrence_NotAvailable" 14 "HeaterTimerRecurrence_Error" 13 "HeaterTimerRecurrence_Spare_3" 12 "HeaterTimerRecurrence_Spare_2" 11 "HeaterTimerRecurrence_Spare_1" 10 "HeaterTimerRecurrence_Sundays" 9 "HeaterTimerRecurrence_Saturdays" 8 "HeaterTimerRecurrence_Fridays" 7 "HeaterTimerRecurrence_Thursdays" 6 "HeaterTimerRecurrence_Wednesdays" 5 "HeaterTimerRecurrence_Tuesdays" 4 "HeaterTimerRecurrence_Mondays" 3 "HeaterTimerRecurrence_Weekends" 2 "HeaterTimerRecurrence_AllWeekdays" 1 "HeaterTimerRecurrence_Daily" 0 "HeaterTimerRecurrence_None" ;
VAL_ 2432640664 PHTimer3_stat_StartDay 15 "HeaterTimerStartDay_NotAvailable" 14 "HeaterTimerStartDay_Error" 13 "HeaterTimerStartDay_Spare_05" 12 "HeaterTimerStartDay_Spare_04" 11 "HeaterTimerStartDay_Spare_03" 10 "HeaterTimerStartDay_Spare_02" 9 "HeaterTimerStartDay_Spare_01" 8 "HeaterTimerStartDay_Spare" 7 "HeaterTimerStartDay_Sunday" 6 "HeaterTimerStartDay_Saturday" 5 "HeaterTimerStartDay_Friday" 4 "HeaterTimerStartDay_Thursday" 3 "HeaterTimerStartDay_Wednesday" 2 "HeaterTimerStartDay_Tuesday" 1 "HeaterTimerStartDay_Monday" 0 "HeaterTimerStartDay_NotUsed" ;
VAL_ 2432644760 ExtraHeating_status 3 "OffAuto_NotAvailable" 2 "OffAuto_Error" 1 "OffAuto_AutoStart" 0 "OffAuto_Off" ;
VAL_ 2432644760 AQSmode_Status 3 "AQSMode_NotAvailable" 2 "AQSMode_Error" 1 "AQSMode_Auto" 0 "AQSMode_OFF" ;
VAL_ 2432644760 ParkingClimate_IndicationCmd 7 "ParkingClimate_IndicationCmd_NotAvailable" 6 "ParkingClimate_IndicationCmd_Error" 5 "ParkingClimate_IndicationCmd_Spare_01" 4 "ParkingClimate_IndicationCmd_ShortStopHeaterActivated" 3 "ParkingClimate_IndicationCmd_ParkCoolWithoutCompActivReducedMode" 2 "ParkingClimate_IndicationCmd_ParkCoolWithCompActivFullMode" 1 "ParkingClimate_IndicationCmd_ParkingHeaterActivated" 0 "ParkingClimate_IndicationCmd_NoSystemActivated" ;
VAL_ 2432644760 ACmode_Status 7 "ACMode_NotAvailable" 6 "ACMode_Error" 5 "ACMode_Spare_01" 4 "ACMode_Spare" 3 "ACMode_ExtraDryCabAir" 2 "ACMode_HumidCabAir" 1 "ACMode_Standard" 0 "ACMode_Economy" ;
VAL_ 2432644760 ShortStopHeater_cmd 3 "Request_NotAvailable" 2 "Request_Error" 1 "Request_RequestActive" 0 "Request_NotRequested" ;
VAL_ 2432644760 PHTimer1_stat_Status 3 "ParkHeaterTimer_Status_NotAvailable" 2 "ParkHeaterTimer_Status_TimerDeleted" 1 "ParkHeaterTimer_Status_TimerNotActivated" 0 "ParkHeaterTimer_Status_TimerActivated" ;
VAL_ 2432644760 PHTimer1_stat_StartDay 15 "HeaterTimerStartDay_NotAvailable" 14 "HeaterTimerStartDay_Error" 13 "HeaterTimerStartDay_Spare_05" 12 "HeaterTimerStartDay_Spare_04" 11 "HeaterTimerStartDay_Spare_03" 10 "HeaterTimerStartDay_Spare_02" 9 "HeaterTimerStartDay_Spare_01" 8 "HeaterTimerStartDay_Spare" 7 "HeaterTimerStartDay_Sunday" 6 "HeaterTimerStartDay_Saturday" 5 "HeaterTimerStartDay_Friday" 4 "HeaterTimerStartDay_Thursday" 3 "HeaterTimerStartDay_Wednesday" 2 "HeaterTimerStartDay_Tuesday" 1 "HeaterTimerStartDay_Monday" 0 "HeaterTimerStartDay_NotUsed" ;
VAL_ 2432644760 ReqVehTVSforClimateSystem 3 "NotRequested_NotAvailable" 2 "NotRequested_Error" 1 "NotRequested_Requested" 0 "NotRequested_NotRequested" ;
VAL_ 2432644760 AutoBlowerLevel_Status 7 "AutoBlowerLevel_NotAvailable" 6 "AutoBlowerLevel_Error" 5 "AutoBlowerLevel_Spare_02" 4 "AutoBlowerLevel_Spare_01" 3 "AutoBlowerLevel_Spare" 2 "AutoBlowerLevel_Low" 1 "AutoBlowerLevel_Normal" 0 "AutoBlowerLevel_High" ;
VAL_ 2432644760 PHTimer1_stat_Temp 31 "TemperatureRqstIndication_cmd_NotAvailable" 30 "TemperatureRqstIndication_cmd_Error" 29 "TemperatureRqstIndication_cmd_Spare_01" 28 "TemperatureRqstIndication_cmd_Spare" 27 "TemperatureRqstIndication_cmd_Max" 26 "TemperatureRqstIndication_cmd_29C" 25 "TemperatureRqstIndication_cmd_28C" 24 "TemperatureRqstIndication_cmd_27C" 23 "TemperatureRqstIndication_cmd_26C" 22 "TemperatureRqstIndication_cmd_25_5C" 21 "TemperatureRqstIndication_cmd_25C" 20 "TemperatureRqstIndication_cmd_24_5C" 19 "TemperatureRqstIndication_cmd_24C" 18 "TemperatureRqstIndication_cmd_23_5C" 17 "TemperatureRqstIndication_cmd_23C" 16 "TemperatureRqstIndication_cmd_22_5C" 15 "TemperatureRqstIndication_cmd_22C" 14 "TemperatureRqstIndication_cmd_21_5C" 13 "TemperatureRqstIndication_cmd_21C" 12 "TemperatureRqstIndication_cmd_20_5C" 11 "TemperatureRqstIndication_cmd_20C" 10 "TemperatureRqstIndication_cmd_19_5C" 9 "TemperatureRqstIndication_cmd_19C" 8 "TemperatureRqstIndication_cmd_18_5C" 7 "TemperatureRqstIndication_cmd_18C" 6 "TemperatureRqstIndication_cmd_17_5C" 5 "TemperatureRqstIndication_cmd_17C" 4 "TemperatureRqstIndication_cmd_16_5C" 3 "TemperatureRqstIndication_cmd_16C" 2 "TemperatureRqstIndication_cmd_15C" 1 "TemperatureRqstIndication_cmd_Min" 0 "TemperatureRqstIndication_cmd_NoTempDisplayed" ;
VAL_ 2432644760 PHCleanStatFeedback 3 "ActiveStatus_NotAvailable" 2 "ActiveStatus_Error" 1 "ActiveStatus_Active" 0 "ActiveStatus_NotActive" ;
VAL_ 2432644760 PHTimer1_stat_Recurrence 15 "HeaterTimerRecurrence_NotAvailable" 14 "HeaterTimerRecurrence_Error" 13 "HeaterTimerRecurrence_Spare_3" 12 "HeaterTimerRecurrence_Spare_2" 11 "HeaterTimerRecurrence_Spare_1" 10 "HeaterTimerRecurrence_Sundays" 9 "HeaterTimerRecurrence_Saturdays" 8 "HeaterTimerRecurrence_Fridays" 7 "HeaterTimerRecurrence_Thursdays" 6 "HeaterTimerRecurrence_Wednesdays" 5 "HeaterTimerRecurrence_Tuesdays" 4 "HeaterTimerRecurrence_Mondays" 3 "HeaterTimerRecurrence_Weekends" 2 "HeaterTimerRecurrence_AllWeekdays" 1 "HeaterTimerRecurrence_Daily" 0 "HeaterTimerRecurrence_None" ;
VAL_ 2432644760 AutoDefogmode_Status 7 "AutoDefogmode_NotAvailable" 6 "AutoDefogmode_Error" 5 "AutoDefogmode_Spare_01" 4 "AutoDefogmode_Spare" 3 "AutoDefogmode_Moderate" 2 "AutoDefogmode_Normal" 1 "AutoDefogmode_Sensitive" 0 "AutoDefogmode_OFF" ;
VAL_ 2432645496 ParkHeaterCooler_ButtonStatus 3 "PushButtonStatus_NotAvailable" 2 "PushButtonStatus_Error" 1 "PushButtonStatus_Pushed" 0 "PushButtonStatus_Neutral" ;
VAL_ 2432645496 AirFlowSelectionUpBtn_stat 3 "PushButtonStatus_NotAvailable" 2 "PushButtonStatus_Error" 1 "PushButtonStatus_Pushed" 0 "PushButtonStatus_Neutral" ;
VAL_ 2432645496 Auto_ButtonStatus 3 "PushButtonStatus_NotAvailable" 2 "PushButtonStatus_Error" 1 "PushButtonStatus_Pushed" 0 "PushButtonStatus_Neutral" ;
VAL_ 2432645496 Temperature_FreeWheelStatus 15 "FreeWheel_Status_NotAvailable" 14 "FreeWheel_Status_Error" 13 "FreeWheel_Status_Spare" 12 "FreeWheel_Status_6StepsCounterClockwise" 11 "FreeWheel_Status_5StepsCounterClockwise" 10 "FreeWheel_Status_4StepsCounterClockwise" 9 "FreeWheel_Status_3StepsCounterClockwise" 8 "FreeWheel_Status_2StepsCounterClockwise" 7 "FreeWheel_Status_1StepCounterClockwise" 6 "FreeWheel_Status_6StepsClockwise" 5 "FreeWheel_Status_5StepsClockwise" 4 "FreeWheel_Status_4StepsClockwise" 3 "FreeWheel_Status_3StepsClockwise" 2 "FreeWheel_Status_2StepsClockwise" 1 "FreeWheel_Status_1StepClockwise" 0 "FreeWheel_Status_NoMovement" ;
VAL_ 2432645496 AC_ButtonStatus 3 "PushButtonStatus_NotAvailable" 2 "PushButtonStatus_Error" 1 "PushButtonStatus_Pushed" 0 "PushButtonStatus_Neutral" ;
VAL_ 2432645496 WindscreenDefrost_ButtonStatus 3 "PushButtonStatus_NotAvailable" 2 "PushButtonStatus_Error" 1 "PushButtonStatus_Pushed" 0 "PushButtonStatus_Neutral" ;
VAL_ 2432645496 Recirc_ButtonStatus 3 "PushButtonStatus_NotAvailable" 2 "PushButtonStatus_Error" 1 "PushButtonStatus_Pushed" 0 "PushButtonStatus_Neutral" ;
VAL_ 2432645496 AirFlowSelectionDownBtn_stat 3 "PushButtonStatus_NotAvailable" 2 "PushButtonStatus_Error" 1 "PushButtonStatus_Pushed" 0 "PushButtonStatus_Neutral" ;
VAL_ 2432645496 AirFlowSelectionFrontBtn_stat 3 "PushButtonStatus_NotAvailable" 2 "PushButtonStatus_Error" 1 "PushButtonStatus_Pushed" 0 "PushButtonStatus_Neutral" ;
VAL_ 2432645496 AirBlowerSpeed_FreeWheelStatus 15 "FreeWheel_Status_NotAvailable" 14 "FreeWheel_Status_Error" 13 "FreeWheel_Status_Spare" 12 "FreeWheel_Status_6StepsCounterClockwise" 11 "FreeWheel_Status_5StepsCounterClockwise" 10 "FreeWheel_Status_4StepsCounterClockwise" 9 "FreeWheel_Status_3StepsCounterClockwise" 8 "FreeWheel_Status_2StepsCounterClockwise" 7 "FreeWheel_Status_1StepCounterClockwise" 6 "FreeWheel_Status_6StepsClockwise" 5 "FreeWheel_Status_5StepsClockwise" 4 "FreeWheel_Status_4StepsClockwise" 3 "FreeWheel_Status_3StepsClockwise" 2 "FreeWheel_Status_2StepsClockwise" 1 "FreeWheel_Status_1StepClockwise" 0 "FreeWheel_Status_NoMovement" ;
VAL_ 2432639640 ACmode_IndicationCmd 1 "IndicationCmd_ONLEDActivated" 0 "IndicationCmd_OFFLEDNotActivated" ;
VAL_ 2432639640 PHTimer_rqst_SetAlarmOper 7 "SetAlarmOperation_NotAvailable" 6 "SetAlarmOperation_Error" 5 "SetAlarmOperation_Spare_02" 4 "SetAlarmOperation_Spare_01" 3 "SetAlarmOperation_Reset" 2 "SetAlarmOperation_Continue" 1 "SetAlarmOperation_Stop" 0 "SetAlarmOperation_Start" ;
VAL_ 2432639640 AirBleedValveCtrl 3 "ClosedOpen_NotAvailable" 2 "ClosedOpen_Error" 1 "ClosedOpen_Open" 0 "ClosedOpen_Closed" ;
VAL_ 2432639640 ParkingHeaterCleaning_Rqst 3 "Request_NotAvailable" 2 "Request_Error" 1 "Request_RequestActive" 0 "Request_NotRequested" ;
VAL_ 2432639640 ParkingHeater_IndicationCmd 1 "IndicationCmd_ONLEDActivated" 0 "IndicationCmd_OFFLEDNotActivated" ;
VAL_ 2432639640 AC_CompressorClutchCmd 3 "DisengageEngage_NotAvailable" 2 "DisengageEngage_Error" 1 "DisengageEngage_Engage" 0 "DisengageEngage_Disengage" ;
VAL_ 2432639640 PHTimer_rqst_DayOfWeekRq 15 "DayOfWeekRq_NotAvailable" 14 "DayOfWeekRq_Error" 13 "DayOfWeekRq_Spare_7" 12 "DayOfWeekRq_Spare_6" 11 "DayOfWeekRq_Spare_5" 10 "DayOfWeekRq_Spare_4" 9 "DayOfWeekRq_Spare_3" 8 "DayOfWeekRq_Spare_2" 7 "DayOfWeekRq_NoDay" 6 "DayOfWeekRq_Sunday" 5 "DayOfWeekRq_Saturday" 4 "DayOfWeekRq_Friday" 3 "DayOfWeekRq_Thursday" 2 "DayOfWeekRq_Wednesday" 1 "DayOfWeekRq_Tuesday" 0 "DayOfWeekRq_Monday" ;
VAL_ 2432637336 TemperatureRqstIndication_cmd 31 "TemperatureRqstIndication_cmd_NotAvailable" 30 "TemperatureRqstIndication_cmd_Error" 29 "TemperatureRqstIndication_cmd_Spare_01" 28 "TemperatureRqstIndication_cmd_Spare" 27 "TemperatureRqstIndication_cmd_Max" 26 "TemperatureRqstIndication_cmd_29C" 25 "TemperatureRqstIndication_cmd_28C" 24 "TemperatureRqstIndication_cmd_27C" 23 "TemperatureRqstIndication_cmd_26C" 22 "TemperatureRqstIndication_cmd_25_5C" 21 "TemperatureRqstIndication_cmd_25C" 20 "TemperatureRqstIndication_cmd_24_5C" 19 "TemperatureRqstIndication_cmd_24C" 18 "TemperatureRqstIndication_cmd_23_5C" 17 "TemperatureRqstIndication_cmd_23C" 16 "TemperatureRqstIndication_cmd_22_5C" 15 "TemperatureRqstIndication_cmd_22C" 14 "TemperatureRqstIndication_cmd_21_5C" 13 "TemperatureRqstIndication_cmd_21C" 12 "TemperatureRqstIndication_cmd_20_5C" 11 "TemperatureRqstIndication_cmd_20C" 10 "TemperatureRqstIndication_cmd_19_5C" 9 "TemperatureRqstIndication_cmd_19C" 8 "TemperatureRqstIndication_cmd_18_5C" 7 "TemperatureRqstIndication_cmd_18C" 6 "TemperatureRqstIndication_cmd_17_5C" 5 "TemperatureRqstIndication_cmd_17C" 4 "TemperatureRqstIndication_cmd_16_5C" 3 "TemperatureRqstIndication_cmd_16C" 2 "TemperatureRqstIndication_cmd_15C" 1 "TemperatureRqstIndication_cmd_Min" 0 "TemperatureRqstIndication_cmd_NoTempDisplayed" ;
VAL_ 2432637336 MirrorHeatNormModeBtn_stat 3 "PushButtonStatus_NotAvailable" 2 "PushButtonStatus_Error" 1 "PushButtonStatus_Pushed" 0 "PushButtonStatus_Neutral" ;
VAL_ 2432637336 WindscreenDefrostInd_cmd 1 "IndicationCmd_ONLEDActivated" 0 "IndicationCmd_OFFLEDNotActivated" ;
SIG_GROUP_ 2432651584 BunkH2PHTimer_rqst_sg 1 : BunkH2PHTimer_rqst_StartTimeMin BunkH2PHTimer_rqst_DurnTimeMin BunkH2PHTimer_rqst_StartTimeHr BunkH2PHTimer_rqst_DurnTimeHr BunkH2PHTimer_rqst_Timer_cmd;
SIG_GROUP_ 2431745856 IntLghtModeInd_cmd_sg 1 : IntLghtModeInd_cmd_EventFlag IntLghtModeInd_cmd_IL_Mode;
SIG_GROUP_ 2566356888 BunkHVACBlwrLvlStat_sg 1 : BunkHVACBlwrLvlStat_AutoStatus BunkHVACBlwrLvlStat_BlowerLevel;
SIG_GROUP_ 2566356888 HVACBlowerLevelStat_sg 1 : HVACBlowerLevelStat_AutoStatus HVACBlowerLevelStat_BlowerLevel;
SIG_GROUP_ 2566356888 ClimateAirDistStatus_sg 1 : ClimateAirDistStatus_Defrost ClimateAirDistStatus_Floor ClimateAirDistStatus_AutoStatus ClimateAirDistStatus_Vent;
SIG_GROUP_ 2561091992 CabClimateFnRqst_sg 1 : CabClimateFnRqst_FnNum CabClimateFnRqst_FnPower;
SIG_GROUP_ 2432641688 ParkClimTimerStat_sg 1 : ParkClimTimerStat_Type ParkClimTimerStat_Rec ParkClimTimerStat_Tue ParkClimTimerStat_Thu ParkClimTimerStat_TimerNr ParkClimTimerStat_TotalNoTimers ParkClimTimerStat_Sat ParkClimTimerStat_Min ParkClimTimerStat_Status ParkClimTimerStat_Wed ParkClimTimerStat_Sun ParkClimTimerStat_Hrs ParkClimTimerStat_Temp ParkClimTimerStat_Fri ParkClimTimerStat_Dur ParkClimTimerStat_MinRes ParkClimTimerStat_Mon;
SIG_GROUP_ 2432640664 PHTimer3_stat_sg 1 : PHTimer3_stat_Temp PHTimer3_stat_Hours PHTimer3_stat_Status PHTimer3_stat_Minutes PHTimer3_stat_Recurrence PHTimer3_stat_StartDay;
SIG_GROUP_ 2432640664 PHTimer2_stat_sg 1 : PHTimer2_stat_Recurrence PHTimer2_stat_Hours PHTimer2_stat_StartDay PHTimer2_stat_Temp PHTimer2_stat_Status PHTimer2_stat_Minutes;
SIG_GROUP_ 2432644760 PHTimer1_stat_sg 1 : PHTimer1_stat_Minutes PHTimer1_stat_Status PHTimer1_stat_StartDay PHTimer1_stat_Duration PHTimer1_stat_Temp PHTimer1_stat_Recurrence PHTimer1_stat_Hours;
SIG_GROUP_ 2432639640 PHTimer_rqst_sg 1 : PHTimer_rqst_SetAlarmOper PHTimer_rqst_Hours PHTimer_rqst_Minutes PHTimer_rqst_DayOfWeekRq;
